VERSION ""

NS_ :

BS_:

BU_: AuxInput VT TECU TC Sprayer GPS

BO_ 2632384038 VT12_VT: 34 VT
 SG_ UnsupportedVtFunction m253 : 8|8@1+ (1,0) [0|255] "" Vector__XXX
 SG_ AssignedAttribute2OfSet1 m39 : 105|1@1+ (1,0) [0|1] "" Vector__XXX
 SG_ AssignedAttribute1OfSet1 m39 : 104|1@1+ (1,0) [0|1] "" Vector__XXX
 SG_ FunctionAttributeOfSet1 m39 : 96|8@1+ (1,0) [0|255] "" Vector__XXX
 SG_ AuxiliaryFunctionObjectID m36 : 96|16@1+ (1,0) [0|65535] "" Vector__XXX
 SG_ NumberOfInstancesOfSet1 m39 : 88|8@1+ (1,0) [0|255] "" Vector__XXX
 SG_ NumberOfDifferentSetsOfUnit1 m39 : 80|8@1+ (1,0) [0|255] "" Vector__XXX
 SG_ AuxiliaryInputObjectID m36 : 80|16@1+ (1,0) [0|65535] "" Vector__XXX
 SG_ StoreAsPreferredAssignment m36 : 79|1@1+ (1,0) [0|1] "" Vector__XXX
 SG_ ErrorCodeChangeAttribute5 m175 : 76|1@1+ (1,0) [0|1] "" Vector__XXX
 SG_ AuxiliaryFunctionType m36 : 72|4@1+ (1,0) [0|15] "" Vector__XXX
 SG_ SelfConfigurableAddress m36 : 71|1@1+ (1,0) [0|1] "" Vector__XXX
 SG_ DeviceClassInstance m36 : 67|4@1+ (1,0) [0|15] "" Vector__XXX
 SG_ IndustryGroup m36 : 64|3@1+ (1,0) [0|7] "" Vector__XXX
 SG_ FontType_ProportionalFont m195 : 63|1@1+ (1,0) [0|1] "" Vector__XXX
 SG_ FontType_FlashHidden m195 : 62|1@1+ (1,0) [0|1] "" Vector__XXX
 SG_ FontType_FlashInverted m195 : 61|1@1+ (1,0) [0|1] "" Vector__XXX
 SG_ FontType_InvertedText m195 : 60|1@1+ (1,0) [0|1] "" Vector__XXX
 SG_ ErrorCodeChangePolygonScale5 m183 : 60|1@1+ (1,0) [0|1] "" Vector__XXX
 SG_ FontType_ItalicsText m195 : 59|1@1+ (1,0) [0|1] "" Vector__XXX
 SG_ FontType_UnderlinedText m195 : 58|1@1+ (1,0) [0|1] "" Vector__XXX
 SG_ FontType_CrossedOutText m195 : 57|1@1+ (1,0) [0|1] "" Vector__XXX
 SG_ DeviceClass m36 : 57|7@1+ (1,0) [0|127] "" Vector__XXX
 SG_ OperatingState2 m38 : 57|1@1+ (1,0) [0|1] "" Vector__XXX
 SG_ VTFunctionCode m254 : 56|8@1+ (1,0) [0|255] "" Vector__XXX
 SG_ FontType_BoldText m195 : 56|1@1+ (1,0) [0|1] "" Vector__XXX
 SG_ NumberOfPhysicalSoftKeys m194 : 56|8@1+ (1,0) [0|255] "" Vector__XXX
 SG_ NumberOfRanges m193 : 56|8@1+ (1,0) [0|255] "" Vector__XXX
 SG_ ErrorCodeChangePolygonScale1 m183 : 56|1@1+ (1,0) [0|1] "" Vector__XXX
 SG_ OperatingState1 m38 : 56|1@1+ (1,0) [0|1] "" Vector__XXX
 SG_ VTBusyCode8 m254 : 55|1@1+ (1,0) [0|1] "" Vector__XXX
 SG_ FontSize_128x192 m195 : 54|1@1+ (1,0) [0|1] "" Vector__XXX
 SG_ VTBusyCode7 m254 : 54|1@1+ (1,0) [0|1] "" Vector__XXX
 SG_ FontSize_128x128 m195 : 53|1@1+ (1,0) [0|1] "" Vector__XXX
 SG_ VTBusyCode5 m254 : 52|1@1+ (1,0) [0|1] "" Vector__XXX
 SG_ FontSize_96x128 m195 : 52|1@1+ (1,0) [0|1] "" Vector__XXX
 SG_ ErrorCodeGetSupportedWideChars2 m193 : 52|1@1+ (1,0) [0|1] "" Vector__XXX
 SG_ ErrorCodeChangeListItem5 m177 : 52|1@1+ (1,0) [0|1] "" Vector__XXX
 SG_ ErrorCodeChangeListItem4 m177 : 51|1@1+ (1,0) [0|1] "" Vector__XXX
 SG_ VTBusyCode4 m254 : 51|1@1+ (1,0) [0|1] "" Vector__XXX
 SG_ FontSize_64x96 m195 : 51|1@1+ (1,0) [0|1] "" Vector__XXX
 SG_ ErrorCodeObjectPool4 m18 : 51|1@1+ (1,0) [0|1] "" Vector__XXX
 SG_ VTBusyCode3 m254 : 50|1@1+ (1,0) [0|1] "" Vector__XXX
 SG_ FontSize_64x64 m195 : 50|1@1+ (1,0) [0|1] "" Vector__XXX
 SG_ ErrorCodeChangeListItem3 m177 : 50|1@1+ (1,0) [0|1] "" Vector__XXX
 SG_ ErrorCodeObjectPool3 m18 : 50|1@1+ (1,0) [0|1] "" Vector__XXX
 SG_ VTBusyCode2 m254 : 49|1@1+ (1,0) [0|1] "" Vector__XXX
 SG_ FontSize_48x64 m195 : 49|1@1+ (1,0) [0|1] "" Vector__XXX
 SG_ ErrorCodeChangeListItem2 m177 : 49|1@1+ (1,0) [0|1] "" Vector__XXX
 SG_ ErrorCodeObjectPool2 m18 : 49|1@1+ (1,0) [0|1] "" Vector__XXX
 SG_ VTBusyCode1 m254 : 48|1@1+ (1,0) [0|1] "" Vector__XXX
 SG_ NrOfYPixelsInDataAreaMask m199 : 48|16@1+ (1,0) [0|65535] "" Vector__XXX
 SG_ FontSize_32x48 m195 : 48|1@1+ (1,0) [0|1] "" Vector__XXX
 SG_ NumberOfPossibleVirtualSoftKeys m194 : 48|8@1+ (1,0) [0|255] "" Vector__XXX
 SG_ ErrorCodeGetSupportedWideChars1 m193 : 48|1@1+ (1,0) [0|1] "" Vector__XXX
 SG_ ErrorCodeChangeListItem1 m177 : 48|1@1+ (1,0) [0|1] "" Vector__XXX
 SG_ Function m36 : 48|8@1+ (1,0) [0|255] "" Vector__XXX
 SG_ ErrorCodeObjectPool1 m18 : 48|1@1+ (1,0) [0|1] "" Vector__XXX
 SG_ VTChangeActiveMaskParentID m6 : 48|16@1+ (1,0) [0|65535] "" Vector__XXX
 SG_ ButtonKeyCode m1 : 48|8@1+ (1,0) [0|255] "" Vector__XXX
 SG_ SoftKeyCode m0 : 48|8@1+ (1,0) [0|255] "" Vector__XXX
 SG_ BooleanValue m33 : 48|8@1+ (1,0) [0|2] "" Vector__XXX
 SG_ Status_2 m9 : 48|8@1+ (1,0) [0|1] "" Vector__XXX
 SG_ ErrorCodeVTChangeSoftKeyMask6 m7 : 46|1@1+ (1,0) [0|1] "" Vector__XXX
 SG_ FontSize_32x32 m195 : 46|1@1+ (1,0) [0|1] "" Vector__XXX
 SG_ FontSize_24x32 m195 : 45|1@1+ (1,0) [0|1] "" Vector__XXX
 SG_ FontSize_16x24 m195 : 44|1@1+ (1,0) [0|1] "" Vector__XXX
 SG_ ErrorCodeChangePosInvalidError m180 : 44|1@1+ (1,0) [0|1] "" Vector__XXX
 SG_ ErrorCodeChangeSoftKeyMask5 m174 : 44|1@1+ (1,0) [0|1] "" Vector__XXX
 SG_ ErrorCodeChangeChildLocation5 m165 : 44|1@1+ (1,0) [0|1] "" Vector__XXX
 SG_ ErrorCodeVTChangeSoftKeyMask5 m7 : 44|1@1+ (1,0) [0|1] "" Vector__XXX
 SG_ ErrorCodeChangeStrValueInUse m179 : 44|1@1+ (1,0) [0|1] "" Vector__XXX
 SG_ ErrorCodeVtObjPoolError4 m240 : 43|1@1+ (1,0) [0|1] "" Vector__XXX
 SG_ FontSize_16x16 m195 : 43|1@1+ (1,0) [0|1] "" Vector__XXX
 SG_ ErrorCodeChangeStrError m179 : 43|1@1+ (1,0) [0|1] "" Vector__XXX
 SG_ ErrorCodeChangeSoftKeyMask4 m174 : 43|1@1+ (1,0) [0|1] "" Vector__XXX
 SG_ FunctionInstance m36 : 43|5@1+ (1,0) [0|31] "" Vector__XXX
 SG_ ErrorCodeVTChangeSoftKeyMask4 m7 : 43|1@1+ (1,0) [0|1] "" Vector__XXX
 SG_ ErrorCodeVtObjPoolError3 m240 : 42|1@1+ (1,0) [0|1] "" Vector__XXX
 SG_ FontSize_12x16 m195 : 42|1@1+ (1,0) [0|1] "" Vector__XXX
 SG_ ErrorCodeChangeStrTooLong m179 : 42|1@1+ (1,0) [0|1] "" Vector__XXX
 SG_ ErrorCodeChangeSoftKeyMask3 m174 : 42|1@1+ (1,0) [0|1] "" Vector__XXX
 SG_ ErrorCodeVTChangeSoftKeyMask3 m7 : 42|1@1+ (1,0) [0|1] "" Vector__XXX
 SG_ ErrorCodeVtObjPoolError2 m240 : 41|1@1+ (1,0) [0|1] "" Vector__XXX
 SG_ FontSize_8x12 m195 : 41|1@1+ (1,0) [0|1] "" Vector__XXX
 SG_ ErrorCodeChangePosInvalidObject m180 : 41|1@1+ (1,0) [0|1] "" Vector__XXX
 SG_ ErrorCodeChangeStrObjectID m179 : 41|1@1+ (1,0) [0|1] "" Vector__XXX
 SG_ ErrorCodeChangeSoftKeyMask2 m174 : 41|1@1+ (1,0) [0|1] "" Vector__XXX
 SG_ ErrorCodeChangeChildLocation2 m165 : 41|1@1+ (1,0) [0|1] "" Vector__XXX
 SG_ ErrorCodeVTChangeSoftKeyMask2 m7 : 41|1@1+ (1,0) [0|1] "" Vector__XXX
 SG_ ErrorCodeVtObjPoolError1 m240 : 40|1@1+ (1,0) [0|1] "" Vector__XXX
 SG_ AcknowledgmentDeleteVersion m210 : 40|4@1+ (1,0) [0|8] "" Vector__XXX
 SG_ AcknowledgmentLoadVersion m209 : 40|4@1+ (1,0) [0|8] "" Vector__XXX
 SG_ AcknowledgmentStoreVersion m208 : 40|4@1+ (1,0) [0|8] "" Vector__XXX
 SG_ FontSize_8x8 m195 : 40|1@1+ (1,0) [0|1] "" Vector__XXX
 SG_ YDotsForSoftKeyDescriptor m194 : 40|8@1+ (1,0) [0|255] "" Vector__XXX
 SG_ NewHeigthAttribute m183 : 40|16@1+ (1,0) [0|0] "" Vector__XXX
 SG_ ErrorCodeChangePosInvalidParent m180 : 40|1@1+ (1,0) [0|1] "" Vector__XXX
 SG_ ErrorCodeChangeSoftKeyMask1 m174 : 40|1@1+ (1,0) [0|1] "" Vector__XXX
 SG_ ErrorCodeChangeChildLocation1 m165 : 40|1@1+ (1,0) [0|1] "" Vector__XXX
 SG_ Value2 m38 : 40|16@1+ (1,0) [0|65535] "" Vector__XXX
 SG_ ECUInstance m36 : 40|3@1+ (1,0) [0|7] "" Vector__XXX
 SG_ TouchState m2 : 40|8@1+ (1,0) [0|255] "" Vector__XXX
 SG_ ErrorCodeVTChangeSoftKeyMask1 m7 : 40|1@1+ (1,0) [0|1] "" Vector__XXX
 SG_ ErrorCodeSelectObject6 m162 : 37|1@1+ (1,0) [0|1] "" Vector__XXX
 SG_ ErrorCodeGraphicsContextCmd5 m184 : 36|1@1+ (1,0) [0|1] "" Vector__XXX
 SG_ ErrorCodeChangePriority3 m176 : 36|1@1+ (1,0) [0|1] "" Vector__XXX
 SG_ ErrorCodeChangeAttribute4 m175 : 35|1@1+ (1,0) [0|1] "" Vector__XXX
 SG_ ErrorCodeChangeColour3 m167 : 36|1@1+ (1,0) [0|1] "" Vector__XXX
 SG_ ErrorCodeSelectObject5 m162 : 36|1@1+ (1,0) [0|1] "" Vector__XXX
 SG_ ErrorCodeEnableDisableObj4 m161 : 36|1@1+ (1,0) [0|1] "" Vector__XXX
 SG_ ErrorCodeGraphicsContextCmd4 m184 : 35|1@1+ (1,0) [0|1] "" Vector__XXX
 SG_ ErrorCodeSelectObject4 m162 : 35|1@1+ (1,0) [0|1] "" Vector__XXX
 SG_ ErrorCodeEnableDisableObj3 m161 : 35|1@1+ (1,0) [0|1] "" Vector__XXX
 SG_ ErrorCodeHideShowObj3 m160 : 35|1@1+ (1,0) [0|1] "" Vector__XXX
 SG_ ErrorCodeGraphicsContextCmd3 m184 : 34|1@1+ (1,0) [0|1] "" Vector__XXX
 SG_ ErrorCodeChangeAttribute3 m175 : 34|1@1+ (1,0) [0|1] "" Vector__XXX
 SG_ ErrorCodeSelectObject3 m162 : 34|1@1+ (1,0) [0|1] "" Vector__XXX
 SG_ ErrorCodeEnableDisableObj2 m161 : 34|1@1+ (1,0) [0|1] "" Vector__XXX
 SG_ ErrorCodeGraphicsContextCmd2 m184 : 33|1@1+ (1,0) [0|1] "" Vector__XXX
 SG_ ErrorCodeChangePriority2 m176 : 33|1@1+ (1,0) [0|1] "" Vector__XXX
 SG_ ErrorCodeChangeAttribute2 m175 : 33|1@1+ (1,0) [0|1] "" Vector__XXX
 SG_ ErrorCodeChangeColour2 m167 : 33|1@1+ (1,0) [0|1] "" Vector__XXX
 SG_ ErrorCodeSelectObject2 m162 : 33|1@1+ (1,0) [0|1] "" Vector__XXX
 SG_ ErrorCodeEnableDisableObj1 m161 : 33|1@1+ (1,0) [0|1] "" Vector__XXX
 SG_ ErrorCodeHideShowObj2 m160 : 33|1@1+ (1,0) [0|1] "" Vector__XXX
 SG_ VisibleSoftKeyMaskObjectID m254 : 32|16@1+ (1,0) [0|65535] "" Vector__XXX
 SG_ NrOfXPixelsInDataAreaMask m199 : 32|16@1+ (1,0) [0|65535] "" Vector__XXX
 SG_ XDotsForSoftKeyDescriptor m194 : 32|8@1+ (1,0) [0|255] "" Vector__XXX
 SG_ LastWideChar m193 : 32|16@1+ (1,0) [0|65535] "" Vector__XXX
 SG_ ErrorCodeGraphicsContextCmd1 m184 : 32|1@1+ (1,0) [0|1] "" Vector__XXX
 SG_ NewObjectID m177 : 32|16@1+ (1,0) [0|65535] "" Vector__XXX
 SG_ ErrorCodeChangePriority1 m176 : 32|1@1+ (1,0) [0|1] "" Vector__XXX
 SG_ ErrorCodeChangeAttribute1 m175 : 32|1@1+ (1,0) [0|1] "" Vector__XXX
 SG_ ValueOfTheObject m168 : 32|32@1+ (1,0) [0|2704] "" Vector__XXX
 SG_ ErrorCodeChangeColour1 m167 : 32|1@1+ (1,0) [0|1] "" Vector__XXX
 SG_ ErrorCodeSelectObject1 m162 : 32|1@1+ (1,0) [0|1] "" Vector__XXX
 SG_ ErrorCodeHideShowObj1 m160 : 32|1@1+ (1,0) [0|1] "" Vector__XXX
 SG_ ObjectIdOfFaultyObject m18 : 32|16@1+ (1,0) [0|65535] "" Vector__XXX
 SG_ VTChangeActiveMaskErrorID m6 : 32|16@1+ (1,0) [0|65535] "" Vector__XXX
 SG_ VTChangeNumericValueValue m5 : 32|32@1+ (1,0) [0|4294967295] "" Vector__XXX
 SG_ VTSelectInputObjectIsEdited m3 : 32|1@1+ (1,0) [0|1] "" Vector__XXX
 SG_ ButtonObjectParentID m1 : 32|16@1+ (1,0) [0|65535] "" Vector__XXX
 SG_ KeyObjectParentID m0 : 32|16@1+ (1,0) [0|65535] "" Vector__XXX
 SG_ NumTransitionsDisabledToEnabled m33 : 32|16@1+ (1,0) [0|65535] "" Vector__XXX
 SG_ ObjectID_2 m9 : 32|16@1+ (1,0) [0|65535] "" Vector__XXX
 SG_ Hardware6 m199 : 29|1@1+ (1,0) [0|1] "" Vector__XXX
 SG_ ErrorCodeChangeFont6 m170 : 29|1@1+ (1,0) [0|1] "" Vector__XXX
 SG_ ManufacturerCode m36 : 29|11@1+ (1,0) [0|2047] "" Vector__XXX
 SG_ ErrorCodePoolDeleted m6 : 29|1@1+ (1,0) [0|1] "" Vector__XXX
 SG_ Hardware5 m199 : 28|1@1+ (1,0) [0|1] "" Vector__XXX
 SG_ ErrorCodeChangeActiveMask5 m173 : 28|1@1+ (1,0) [0|1] "" Vector__XXX
 SG_ ErrorCodeChangeFillAttributes5 m172 : 28|1@1+ (1,0) [0|1] "" Vector__XXX
 SG_ ErrorCodeChangeLineAttribute4 m171 : 28|1@1+ (1,0) [0|1] "" Vector__XXX
 SG_ ErrorCodeChangeFont5 m170 : 28|1@1+ (1,0) [0|1] "" Vector__XXX
 SG_ ErrorCodeChangeEditPoint3 m169 : 28|1@1+ (1,0) [0|1] "" Vector__XXX
 SG_ ErrorCodeObjToSize4 m166 : 28|1@1+ (1,0) [0|1] "" Vector__XXX
 SG_ ErrorCodeEscapeObj2 m146 : 28|1@1+ (1,0) [0|1] "" Vector__XXX
 SG_ ErrorCodeAnyOtherError m6 : 28|1@1+ (1,0) [0|1] "" Vector__XXX
 SG_ ErrorCodeVTEsc2 m4 : 28|1@1+ (1,0) [0|1] "" Vector__XXX
 SG_ ErrorCodeChangeNumValue4 m168 : 28|1@1+ (1,0) [0|1] "" Vector__XXX
 SG_ Hardware4 m199 : 27|1@1+ (1,0) [0|1] "" Vector__XXX
 SG_ ErrorCodeChangeActiveMask4 m173 : 27|1@1+ (1,0) [0|1] "" Vector__XXX
 SG_ ErrorCodeChangeFillAttributes4 m172 : 27|1@1+ (1,0) [0|1] "" Vector__XXX
 SG_ ErrorCodeChangeFont4 m170 : 27|1@1+ (1,0) [0|1] "" Vector__XXX
 SG_ ErrorCodeMaskOrChildObjectError m6 : 27|1@1+ (1,0) [0|1] "" Vector__XXX
 SG_ ErrorCodeChangeNumValue3 m168 : 26|1@1+ (1,0) [0|1] "" Vector__XXX
 SG_ Hardware3 m199 : 26|1@1+ (1,0) [0|1] "" Vector__XXX
 SG_ ErrorCodeChangePoygonPoint3 m182 : 26|1@1+ (1,0) [0|1] "" Vector__XXX
 SG_ ErrorCodeChangeActiveMask3 m173 : 26|1@1+ (1,0) [0|1] "" Vector__XXX
 SG_ ErrorCodeChangeFillAttributes3 m172 : 26|1@1+ (1,0) [0|1] "" Vector__XXX
 SG_ ErrorCodeChangeLineAttribute3 m171 : 26|1@1+ (1,0) [0|1] "" Vector__XXX
 SG_ ErrorCodeChangeFont3 m170 : 26|1@1+ (1,0) [0|1] "" Vector__XXX
 SG_ ErrorCodeObjToSize3 m166 : 26|1@1+ (1,0) [0|1] "" Vector__XXX
 SG_ ErrorCodeMissingObjects m6 : 26|1@1+ (1,0) [0|1] "" Vector__XXX
 SG_ ErrorCodeExecuteExtendedMacro3 m188 : 26|1@1+ (1,0) [0|1] "" Vector__XXX
 SG_ Hardware2 m199 : 25|1@1+ (1,0) [0|1] "" Vector__XXX
 SG_ ErrorCodeSelectColourMap2 m186 : 25|1@1+ (1,0) [0|1] "" Vector__XXX
 SG_ ErrorCodeChangePoygonPoint2 m182 : 25|1@1+ (1,0) [0|1] "" Vector__XXX
 SG_ ErrorCodeChangeActiveMask2 m173 : 25|1@1+ (1,0) [0|1] "" Vector__XXX
 SG_ ErrorCodeChangeFillAttributes2 m172 : 25|1@1+ (1,0) [0|1] "" Vector__XXX
 SG_ ErrorCodeChangeLineAttribute2 m171 : 25|1@1+ (1,0) [0|1] "" Vector__XXX
 SG_ ErrorCodeChangeFont2 m170 : 25|1@1+ (1,0) [0|1] "" Vector__XXX
 SG_ ErrorCodeChangeEditPoint2 m169 : 25|1@1+ (1,0) [0|1] "" Vector__XXX
 SG_ ErrorCodeChangeNumValue2 m168 : 25|1@1+ (1,0) [0|1] "" Vector__XXX
 SG_ ErrorCodeObjToSize2 m166 : 25|1@1+ (1,0) [0|1] "" Vector__XXX
 SG_ ErrorCodeExecuteExtendedMacro2 m188 : 25|1@1+ (1,0) [0|1] "" Vector__XXX
 SG_ ObjectIDOfFaultyObject m240 : 24|16@1+ (1,0) [0|65535] "" Vector__XXX
 SG_ Hardware1 m199 : 24|1@1+ (1,0) [0|1] "" Vector__XXX
 SG_ ErrorCodeSelectColourMap1 m186 : 24|1@1+ (1,0) [0|1] "" Vector__XXX
 SG_ AttributeID m185 : 24|8@1+ (1,0) [0|0] "" Vector__XXX
 SG_ SubCommandID m184 : 24|8@1+ (1,0) [0|0] "" Vector__XXX
 SG_ NewWidthAttribute m183 : 24|16@1+ (1,0) [0|65535] "" Vector__XXX
 SG_ ErrorCodeChangePoygonPoint1 m182 : 24|1@1+ (1,0) [0|1] "" Vector__XXX
 SG_ ChangeChildPositionObjectID m180 : 24|16@1+ (1,0) [0|65535] "" Vector__XXX
 SG_ ChangeStringValueObjectID m179 : 24|16@1+ (1,0) [0|65535] "" Vector__XXX
 SG_ ListIndex m177 : 24|8@1+ (1,0) [0|255] "" Vector__XXX
 SG_ NewPriority m176 : 24|8@1+ (1,0) [0|255] "" Vector__XXX
 SG_ AttributeToChangeID m175 : 24|8@1+ (1,0) [0|65535] "" Vector__XXX
 SG_ SoftKeyMaskObjectID m174 : 24|16@1+ (1,0) [0|65535] "" Vector__XXX
 SG_ ErrorCodeChangeActiveMask1 m173 : 24|1@1+ (1,0) [0|1] "" Vector__XXX
 SG_ ErrorCodeChangeFillAttributes1 m172 : 24|1@1+ (1,0) [0|1] "" Vector__XXX
 SG_ ErrorCodeChangeLineAttribute1 m171 : 24|1@1+ (1,0) [0|1] "" Vector__XXX
 SG_ ErrorCodeChangeFont1 m170 : 24|1@1+ (1,0) [0|1] "" Vector__XXX
 SG_ ErrorCodeChangeEditPoint1 m169 : 24|1@1+ (1,0) [0|1] "" Vector__XXX
 SG_ ErrorCodeChangeNumValue1 m168 : 24|1@1+ (1,0) [0|1] "" Vector__XXX
 SG_ NewBackgroundColour m167 : 24|8@1+ (1,0) [0|255] "" Vector__XXX
 SG_ ErrorCodeObjToSize1 m166 : 24|1@1+ (1,0) [0|1] "" Vector__XXX
 SG_ ChangeChildLocationObjectID m165 : 24|16@1+ (1,0) [0|65535] "" Vector__XXX
 SG_ ObjectSelectStatus m162 : 24|8@1+ (1,0) [0|2] "" Vector__XXX
 SG_ ObjectEnableStatus m161 : 24|8@1+ (1,0) [0|1] "" Vector__XXX
 SG_ ObjectShowStatus m160 : 24|8@1+ (1,0) [0|1] "" Vector__XXX
 SG_ ErrorCodeEscapeObj1 m146 : 24|1@1+ (1,0) [0|1] "" Vector__XXX
 SG_ AuxInputEnable m37 : 24|8@1+ (1,0) [0|1] "" Vector__XXX
 SG_ Value1 m38 : 24|16@1+ (1,0) [0|65535] "" Vector__XXX
 SG_ EnteredStringValue m8 : 24|8@1+ (1,0) [0|255] "" Vector__XXX
 SG_ VTChangeSoftKeyMaskObjectID m7 : 24|16@1+ (1,0) [0|65535] "" Vector__XXX
 SG_ ErrorCodeVTEsc1 m4 : 24|1@1+ (1,0) [0|1] "" Vector__XXX
 SG_ VTSelectInputObjectStatus m3 : 24|8@1+ (1,0) [0|1] "" Vector__XXX
 SG_ YPosition m2 : 24|16@1+ (1,0) [0|65535] "" Vector__XXX
 SG_ Status_1 m9 : 24|8@1+ (1,0) [0|1] "" Vector__XXX
 SG_ ErrorCodeExecuteExtendedMacro1 m188 : 24|1@1+ (1,0) [0|1] "" Vector__XXX
 SG_ ErrorCodeLockUnlockMask8 m189 : 23|1@1+ (1,0) [0|1] "" Vector__XXX
 SG_ ErrorCodeLockUnlockMask7 m189 : 22|1@1+ (1,0) [0|1] "" Vector__XXX
 SG_ ErrorCodeLockUnlockMask6 m189 : 21|1@1+ (1,0) [0|1] "" Vector__XXX
 SG_ ErrorCodeLockUnlockMask5 m189 : 20|1@1+ (1,0) [0|1] "" Vector__XXX
 SG_ ErrorCodeLockUnlockMask4 m189 : 19|1@1+ (1,0) [0|1] "" Vector__XXX
 SG_ ErrorCodeExecuteMacro3 m190 : 18|1@1+ (1,0) [0|1] "" Vector__XXX
 SG_ ErrorCodeLockUnlockMask3 m189 : 18|1@1+ (1,0) [0|1] "" Vector__XXX
 SG_ ErrorCodeExecuteMacro2 m190 : 17|1@1+ (1,0) [0|1] "" Vector__XXX
 SG_ ErrorCodeLockUnlockMask2 m189 : 17|1@1+ (1,0) [0|1] "" Vector__XXX
 SG_ NameOfAuxiliaryUnit1 m39 : 16|64@1+ (1,0) [0|0] "" Vector__XXX
 SG_ ExtendedVersionLables m211 : 16|256@1+ (1,0) [0|7.20575940379279E+016] "" Vector__XXX
 SG_ VisibleDataOrAlarmMaskObjectID m254 : 16|16@1+ (1,0) [0|65535] "" Vector__XXX
 SG_ VersionLables m224 : 16|56@1+ (1,0) [0|0] "" Vector__XXX
 SG_ SupportedGraphicMode m199 : 16|8@1+ (1,0) [0|2] "" Vector__XXX
 SG_ FirstWideChar m193 : 16|16@1+ (1,0) [0|65535] "" Vector__XXX
 SG_ MemoryStatus m192 : 16|8@1+ (1,0) [0|1] "" Vector__XXX
 SG_ ErrorCodeExecuteMacro1 m190 : 16|1@1+ (1,0) [0|1] "" Vector__XXX
 SG_ ErrorCodeLockUnlockMask1 m189 : 16|1@1+ (1,0) [0|1] "" Vector__XXX
 SG_ ParentObjectIDOfFaultyObject m18 : 16|16@1+ (1,0) [0|65535] "" Vector__XXX
 SG_ ButtonObjectID m1 : 16|16@1+ (1,0) [0|65535] "" Vector__XXX
 SG_ KeyObjectID m0 : 16|16@1+ (1,0) [0|65535] "" Vector__XXX
 SG_ AuxFunctObjOfFaultyAssignment m34 : 16|16@1- (1,0) [0|65535] "" Vector__XXX
 SG_ AnalogValue m33 : 16|16@1+ (1,0) [0|65535] "" Vector__XXX
 SG_ BckgndColourUserLayoutSoftk_0000 m196 : 16|8@1+ (1,0) [0|255] "" Vector__XXX
 SG_ ErrorCodeSetObjectLabel6 m181 : 13|1@1+ (1,0) [0|1] "" Vector__XXX
 SG_ ErrorCodeSetObjectLabel5 m181 : 12|1@1+ (1,0) [0|1] "" Vector__XXX
 SG_ ErrorCodeDeleteObjectPool2 m178 : 12|1@1+ (1,0) [0|1] "" Vector__XXX
 SG_ ErrorCodeAudioVolume2 m164 : 12|1@1+ (1,0) [0|1] "" Vector__XXX
 SG_ ErrorCodeControlAudioDevice2 m163 : 12|1@1+ (1,0) [0|1] "" Vector__XXX
 SG_ ErrorCodeEndOfObjectPool3 m18 : 12|1@1+ (1,0) [0|1] "" Vector__XXX
 SG_ AuxPreferredAssignmentRespError5 m34 : 12|1@1+ (1,0) [0|1] "" Vector__XXX
 SG_ ErrorCodeSetObjectLabel4 m181 : 11|1@1+ (1,0) [0|1] "" Vector__XXX
 SG_ AuxPreferredAssignmentRespError4 m34 : 11|1@1+ (1,0) [0|1] "" Vector__XXX
 SG_ ErrorCodeSetObjectLabel3 m181 : 10|1@1+ (1,0) [0|1] "" Vector__XXX
 SG_ AuxPreferredAssignmentRespError3 m34 : 10|1@1+ (1,0) [0|1] "" Vector__XXX
 SG_ ErrorCodeSetObjectLabel2 m181 : 9|1@1+ (1,0) [0|1] "" Vector__XXX
 SG_ AuxPreferredAssignmentRespError2 m34 : 9|1@1+ (1,0) [0|1] "" Vector__XXX
 SG_ ErrorCodeEndOfObjectPool2 m18 : 9|1@1+ (1,0) [0|1] "" Vector__XXX
 SG_ SourceAdressOfActiveWSM m254 : 8|8@1+ (1,0) [0|255] "" Vector__XXX
 SG_ ParentIDOfFaultyObject m240 : 8|16@1+ (1,0) [0|65535] "" Vector__XXX
 SG_ NrOfVersionStrings m224 : 8|8@1+ (1,0) [0|255] "" Vector__XXX
 SG_ NavigationSoftKeys m194 : 8|8@1+ (1,0) [0|254] "" Vector__XXX
 SG_ CodePlane m193 : 8|8@1+ (1,0) [0|16] "" Vector__XXX
 SG_ VersionNumberISO11783Part6 m192 : 8|8@1+ (1,0) [0|255] "" Vector__XXX
 SG_ MacroObjectID m190 : 8|8@1+ (1,0) [0|255] "" Vector__XXX
 SG_ LockUnlockCommand m189 : 8|8@1+ (1,0) [0|1] "" Vector__XXX
 SG_ ColourMapObjectID m186 : 8|16@1+ (1,0) [0|65535] "" Vector__XXX
 SG_ ObjectToGetAttributeID m185 : 8|16@1+ (1,0) [0|65535] "" Vector__XXX
 SG_ GraphicsContextObjectID m184 : 8|16@1+ (1,0) [0|65535] "" Vector__XXX
 SG_ PolygonObjectToScaleID m183 : 8|16@1+ (1,0) [0|65535] "" Vector__XXX
 SG_ PolygonObjectToChangeID m182 : 8|16@1+ (1,0) [0|65535] "" Vector__XXX
 SG_ ErrorCodeSetObjectLabel1 m181 : 8|1@1+ (1,0) [0|1] "" Vector__XXX
 SG_ ChangeChildPositionParentOb_0000 m180 : 8|16@1+ (1,0) [0|65535] "" Vector__XXX
 SG_ ErrorCodeDeleteObjectPool1 m178 : 8|1@1+ (1,0) [0|1] "" Vector__XXX
 SG_ ListInputObjectID m177 : 8|16@1+ (1,0) [0|65535] "" Vector__XXX
 SG_ AlarmMaskObjectID m176 : 8|16@1+ (1,0) [0|65535] "" Vector__XXX
 SG_ ObjectToChangeAttributeID m175 : 8|16@1+ (1,0) [0|65535] "" Vector__XXX
 SG_ DataOrAlarmMaskObjectID m174 : 8|16@1+ (1,0) [0|65535] "" Vector__XXX
 SG_ ActiveMaskObjectID m173 : 8|16@1+ (1,0) [0|0] "" Vector__XXX
 SG_ ObjectToChangeFillAttributesID m172 : 8|16@1+ (1,0) [0|65535] "" Vector__XXX
 SG_ ObjectToChangeLineAttributeID m171 : 8|16@1+ (1,0) [0|65535] "" Vector__XXX
 SG_ ObjectToChangeFontID m170 : 8|16@1+ (1,0) [0|65535] "" Vector__XXX
 SG_ ObjectToChangeEndPointID m169 : 8|16@1+ (1,0) [0|65535] "" Vector__XXX
 SG_ ObjectToChangeNumValueID m168 : 8|16@1+ (1,0) [0|65535] "" Vector__XXX
 SG_ ObjectToChangeColourID m167 : 8|16@1+ (1,0) [0|65535] "" Vector__XXX
 SG_ ObjectToSizeID m166 : 8|16@1+ (1,0) [0|65535] "" Vector__XXX
 SG_ ChangeChildLocationParentOb_0000 m165 : 8|16@1+ (1,0) [0|65535] "" Vector__XXX
 SG_ ErrorCodeAudioVolume1 m164 : 8|1@1+ (1,0) [0|1] "" Vector__XXX
 SG_ ErrorCodeControlAudioDevice1 m163 : 8|1@1+ (1,0) [0|1] "" Vector__XXX
 SG_ SelectInputObjectID m162 : 8|16@1+ (1,0) [0|65535] "" Vector__XXX
 SG_ ObjectToEnableDisableID m161 : 8|16@1+ (1,0) [0|65535] "" Vector__XXX
 SG_ ObjectToHideShowID m160 : 8|16@1+ (1,0) [0|65535] "" Vector__XXX
 SG_ ObjectEscapeID m146 : 8|16@1+ (1,0) [0|65535] "" Vector__XXX
 SG_ InputStatusObjectId m37 : 8|16@1+ (1,0) [0|255] "" Vector__XXX
 SG_ AuxPreferredAssignmentRespError1 m34 : 8|1@1+ (1,0) [0|1] "" Vector__XXX
 SG_ InputObjectId m38 : 8|16@1+ (1,0) [0|255] "" Vector__XXX
 SG_ IdentityNumber m36 : 8|21@1+ (1,0) [0|2097150] "" Vector__XXX
 SG_ ErrorCodeEndOfObjectPool1 m18 : 8|1@1+ (1,0) [0|1] "" Vector__XXX
 SG_ ObjectToChangeStringID m8 : 8|16@1+ (1,0) [0|65535] "" Vector__XXX
 SG_ VTChangeSoftKeyMaskParentID m7 : 8|16@1+ (1,0) [0|65535] "" Vector__XXX
 SG_ VTChangeActiveMaskObjectID m6 : 8|16@1+ (1,0) [0|65535] "" Vector__XXX
 SG_ VTChangeNumericValueObjectID m5 : 8|16@1+ (1,0) [0|65535] "" Vector__XXX
 SG_ VTEscObjectID m4 : 8|16@1+ (1,0) [0|65535] "" Vector__XXX
 SG_ VTSelectInputObjectID m3 : 8|16@1+ (1,0) [0|65535] "" Vector__XXX
 SG_ XPosition m2 : 8|16@1+ (1,0) [0|65535] "" Vector__XXX
 SG_ ButtonActivationCode m1 : 8|8@1+ (1,0) [0|2] "" Vector__XXX
 SG_ KeyActivationCode m0 : 8|8@1+ (1,0) [0|2] "" Vector__XXX
 SG_ TerminationCause m10 : 8|8@1+ (1,0) [0|255] "" Vector__XXX
 SG_ InputNumber m33 : 8|8@1+ (1,0) [0|250] "" Vector__XXX
 SG_ ObjectID_1 m9 : 8|16@1+ (1,0) [0|65535] "" Vector__XXX
 SG_ BckgndColourUserLayoutDataMask m196 : 8|8@1+ (1,0) [0|255] "" Vector__XXX
 SG_ NumberOfSupportedObjects m197 : 8|8@1+ (1,0) [0|255] "" Vector__XXX
 SG_ BootTime m199 : 8|8@1+ (1,0) [0|255] "s" Vector__XXX
 SG_ NumberOfAuxiliaryUnits m39 : 8|8@1+ (1,0) [0|255] "" Vector__XXX
 SG_ MacroObjectID_2 m188 : 8|16@1+ (1,0) [0|65535] "" Vector__XXX
 SG_ VTFunctionVTtoECU M : 0|8@1+ (1,0) [0|255] ""  Sprayer

BO_ 2565340800 VT21_Sprayer: 8 Sprayer
 SG_ VTFunctionECUtoVT M : 0|8@1+ (1,0) [0|255] ""  VT
 SG_ KeyActivationCode m0 : 8|8@1+ (1,0) [0|2] "" Vector__XXX
 SG_ KeyObjectParentID m0 : 32|16@1+ (1,0) [0|65535] "" Vector__XXX
 SG_ KeyObjectID m0 : 16|16@1+ (1,0) [0|65535] "" Vector__XXX
 SG_ SoftKeyCode m0 : 48|8@1+ (1,0) [0|255] "" Vector__XXX
 SG_ ButtonActivationCode m1 : 8|8@1+ (1,0) [0|2] "" Vector__XXX
 SG_ ButtonObjectID m1 : 16|16@1+ (1,0) [0|65535] "" Vector__XXX
 SG_ ButtonObjectParentID m1 : 32|16@1+ (1,0) [0|65535] "" Vector__XXX
 SG_ ButtonKeyCode m1 : 48|8@1+ (1,0) [0|255] "" Vector__XXX
 SG_ XPosition m2 : 8|16@1+ (1,0) [0|65535] "" Vector__XXX
 SG_ YPosition m2 : 24|16@1+ (1,0) [0|65535] "" Vector__XXX
 SG_ TouchState m2 : 40|8@1+ (1,0) [0|255] "" Vector__XXX
 SG_ VTSelectInputObjectID m3 : 8|16@1+ (1,0) [0|65535] "" Vector__XXX
 SG_ VTSelectInputObjectStatus m3 : 24|8@1+ (1,0) [0|1] "" Vector__XXX
 SG_ VTEscObjectID m4 : 8|16@1+ (1,0) [0|65535] "" Vector__XXX
 SG_ VTChangeNumericValueObjectID m5 : 8|16@1+ (1,0) [0|65535] "" Vector__XXX
 SG_ VTChangeNumericValueValue m5 : 32|32@1+ (1,0) [0|4294967295] "" Vector__XXX
 SG_ VTChangeActiveMaskObjectID m6 : 8|16@1+ (1,0) [0|65535] "" Vector__XXX
 SG_ VTChangeSoftKeyMaskParentID m7 : 8|16@1+ (1,0) [0|65535] "" Vector__XXX
 SG_ VTChangeSoftKeyMaskObjectID m7 : 24|16@1+ (1,0) [0|65535] "" Vector__XXX
 SG_ ObjectToChangeStringValueID m8 : 24|16@1+ (1,0) [0|65535] "" Vector__XXX
 SG_ DisplayActivationStatus1 m9 : 8|1@1+ (1,0) [0|1] "" Vector__XXX
 SG_ VisibleDataAlarmMaskID m9 : 16|16@1+ (1,0) [0|65535] "" Vector__XXX
 SG_ VisibleSoftKeyMaskID m9 : 32|16@1+ (1,0) [0|65535] "" Vector__XXX
 SG_ ObjectPoolRecord m17 : 8|56@1+ (1,0) [0|3338120000] "" Vector__XXX
 SG_ AuxiliaryFunctionObjectID m32 : 8|16@1+ (1,0) [0|65535] "" Vector__XXX
 SG_ AssignmentErrorNotAccepted m32 : 24|1@1+ (1,0) [0|1] "" Vector__XXX
 SG_ NumberOfInpuUnits m34 : 8|8@1+ (1,0) [0|255] "" Vector__XXX
 SG_ IsEnabled m33 : 48|8@1+ (1,0) [0|255] "" Vector__XXX
 SG_ AuxModelIdentification m35 : 8|16@1+ (1,0) [0|65535] "" Vector__XXX
 SG_ InputStatusObjectId m37 : 8|16@1+ (1,0) [0|255] "" Vector__XXX
 SG_ AuxInputEnable m37 : 24|8@1+ (1,0) [0|1] "" Vector__XXX
 SG_ AuxErrorInvalidInputID m37 : 32|1@1+ (1,0) [0|1] "" Vector__XXX
 SG_ AuxErrorAnyOther m37 : 33|1@1+ (1,0) [0|1] "" Vector__XXX
 SG_ ObjectToShowHideID m160 : 8|16@1+ (1,0) [0|65535] "" Vector__XXX
 SG_ ShowOrHide m160 : 24|8@1+ (1,0) [0|1] "" Vector__XXX
 SG_ ObjectoEnableDisbaleID m161 : 8|16@1+ (1,0) [0|65535] "" Vector__XXX
 SG_ EnableOrDisable m161 : 24|8@1+ (1,0) [0|1] "" Vector__XXX
 SG_ SelectInputObjectID m162 : 8|16@1+ (1,0) [0|65535] "" Vector__XXX
 SG_ SetFocusOpenForEditing m162 : 24|8@1+ (1,0) [0|255] "" Vector__XXX
 SG_ NumberOfRepetitions_Audio m163 : 8|8@1+ (1,0) [0|255] "" Vector__XXX
 SG_ Frequency_Audio m163 : 16|16@1+ (1,0) [0|65535] "hz" Vector__XXX
 SG_ OnTimeDuration_Audio m163 : 32|16@1+ (1,0) [0|65535] "ms" Vector__XXX
 SG_ OffTimeDuration_Audio m163 : 48|16@1+ (1,0) [0|65535] "ms" Vector__XXX
 SG_ AudioVolume m164 : 8|8@1+ (1,0) [0|100] "%" Vector__XXX
 SG_ ParentObjectID m165 : 8|16@1+ (1,0) [0|65535] "" Vector__XXX
 SG_ ObjectToMoveID m165 : 24|16@1+ (1,0) [0|65535] "" Vector__XXX
 SG_ XPosChangeTopLeft m165 : 40|8@1+ (1,-127) [-127|128] "" Vector__XXX
 SG_ YPosChangeTopLeft m165 : 48|8@1+ (1,-127) [-127|128] "" Vector__XXX
 SG_ ObjectToSizeID m166 : 8|16@1+ (1,0) [0|65535] "" Vector__XXX
 SG_ NewWidth m166 : 24|16@1+ (1,0) [0|65535] "" Vector__XXX
 SG_ NewHeight m166 : 40|16@1+ (1,0) [0|65535] "" Vector__XXX
 SG_ ObjectToChangeColourID m167 : 8|16@1+ (1,0) [0|65535] "" Vector__XXX
 SG_ NewBackgroundColour m167 : 24|8@1+ (1,0) [0|255] "" Vector__XXX
 SG_ ObjectToChangeNumValueID m168 : 8|16@1+ (1,0) [0|65535] "" Vector__XXX
 SG_ NewValue m168 : 32|32@1+ (1,0) [0|65535] "" Vector__XXX
 SG_ ObjectToChangeEndPointID m169 : 8|16@1+ (1,0) [0|65535] "" Vector__XXX
 SG_ Width m169 : 24|16@1+ (1,0) [0|65535] "" Vector__XXX
 SG_ Height m169 : 40|16@1+ (1,0) [0|65535] "" Vector__XXX
 SG_ LineDirection m169 : 56|8@1+ (1,0) [0|1] "" Vector__XXX
 SG_ ObjectToChangeFontID m170 : 8|16@1+ (1,0) [0|65535] "" Vector__XXX
 SG_ FontColour m170 : 24|8@1+ (1,0) [0|255] "" Vector__XXX
 SG_ FontSize m170 : 32|8@1+ (1,0) [0|255] "" Vector__XXX
 SG_ FontType m170 : 40|8@1+ (1,0) [0|255] "" Vector__XXX
 SG_ FontStyle m170 : 48|8@1+ (1,0) [0|255] "" Vector__XXX
 SG_ ObjectToChangeLineAttributesID m171 : 8|16@1+ (1,0) [0|65535] "" Vector__XXX
 SG_ LineColour m171 : 24|8@1+ (1,0) [0|255] "" Vector__XXX
 SG_ LineWidth m171 : 32|8@1+ (1,0) [0|255] "" Vector__XXX
 SG_ LineArt m171 : 40|16@1+ (1,0) [0|65535] "" Vector__XXX
 SG_ ObjectToChangeFillAttributesID m172 : 8|16@1+ (1,0) [0|65535] "" Vector__XXX
 SG_ FillType m172 : 24|8@1+ (1,0) [0|255] "" Vector__XXX
 SG_ FillColour m172 : 32|8@1+ (1,0) [0|255] "" Vector__XXX
 SG_ FillPatternObjectID m172 : 40|16@1+ (1,0) [0|65535] "" Vector__XXX
 SG_ WorkingSetObjectID m173 : 8|16@1+ (1,0) [0|65535] "" Vector__XXX
 SG_ NewActiveMaskObjectID m173 : 24|16@1+ (1,0) [0|65535] "" Vector__XXX
 SG_ MaskType m174 : 8|8@1+ (1,0) [0|255] "" Vector__XXX
 SG_ DataOrAlarmMaskObjectID m174 : 16|16@1+ (1,0) [0|65535] "" Vector__XXX
 SG_ NewSoftKeyMaskObjectID m174 : 32|16@1+ (1,0) [0|65535] "" Vector__XXX
 SG_ ObjectToChangeAttributeID m175 : 8|16@1+ (1,0) [0|65535] "" Vector__XXX
 SG_ AttributeID m175 : 24|8@1+ (1,0) [0|16777200] "" Vector__XXX
 SG_ NewAttributeValue m175 : 32|32@1+ (1,0) [0|0] "" Vector__XXX
 SG_ AlarmMaskObjectID m176 : 8|16@1+ (1,0) [0|65535] "" Vector__XXX
 SG_ NewPriority m176 : 24|8@1+ (1,0) [0|255] "" Vector__XXX
 SG_ ListInputObjectID m177 : 8|16@1+ (1,0) [0|65535] "" Vector__XXX
 SG_ ListIndex m177 : 24|8@1+ (1,0) [0|255] "" Vector__XXX
 SG_ NewObjectID m177 : 32|16@1+ (1,0) [0|65535] "" Vector__XXX
 SG_ ObjectToChangeStringValueID m179 : 8|16@1+ (1,0) [0|65535] "" Vector__XXX
 SG_ NewStringValue m179 : 24|16@1+ (1,0) [0|65535] "" Vector__XXX
 SG_ ParentObjectID m180 : 8|16@1+ (1,0) [0|65535] "" Vector__XXX
 SG_ ObjectToMoveID m180 : 24|16@1+ (1,0) [0|65535] "" Vector__XXX
 SG_ XPosChangeTopLeftLong m180 : 40|16@1- (1,0) [-32768|32767] "" Vector__XXX
 SG_ YPosChangeTopLeftLong m180 : 56|16@1- (1,0) [-32768|32767] "" Vector__XXX
 SG_ ObjectToAssociateLabelWithID m181 : 8|16@1+ (1,0) [0|65535] "" Vector__XXX
 SG_ StringVariableObjectID m181 : 24|16@1+ (1,0) [0|65535] "" Vector__XXX
 SG_ GraphicRepresentationObjectID m181 : 48|16@1+ (1,0) [0|255] "" Vector__XXX
 SG_ FontType m181 : 40|8@1+ (1,0) [0|255] "" Vector__XXX
 SG_ PolygonObjectToChangeID m182 : 8|16@1+ (1,0) [0|65535] "" Vector__XXX
 SG_ IndexOfThePointToReplace m182 : 24|8@1+ (1,0) [0|255] "" Vector__XXX
 SG_ NewValueX m182 : 32|16@1+ (1,0) [0|65535] "" Vector__XXX
 SG_ NewValueY m182 : 48|16@1+ (1,0) [0|65535] "" Vector__XXX
 SG_ PolygonObjectToScaleID m183 : 8|16@1+ (1,0) [0|65535] "" Vector__XXX
 SG_ NewWidthAttribute m183 : 24|16@1+ (1,0) [0|65535] "" Vector__XXX
 SG_ NewHeigthAttribute m183 : 40|16@1+ (1,0) [0|0] "" Vector__XXX
 SG_ GraphicsContextObjectID m184 : 8|16@1+ (1,0) [0|65535] "" Vector__XXX
 SG_ SubCommandID m184 : 24|8@1+ (1,0) [0|0] "" Vector__XXX
 SG_ ObjectToGetAttributeID m185 : 8|16@1+ (1,0) [0|65535] "" Vector__XXX
 SG_ AttributeID m185 : 24|8@1+ (1,0) [0|0] "" Vector__XXX
 SG_ ColourMapObjectID m186 : 8|16@1+ (1,0) [0|65535] "" Vector__XXX
 SG_ LockUnlockCommand m189 : 8|8@1+ (1,0) [0|1] "" Vector__XXX
 SG_ ObjectIDOfDataMaskToLock m189 : 16|16@1+ (1,0) [0|65535] "" Vector__XXX
 SG_ LockTimeout m189 : 32|16@1+ (1,0) [0|65535] "" Vector__XXX
 SG_ MacroObjecID m190 : 8|8@1+ (1,0) [0|255] "" Vector__XXX
 SG_ MemoryRequired m192 : 16|24@1+ (1,0) [0|16777200] "" Vector__XXX
 SG_ CodePlane m193 : 8|8@1+ (1,0) [0|16] "" Vector__XXX
 SG_ FirstWideChar m193 : 16|16@1+ (1,0) [0|65535] "" Vector__XXX
 SG_ LastWideChar m193 : 32|16@1+ (1,0) [0|65535] "" Vector__XXX
 SG_ VersionLabelToStore m208 : 8|56@1+ (1,0) [0|3338120000] "" Vector__XXX
 SG_ VersionLabelToLoad m209 : 8|56@1+ (1,0) [0|3338120000] "" Vector__XXX
 SG_ VersionLabelToDelete m210 : 8|56@1+ (1,0) [0|3338120000] "" Vector__XXX
 SG_ WSMaintenanceInitiating m255 : 8|1@1+ (1,0) [0|1] "" Vector__XXX
 SG_ WSMaintenanceBitmask m255 : 15|1@1+ (1,0) [0|1] "" Vector__XXX

BO_ 2565537534 RQST: 3 Vector__XXX
 SG_ RqstedPGN : 0|24@1+ (1,0) [0|16777200] ""  Sprayer,VT,TECU,TC

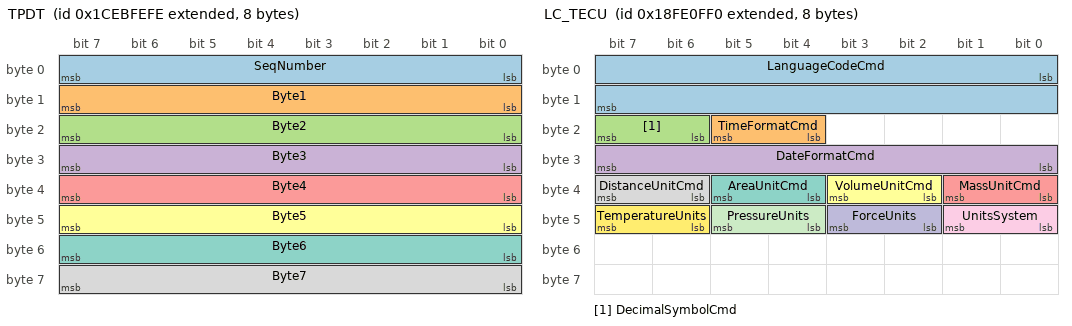
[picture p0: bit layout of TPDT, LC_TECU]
BO_ 2632711934 TPDT: 8 Vector__XXX
 SG_ SeqNumber : 0|8@1+ (1,0) [0|255] "" Vector__XXX
 SG_ Byte1 : 8|8@1+ (1,0) [0|255] "" Vector__XXX
 SG_ Byte2 : 16|8@1+ (1,0) [0|255] "" Vector__XXX
 SG_ Byte3 : 24|8@1+ (1,0) [0|255] "" Vector__XXX
 SG_ Byte4 : 32|8@1+ (1,0) [0|255] "" Vector__XXX
 SG_ Byte5 : 40|8@1+ (1,0) [0|255] "" Vector__XXX
 SG_ Byte6 : 48|8@1+ (1,0) [0|255] "" Vector__XXX
 SG_ Byte7 : 56|8@1+ (1,0) [0|255] "" Vector__XXX

BO_ 2632777470 TPCM: 8 Vector__XXX
 SG_ ConnectionAbortReason m255 : 8|8@1+ (1,0) [0|255] "" Vector__XXX
 SG_ ControlByte M : 0|8@1+ (1,0) [0|255] "" Vector__XXX
 SG_ AckMsgSize m19 : 8|16@1+ (1,0) [9|1785] "" Vector__XXX
 SG_ BamMsgSize m32 : 8|16@1+ (1,0) [9|1785] "" Vector__XXX
 SG_ RtsMsgSize m16 : 8|16@1+ (1,0) [9|1785] "" Vector__XXX
 SG_ SendPackets m17 : 8|8@1+ (1,0) [0|255] "" Vector__XXX
 SG_ ERtsMsgSize m20 : 8|32@1+ (1,0) [1786|117440505] "" Vector__XXX
 SG_ ECtsNoPackets m21 : 8|8@1+ (1,0) [1|255] "" Vector__XXX
 SG_ EDpoNoPackets m22 : 8|8@1+ (1,0) [1|255] "" Vector__XXX
 SG_ EAckMsgSize m23 : 8|32@1+ (1,0) [1786|117440505] "" Vector__XXX
 SG_ NextPacket m17 : 16|8@1+ (1,0) [1|255] "" Vector__XXX
 SG_ ECtsNextPacket m21 : 16|24@1+ (1,0) [1|16777215] "" Vector__XXX
 SG_ EDpoOffset m22 : 16|24@1+ (1,0) [0|16777215] "" Vector__XXX
 SG_ AckNoPackets m19 : 24|8@1+ (1,0) [1|255] "" Vector__XXX
 SG_ BamNoPackets m32 : 24|8@1+ (1,0) [1|255] "" Vector__XXX
 SG_ RtsNoPackets m16 : 24|8@1+ (1,0) [1|255] "" Vector__XXX
 SG_ PGNumber : 40|24@1+ (1,0) [0|16777200] "" Vector__XXX
 SG_ RtsMaxPacketsPerCts m16 : 32|8@1+ (1,0) [0|255] "" Vector__XXX

BO_ 2365458686 RTF: 8 Vector__XXX
 SG_ DirectionControl : 32|1@1+ (1,0) [0|1] "" Vector__XXX
 SG_ SelectedMachineSpeedControl : 33|1@1+ (1,0) [0|1] "" Vector__XXX
 SG_ SelectedMachineSpeed : 34|1@1+ (1,0) [0|1] "" Vector__XXX
 SG_ OperatorExternalLightControls : 35|1@1+ (1,0) [0|1] "" Vector__XXX
 SG_ LimitStatusReporting : 27|1@1+ (1,0) [0|0] "" Vector__XXX
 SG_ SpeedInfo_EngineSpeed : 0|1@1+ (1,0) [0|1] ""  TECU
 SG_ SpeedInfo_GroundBasedSpeed : 1|1@1+ (1,0) [0|1] "" Vector__XXX
 SG_ SpeedInfo_WheelBasedSpeed : 2|1@1+ (1,0) [0|1] "" Vector__XXX
 SG_ PowerMgt_MaintainPower : 3|1@1+ (1,0) [0|1] "" Vector__XXX
 SG_ PowerMgt_MaxTimeTractorPower : 4|1@1+ (1,0) [0|1] "" Vector__XXX
 SG_ PowerMgt_KeySwitch : 5|1@1+ (1,0) [0|1] "" Vector__XXX
 SG_ TractorClass : 6|2@1+ (1,0) [0|3] "" Vector__XXX
 SG_ LanguageCmdStorageInTractorECU : 10|1@1+ (1,0) [0|1] "" Vector__XXX
 SG_ Lighting_MinimalSet : 11|1@1+ (1,0) [0|1] "" Vector__XXX
 SG_ PTOInfo_RearShaftEngagement : 12|1@1+ (1,0) [0|0] "" Vector__XXX
 SG_ PTOInfo_RearShaftSpeed : 13|1@1+ (1,0) [0|1] "" Vector__XXX
 SG_ HitchInfo_RearInWork : 14|1@1+ (1,0) [0|1] "" Vector__XXX
 SG_ HitchInfo_RearPosition : 15|1@1+ (1,0) [0|1] "" Vector__XXX
 SG_ EstimatedOrMeasuredAuxValveState : 16|1@1+ (1,0) [0|1] "" Vector__XXX
 SG_ Light_FullImplLightingMessageSet : 17|1@1+ (1,0) [0|1] "" Vector__XXX
 SG_ AddHitchParameter_RearDraft : 18|1@1+ (1,0) [0|1] "" Vector__XXX
 SG_ SpeedAndDist_WheelBasedDirection : 19|1@1+ (1,0) [0|1] "" Vector__XXX
 SG_ SpeedAndDist_WheelBasedDistance : 20|1@1+ (1,0) [0|1] "" Vector__XXX
 SG_ SpeedAndDist_GndBasedDirection : 21|1@1+ (1,0) [0|1] "" Vector__XXX
 SG_ SpeedAndDist_GndBasedDistance : 22|1@1+ (1,0) [0|1] "" Vector__XXX
 SG_ TimeDate : 23|1@1+ (1,0) [0|1] "" Vector__XXX
 SG_ AuxiliaryValveCmd : 28|1@1+ (1,0) [0|1] "" Vector__XXX
 SG_ PTOCmd_RearPTOEngagementCmd : 29|1@1+ (1,0) [0|1] "" Vector__XXX
 SG_ PTOCmd_RearPTOSpeedCmd : 30|1@1+ (1,0) [0|1] "" Vector__XXX
 SG_ HitchCmd_RearHitchPosition : 31|1@1+ (1,0) [0|1] "" Vector__XXX
 SG_ NavigPseudorangeNoiseStatistic : 37|1@1+ (1,0) [0|1] "" Vector__XXX
 SG_ NavigSystemPositionData : 38|1@1+ (1,0) [0|1] "" Vector__XXX
 SG_ NavigSystemHighOutputPosition : 39|1@1+ (1,0) [0|1] "" Vector__XXX
 SG_ PTOCmd_FrontPTOEngagementCmd : 40|1@1+ (1,0) [0|1] "" Vector__XXX
 SG_ PTOCmd_FrontPTOSpeedCmd : 41|1@1+ (1,0) [0|1] "" Vector__XXX
 SG_ HitchCmd_FrontHitchPosition : 42|1@1+ (1,0) [0|1] "" Vector__XXX
 SG_ AddHitchParameter__FrontDraft : 43|1@1+ (1,0) [0|1] "" Vector__XXX
 SG_ PTOInfo_FrontShaftEngagement : 44|1@1+ (1,0) [0|1] "" Vector__XXX
 SG_ PTOInfo_FrontShaftSpeed : 45|1@1+ (1,0) [0|1] "" Vector__XXX
 SG_ HitchInfo_FrontInWork : 46|1@1+ (1,0) [0|1] "" Vector__XXX
 SG_ HitchInfo_FrontPosition : 47|1@1+ (1,0) [0|1] "" Vector__XXX

BO_ 2365458928 TFR_TECU: 8 TECU
 SG_ LimitStatusReporting : 27|1@1+ (1,0) [0|0] "" Vector__XXX
 SG_ SpeedInfo_EngineSpeed : 0|1@1+ (1,0) [0|1] "" Vector__XXX
 SG_ SpeedInfo_GroundBasedSpeed : 1|1@1+ (1,0) [0|1] "" Vector__XXX
 SG_ SpeedInfo_WheelBasedSpeed : 2|1@1+ (1,0) [0|1] "" Vector__XXX
 SG_ PowerMgt_MaintainPower : 3|1@1+ (1,0) [0|1] "" Vector__XXX
 SG_ PowerMgt_MaxTimeTractorPower : 4|1@1+ (1,0) [0|1] "" Vector__XXX
 SG_ PowerMgt_KeySwitch : 5|1@1+ (1,0) [0|1] "" Vector__XXX
 SG_ TractorClass : 6|2@1+ (1,0) [0|3] "" Vector__XXX
 SG_ LanguageCmdStorageInTractorECU : 10|1@1+ (1,0) [0|1] "" Vector__XXX
 SG_ Lighting_MinimalSet : 11|1@1+ (1,0) [0|1] "" Vector__XXX
 SG_ PTOInfo_RearShaftEngagement : 12|1@1+ (1,0) [0|0] "" Vector__XXX
 SG_ PTOInfo_RearShaftSpeed : 13|1@1+ (1,0) [0|1] "" Vector__XXX
 SG_ HitchInfo_RearInWork : 14|1@1+ (1,0) [0|1] "" Vector__XXX
 SG_ HitchInfo_RearPosition : 15|1@1+ (1,0) [0|1] "" Vector__XXX
 SG_ EstimatedOrMeasuredAuxValveState : 16|1@1+ (1,0) [0|1] "" Vector__XXX
 SG_ Light_FullImplLightingMessageSet : 17|1@1+ (1,0) [0|1] "" Vector__XXX
 SG_ AddHitchParameter_RearDraft : 18|1@1+ (1,0) [0|1] "" Vector__XXX
 SG_ SpeedAndDist_WheelBasedDirection : 19|1@1+ (1,0) [0|1] "" Vector__XXX
 SG_ SpeedAndDist_WheelBasedDistance : 20|1@1+ (1,0) [0|1] "" Vector__XXX
 SG_ SpeedAndDist_GndBasedDirection : 21|1@1+ (1,0) [0|1] "" Vector__XXX
 SG_ SpeedAndDist_GndBasedDistance : 22|1@1+ (1,0) [0|1] "" Vector__XXX
 SG_ TimeDate : 23|1@1+ (1,0) [0|1] "" Vector__XXX
 SG_ AuxiliaryValveCmd : 28|1@1+ (1,0) [0|1] "" Vector__XXX
 SG_ PTOCmd_RearPTOEngagementCmd : 29|1@1+ (1,0) [0|1] "" Vector__XXX
 SG_ PTOCmd_RearPTOSpeedCmd : 30|1@1+ (1,0) [0|1] "" Vector__XXX
 SG_ HitchCmd_RearHitchPosition : 31|1@1+ (1,0) [0|1] "" Vector__XXX
 SG_ NavigPseudorangeNoiseStatistic : 37|1@1+ (1,0) [0|1] "" Vector__XXX
 SG_ NavigSystemPositionData : 38|1@1+ (1,0) [0|1] "" Vector__XXX
 SG_ NavigSystemHighOutputPosition : 39|1@1+ (1,0) [0|1] "" Vector__XXX
 SG_ PTOCmd_FrontPTOEngagementCmd : 40|1@1+ (1,0) [0|1] "" Vector__XXX
 SG_ PTOCmd_FrontPTOSpeedCmd : 41|1@1+ (1,0) [0|1] "" Vector__XXX
 SG_ HitchCmd_FrontHitchPosition : 42|1@1+ (1,0) [0|1] "" Vector__XXX
 SG_ AddHitchParameter__FrontDraft : 43|1@1+ (1,0) [0|1] "" Vector__XXX
 SG_ PTOInfo_FrontShaftEngagement : 44|1@1+ (1,0) [0|1] "" Vector__XXX
 SG_ PTOInfo_FrontShaftSpeed : 45|1@1+ (1,0) [0|1] "" Vector__XXX
 SG_ HitchInfo_FrontInWork : 46|1@1+ (1,0) [0|1] "" Vector__XXX
 SG_ HitchInfo_FrontPosition : 47|1@1+ (1,0) [0|1] "" Vector__XXX

BO_ 2633895166 WSMEM: 8 Vector__XXX
 SG_ NameOfWorkingSetMember : 0|64@1+ (1,0) [0|0] ""  VT

BO_ 2633895422 WSMSTR: 8 Vector__XXX
 SG_ NumberOfMembersInWorkingSet : 0|8@1+ (1,0) [1|250] ""  VT,TC

BO_ 2566787056 LC_TECU: 8 TECU
 SG_ LanguageCodeCmd : 0|16@1+ (1,0) [0|16383] "" Vector__XXX
 SG_ TimeFormatCmd : 20|2@1+ (1,0) [0|3] "" Vector__XXX
 SG_ DecimalSymbolCmd : 22|2@1+ (1,0) [0|3] "" Vector__XXX
 SG_ DateFormatCmd : 24|8@1+ (1,0) [0|255] "" Vector__XXX
 SG_ MassUnitCmd : 32|2@1+ (1,0) [0|3] "" Vector__XXX
 SG_ VolumeUnitCmd : 34|2@1+ (1,0) [0|3] "" Vector__XXX
 SG_ AreaUnitCmd : 36|2@1+ (1,0) [0|3] "" Vector__XXX
 SG_ DistanceUnitCmd : 38|2@1+ (1,0) [0|3] "" Vector__XXX
 SG_ UnitsSystem : 40|2@1+ (1,0) [0|3] "" Vector__XXX
 SG_ ForceUnits : 42|2@1+ (1,0) [0|3] "" Vector__XXX
 SG_ PressureUnits : 44|2@1+ (1,0) [0|3] "" Vector__XXX
 SG_ TemperatureUnits : 46|2@1+ (1,0) [0|3] "" Vector__XXX

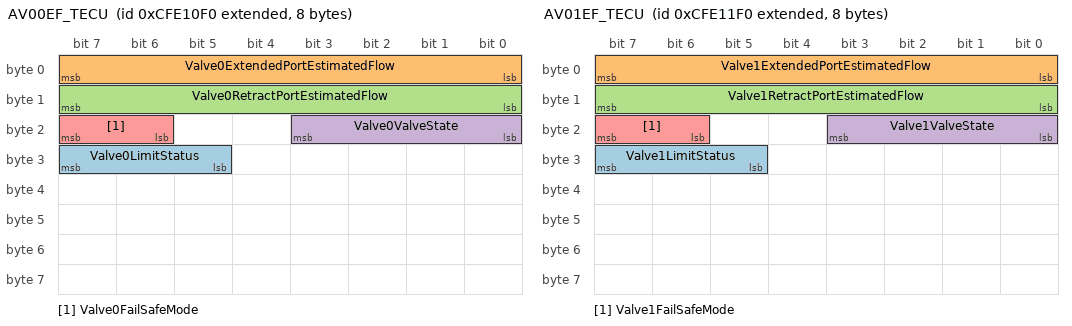
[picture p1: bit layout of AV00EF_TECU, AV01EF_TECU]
BO_ 2365460720 AV00EF_TECU: 8 TECU
 SG_ Valve0LimitStatus : 29|3@1+ (1,0) [0|7] "" Vector__XXX
 SG_ Valve0ExtendedPortEstimatedFlow : 0|8@1+ (1,-125) [-125|125] "%" Vector__XXX
 SG_ Valve0RetractPortEstimatedFlow : 8|8@1+ (1,-125) [-125|125] "%" Vector__XXX
 SG_ Valve0ValveState : 16|4@1+ (1,0) [0|15] "" Vector__XXX
 SG_ Valve0FailSafeMode : 22|2@1+ (1,0) [0|3] "" Vector__XXX

BO_ 2365460976 AV01EF_TECU: 8 TECU
 SG_ Valve1LimitStatus : 29|3@1+ (1,0) [0|7] "" Vector__XXX
 SG_ Valve1ExtendedPortEstimatedFlow : 0|8@1+ (1,-125) [-125|125] "%" Vector__XXX
 SG_ Valve1RetractPortEstimatedFlow : 8|8@1+ (1,-125) [-125|125] "%" Vector__XXX
 SG_ Valve1ValveState : 16|4@1+ (1,0) [0|15] "" Vector__XXX
 SG_ Valve1FailSafeMode : 22|2@1+ (1,0) [0|3] "" Vector__XXX

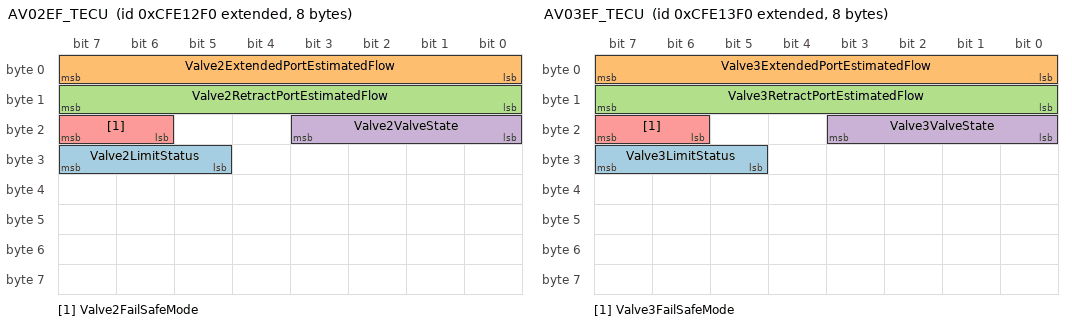
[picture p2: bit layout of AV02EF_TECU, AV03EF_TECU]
BO_ 2365461232 AV02EF_TECU: 8 TECU
 SG_ Valve2LimitStatus : 29|3@1+ (1,0) [0|7] "" Vector__XXX
 SG_ Valve2ExtendedPortEstimatedFlow : 0|8@1+ (1,-125) [-125|125] "%" Vector__XXX
 SG_ Valve2RetractPortEstimatedFlow : 8|8@1+ (1,-125) [-125|125] "%" Vector__XXX
 SG_ Valve2ValveState : 16|4@1+ (1,0) [0|15] "" Vector__XXX
 SG_ Valve2FailSafeMode : 22|2@1+ (1,0) [0|3] "" Vector__XXX

BO_ 2365461488 AV03EF_TECU: 8 TECU
 SG_ Valve3LimitStatus : 29|3@1+ (1,0) [0|7] "" Vector__XXX
 SG_ Valve3ExtendedPortEstimatedFlow : 0|8@1+ (1,-125) [-125|125] "%" Vector__XXX
 SG_ Valve3RetractPortEstimatedFlow : 8|8@1+ (1,-125) [-125|125] "%" Vector__XXX
 SG_ Valve3ValveState : 16|4@1+ (1,0) [0|15] "" Vector__XXX
 SG_ Valve3FailSafeMode : 22|2@1+ (1,0) [0|3] "" Vector__XXX

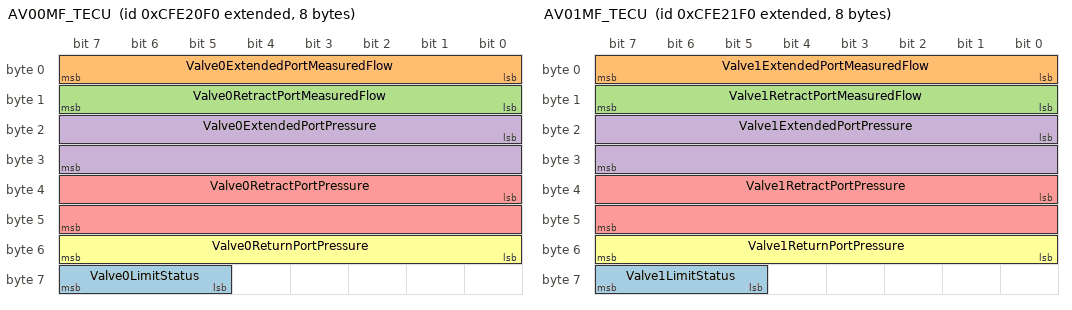
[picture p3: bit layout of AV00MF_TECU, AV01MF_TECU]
BO_ 2365464816 AV00MF_TECU: 8 TECU
 SG_ Valve0LimitStatus : 61|3@1+ (1,0) [0|7] "" Vector__XXX
 SG_ Valve0ExtendedPortMeasuredFlow : 0|8@1+ (1,-125) [-125|125] "%" Vector__XXX
 SG_ Valve0RetractPortMeasuredFlow : 8|8@1+ (1,-125) [-125|125] "%" Vector__XXX
 SG_ Valve0ExtendedPortPressure : 16|16@1+ (5,0) [0|321275] "kPa" Vector__XXX
 SG_ Valve0RetractPortPressure : 32|16@1+ (5,0) [0|321275] "kPa" Vector__XXX
 SG_ Valve0ReturnPortPressure : 48|8@1+ (16,0) [0|4000] "kPa" Vector__XXX

BO_ 2365465072 AV01MF_TECU: 8 TECU
 SG_ Valve1LimitStatus : 61|3@1+ (1,0) [0|7] "" Vector__XXX
 SG_ Valve1ExtendedPortMeasuredFlow : 0|8@1+ (1,-125) [-125|125] "%" Vector__XXX
 SG_ Valve1RetractPortMeasuredFlow : 8|8@1+ (1,-125) [-125|125] "%" Vector__XXX
 SG_ Valve1ExtendedPortPressure : 16|16@1+ (5,0) [0|321275] "kPa" Vector__XXX
 SG_ Valve1RetractPortPressure : 32|16@1+ (5,0) [0|321275] "kPa" Vector__XXX
 SG_ Valve1ReturnPortPressure : 48|8@1+ (16,0) [0|4000] "kPa" Vector__XXX

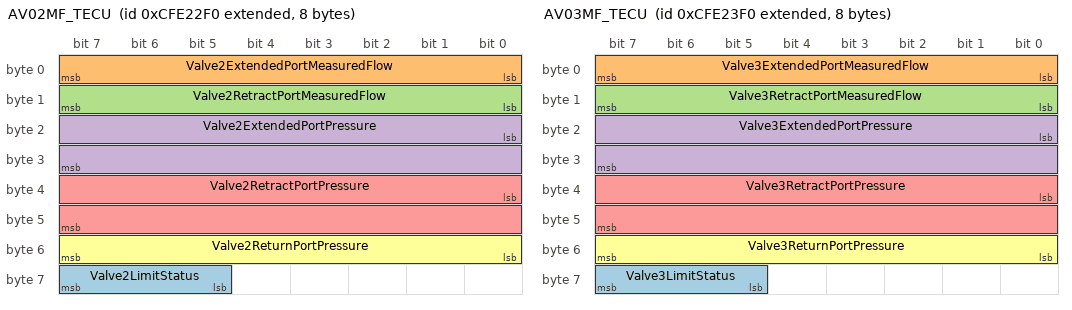
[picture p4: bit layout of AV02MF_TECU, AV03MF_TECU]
BO_ 2365465328 AV02MF_TECU: 8 TECU
 SG_ Valve2LimitStatus : 61|3@1+ (1,0) [0|7] "" Vector__XXX
 SG_ Valve2ExtendedPortMeasuredFlow : 0|8@1+ (1,-125) [-125|125] "%" Vector__XXX
 SG_ Valve2RetractPortMeasuredFlow : 8|8@1+ (1,-125) [-125|125] "%" Vector__XXX
 SG_ Valve2ExtendedPortPressure : 16|16@1+ (5,0) [0|321275] "kPa" Vector__XXX
 SG_ Valve2RetractPortPressure : 32|16@1+ (5,0) [0|321275] "kPa" Vector__XXX
 SG_ Valve2ReturnPortPressure : 48|8@1+ (16,0) [0|4000] "kPa" Vector__XXX

BO_ 2365465584 AV03MF_TECU: 8 TECU
 SG_ Valve3LimitStatus : 61|3@1+ (1,0) [0|7] "" Vector__XXX
 SG_ Valve3ExtendedPortMeasuredFlow : 0|8@1+ (1,-125) [-125|125] "%" Vector__XXX
 SG_ Valve3RetractPortMeasuredFlow : 8|8@1+ (1,-125) [-125|125] "%" Vector__XXX
 SG_ Valve3ExtendedPortPressure : 16|16@1+ (5,0) [0|321275] "kPa" Vector__XXX
 SG_ Valve3RetractPortPressure : 32|16@1+ (5,0) [0|321275] "kPa" Vector__XXX
 SG_ Valve3ReturnPortPressure : 48|8@1+ (16,0) [0|4000] "kPa" Vector__XXX

BO_ 2365473264 LIC_TECU: 8 TECU
 SG_ DaytimeRunningLightCmd : 0|2@1+ (1,0) [0|3] "" Vector__XXX
 SG_ AlternateHeadLightCmd : 2|2@1+ (1,0) [0|3] "" Vector__XXX
 SG_ LowBeamHeadLightCmd : 4|2@1+ (1,0) [0|3] "" Vector__XXX
 SG_ HighBeamHeadLightCmd : 6|2@1+ (1,0) [0|3] "" Vector__XXX
 SG_ FrontFogLightCmd : 8|2@1+ (1,0) [0|3] "" Vector__XXX
 SG_ RotatingBeaconLightCmd : 10|2@1+ (1,0) [0|3] "" Vector__XXX
 SG_ RightTurnSignalLightCmd : 12|2@1+ (1,0) [0|3] "" Vector__XXX
 SG_ LeftTurnSignalLightCmd : 14|2@1+ (1,0) [0|3] "" Vector__XXX
 SG_ BackUpLightAndAlarmHornCmd : 16|2@1+ (1,0) [0|3] "" Vector__XXX
 SG_ CentreStopLightCmd : 18|2@1+ (1,0) [0|3] "" Vector__XXX
 SG_ RightStopLightCmd : 20|2@1+ (1,0) [0|3] "" Vector__XXX
 SG_ LeftStopLightCmd : 22|2@1+ (1,0) [0|3] "" Vector__XXX
 SG_ ImplementClearanceLightCmd : 24|2@1+ (1,0) [0|3] "" Vector__XXX
 SG_ TractorClearanceLightCmd : 26|2@1+ (1,0) [0|3] "" Vector__XXX
 SG_ ImplementMarkerLightCmd : 28|2@1+ (1,0) [0|3] "" Vector__XXX
 SG_ TractorMarkerLightCmd : 30|2@1+ (1,0) [0|3] "" Vector__XXX
 SG_ RearFogLightCmd : 32|2@1+ (1,0) [0|3] "" Vector__XXX
 SG_ TractorUndersideWorkLightCmd : 34|2@1+ (1,0) [0|3] "" Vector__XXX
 SG_ TractorRearLowWorkLightCmd : 36|2@1+ (1,0) [0|3] "" Vector__XXX
 SG_ TractorRearHighWorkLightCmd : 38|2@1+ (1,0) [0|3] "" Vector__XXX
 SG_ TractorSideLowWorkLightCmd : 40|2@1+ (1,0) [0|3] "" Vector__XXX
 SG_ TractorSideHighWorkLightCmd : 42|2@1+ (1,0) [0|3] "" Vector__XXX
 SG_ TractorFrontLowWorkLightCmd : 44|2@1+ (1,0) [0|3] "" Vector__XXX
 SG_ TractorFrontHighWorkLightCmd : 46|2@1+ (1,0) [0|3] "" Vector__XXX
 SG_ ImplementOEMOption2LightCmd : 48|2@1+ (1,0) [0|3] "" Vector__XXX
 SG_ ImplementOEMOption1LightCmd : 50|2@1+ (1,0) [0|3] "" Vector__XXX
 SG_ ImplementRightForwardLightCmd : 52|2@1+ (1,0) [0|3] "" Vector__XXX
 SG_ ImplementLeftForwardLightCmd : 54|2@1+ (1,0) [0|3] "" Vector__XXX
 SG_ LightingDataRequestCmd : 56|2@1+ (1,0) [0|3] "" Vector__XXX
 SG_ ImplementRightFacingWorkLightCmd : 58|2@1+ (1,0) [0|3] "" Vector__XXX
 SG_ ImplementLeftFacingWorkLightCmd : 60|2@1+ (1,0) [0|3] "" Vector__XXX
 SG_ ImplementRearWorkLightCmd : 62|2@1+ (1,0) [0|3] "" Vector__XXX

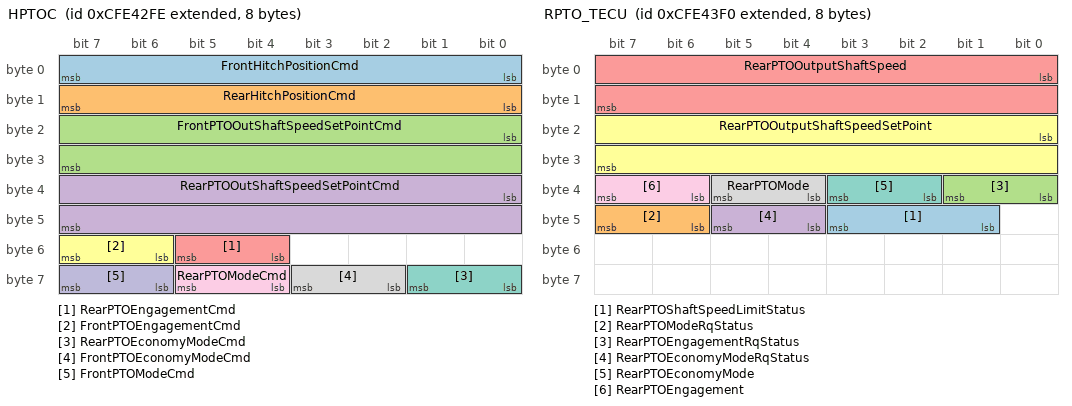
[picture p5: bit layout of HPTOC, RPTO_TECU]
BO_ 2365473534 HPTOC: 8 Vector__XXX
 SG_ FrontHitchPositionCmd : 0|8@1+ (0.4,0) [0|100] "%"  TECU
 SG_ RearHitchPositionCmd : 8|8@1+ (0.4,0) [0|100] "%" Vector__XXX
 SG_ FrontPTOOutShaftSpeedSetPointCmd : 16|16@1+ (0.125,0) [0|8031.875] "1/min" Vector__XXX
 SG_ RearPTOOutShaftSpeedSetPointCmd : 32|16@1+ (0.125,0) [0|801.875] "1/min" Vector__XXX
 SG_ RearPTOEngagementCmd : 52|2@1+ (1,0) [0|3] "" Vector__XXX
 SG_ FrontPTOEngagementCmd : 54|2@1+ (1,0) [0|3] "" Vector__XXX
 SG_ RearPTOEconomyModeCmd : 56|2@1+ (1,0) [0|3] "" Vector__XXX
 SG_ FrontPTOEconomyModeCmd : 58|2@1+ (1,0) [0|3] "" Vector__XXX
 SG_ RearPTOModeCmd : 60|2@1+ (1,0) [0|3] "" Vector__XXX
 SG_ FrontPTOModeCmd : 62|2@1+ (1,0) [0|3] "" Vector__XXX

BO_ 2365473776 RPTO_TECU: 8 TECU
 SG_ RearPTOShaftSpeedLimitStatus : 41|3@1+ (1,0) [0|7] "" Vector__XXX
 SG_ RearPTOModeRqStatus : 46|2@1+ (1,0) [0|3] "" Vector__XXX
 SG_ RearPTOEngagementRqStatus : 32|2@1+ (1,0) [0|3] "" Vector__XXX
 SG_ RearPTOEconomyModeRqStatus : 44|2@1+ (1,0) [0|3] "" Vector__XXX
 SG_ RearPTOOutputShaftSpeed : 0|16@1+ (0.125,0) [0|8031.88] "1/min"  Sprayer
 SG_ RearPTOOutputShaftSpeedSetPoint : 16|16@1+ (0.125,0) [0|8031.88] "1/min" Vector__XXX
 SG_ RearPTOEconomyMode : 34|2@1+ (1,0) [0|3] "" Vector__XXX
 SG_ RearPTOMode : 36|2@1+ (1,0) [0|3] "" Vector__XXX
 SG_ RearPTOEngagement : 38|2@1+ (1,0) [0|3] "" Vector__XXX

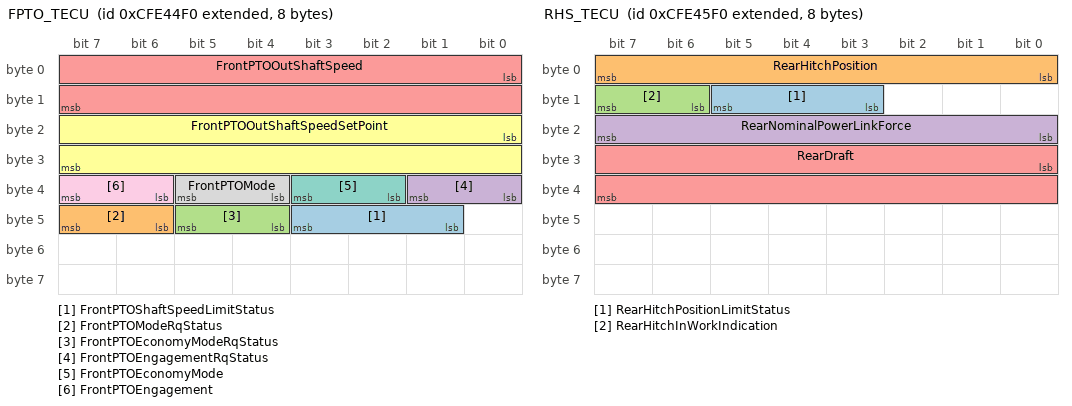
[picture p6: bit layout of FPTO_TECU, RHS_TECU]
BO_ 2365474032 FPTO_TECU: 8 TECU
 SG_ FrontPTOShaftSpeedLimitStatus : 41|3@1+ (1,0) [0|7] "" Vector__XXX
 SG_ FrontPTOModeRqStatus : 46|2@1+ (1,0) [0|3] "" Vector__XXX
 SG_ FrontPTOEconomyModeRqStatus : 44|2@1+ (1,0) [0|3] "" Vector__XXX
 SG_ FrontPTOEngagementRqStatus : 32|2@1+ (1,0) [0|3] "" Vector__XXX
 SG_ FrontPTOOutShaftSpeed : 0|16@1+ (0.125,0) [0|8031.88] "1/min" Vector__XXX
 SG_ FrontPTOOutShaftSpeedSetPoint : 16|16@1+ (0.125,0) [0|8031.88] "1/min" Vector__XXX
 SG_ FrontPTOEconomyMode : 34|2@1+ (1,0) [0|3] "" Vector__XXX
 SG_ FrontPTOMode : 36|2@1+ (1,0) [0|3] "" Vector__XXX
 SG_ FrontPTOEngagement : 38|2@1+ (1,0) [0|3] "" Vector__XXX

BO_ 2365474288 RHS_TECU: 8 TECU
 SG_ RearHitchPositionLimitStatus : 11|3@1+ (1,0) [0|7] "" Vector__XXX
 SG_ RearHitchPosition : 0|8@1+ (0.4,0) [0|100] "%" Vector__XXX
 SG_ RearHitchInWorkIndication : 14|2@1+ (1,0) [0|3] "" Vector__XXX
 SG_ RearNominalPowerLinkForce : 16|8@1+ (0.8,-100) [-100|100] "%" Vector__XXX
 SG_ RearDraft : 24|16@1+ (10,-320000) [-320000|322550] "N" Vector__XXX

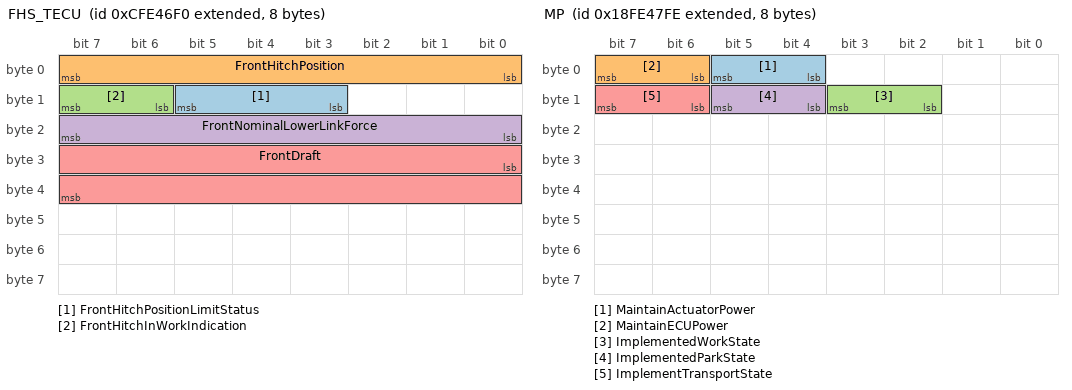
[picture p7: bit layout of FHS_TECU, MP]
BO_ 2365474544 FHS_TECU: 8 TECU
 SG_ FrontHitchPositionLimitStatus : 11|3@1+ (1,0) [0|7] "" Vector__XXX
 SG_ FrontHitchPosition : 0|8@1+ (0.4,0) [0|100] "%" Vector__XXX
 SG_ FrontHitchInWorkIndication : 14|2@1+ (1,0) [0|3] "" Vector__XXX
 SG_ FrontNominalLowerLinkForce : 16|8@1+ (0.8,-100) [-100|100] "%" Vector__XXX
 SG_ FrontDraft : 24|16@1+ (10,-320000) [-320000|322550] "N" Vector__XXX

BO_ 2566801406 MP: 8 Vector__XXX
 SG_ MaintainActuatorPower : 4|2@1+ (1,0) [0|3] ""  TECU
 SG_ MaintainECUPower : 6|2@1+ (1,0) [0|0] "" Vector__XXX
 SG_ ImplementedWorkState : 10|2@1+ (1,0) [0|3] "" Vector__XXX
 SG_ ImplementedParkState : 12|2@1+ (1,0) [0|3] "" Vector__XXX
 SG_ ImplementTransportState : 14|2@1+ (1,0) [0|3] "" Vector__XXX

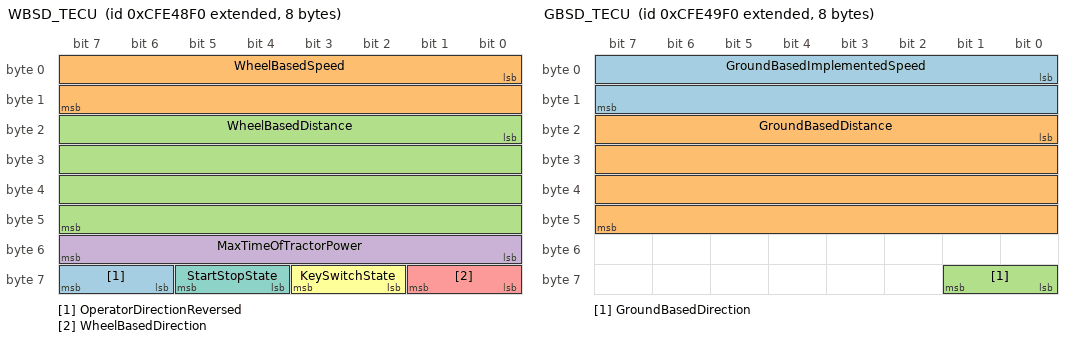
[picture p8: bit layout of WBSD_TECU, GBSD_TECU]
BO_ 2365475056 WBSD_TECU: 8 TECU
 SG_ OperatorDirectionReversed : 62|2@1+ (1,0) [0|3] "" Vector__XXX
 SG_ WheelBasedSpeed : 0|16@1+ (0.001,0) [0|64.255] "m/s" Vector__XXX
 SG_ WheelBasedDistance : 16|32@1+ (0.001,0) [0|4211081.215] "m" Vector__XXX
 SG_ MaxTimeOfTractorPower : 48|8@1+ (1,0) [0|250] "min" Vector__XXX
 SG_ WheelBasedDirection : 56|2@1+ (1,0) [0|3] "" Vector__XXX
 SG_ KeySwitchState : 58|2@1+ (1,0) [0|3] "" Vector__XXX
 SG_ StartStopState : 60|2@1+ (1,0) [0|4] "" Vector__XXX

BO_ 2365475312 GBSD_TECU: 8 TECU
 SG_ GroundBasedImplementedSpeed : 0|16@1+ (0.001,0) [0|64.255] "m/s"  Sprayer
 SG_ GroundBasedDistance : 16|32@1+ (0.001,0) [0|4211080] "m"  Sprayer
 SG_ GroundBasedDirection : 56|2@1+ (1,0) [0|3] ""  Sprayer

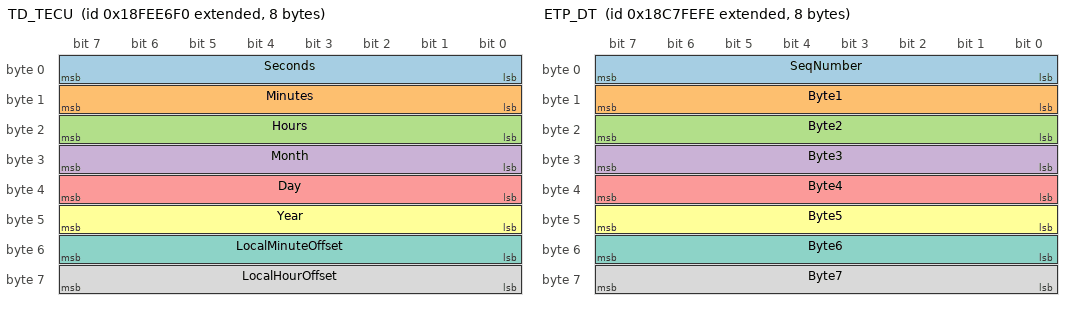
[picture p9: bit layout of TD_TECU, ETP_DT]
BO_ 2566842096 TD_TECU: 8 TECU
 SG_ Seconds : 0|8@1+ (0.25,0) [0|59.75] "s" Vector__XXX
 SG_ Minutes : 8|8@1+ (1,0) [0|59] "min" Vector__XXX
 SG_ Hours : 16|8@1+ (1,0) [0|23] "h" Vector__XXX
 SG_ Month : 24|8@1+ (1,0) [0|12] "month" Vector__XXX
 SG_ Day : 32|8@1+ (0.25,0) [0.25|31.75] "day" Vector__XXX
 SG_ Year : 40|8@1+ (1,1985) [1985|2235] "year" Vector__XXX
 SG_ LocalMinuteOffset : 48|8@1+ (1,0) [0|59] "min" Vector__XXX
 SG_ LocalHourOffset : 56|8@1+ (1,-125) [-149|-102] "" Vector__XXX

BO_ 2583168284 GNSSPositionData_GPS: 47 GPS
 SG_ SequenceID : 0|8@1+ (1,0) [0|255] "" Vector__XXX
 SG_ PositionDate : 8|16@1+ (1,0) [0|65532] "day" Vector__XXX
 SG_ PositionTime : 24|32@1+ (0.0001,0) [0|86401] "s" Vector__XXX
 SG_ Latitude : 56|64@1- (1E-016,0) [-90|90] "deg" Vector__XXX
 SG_ Longitude : 120|64@1- (1E-016,0) [-90|90] "deg" Vector__XXX
 SG_ Altitude : 184|64@1- (1E-006,0) [-9223372036854.78|9223372036854.78] "m" Vector__XXX
 SG_ TypeOfSystem : 248|4@1+ (1,0) [0|4] "" Vector__XXX
 SG_ GNSSMethod : 252|4@1+ (1,0) [0|15] "" Vector__XXX
 SG_ GNSSIntegrity : 256|2@1+ (1,0) [0|3] "" Vector__XXX
 SG_ NumberOfSVs : 264|8@1+ (1,0) [0|252] "" Vector__XXX
 SG_ HDOP : 272|16@1- (0.01,0) [-327.64|327.64] "" Vector__XXX
 SG_ PDOP : 288|16@1- (0.01,0) [-327.64|327.64] "" Vector__XXX
 SG_ GeoidalSeparation : 304|32@1- (0.01,0) [-21470000|21470000] "m" Vector__XXX
 SG_ NumberOfReferenceStations : 336|8@1+ (1,0) [0|252] "" Vector__XXX
 SG_ RefrenceStationType1 : 344|4@1+ (1,0) [0|15] "" Vector__XXX
 SG_ ReferenceStationID1 : 348|12@1+ (1,0) [0|4095] "" Vector__XXX
 SG_ AgeOfDGNSSCorrections1 : 360|16@1+ (0.01,0) [0|655.32] "sec" Vector__XXX

BO_ 2314731804 GNSSPositionRapidUpdate_GPS: 8 GPS
 SG_ Latitude : 0|32@1- (1E-007,0) [-90|90] "deg" Vector__XXX
 SG_ Longitude : 32|32@1- (1E-007,0) [-180|180] "deg" Vector__XXX

BO_ 2563309310 ETP_CM: 8 Vector__XXX
 SG_ ConnectionAbortReason m255 : 8|8@1+ (1,0) [0|255] "" Vector__XXX
 SG_ ControlByte M : 0|8@1+ (1,0) [0|255] "" Vector__XXX
 SG_ ERtsMsgSize m20 : 8|32@1+ (1,0) [1786|117440505] "" Vector__XXX
 SG_ ECtsNoPackets m21 : 8|8@1+ (1,0) [1|255] "" Vector__XXX
 SG_ EDpoNoPackets m22 : 8|8@1+ (1,0) [1|255] "" Vector__XXX
 SG_ EAckMsgSize m23 : 8|32@1+ (1,0) [1786|117440505] "" Vector__XXX
 SG_ ECtsNextPacket m21 : 16|24@1+ (1,0) [1|16777215] "" Vector__XXX
 SG_ EDpoOffset m22 : 16|24@1+ (1,0) [0|16777215] "" Vector__XXX
 SG_ PGNumber : 40|24@1+ (1,0) [0|16777200] "" Vector__XXX

BO_ 2563243774 ETP_DT: 8 Vector__XXX
 SG_ SeqNumber : 0|8@1+ (1,0) [0|255] "" Vector__XXX
 SG_ Byte1 : 8|8@1+ (1,0) [0|255] "" Vector__XXX
 SG_ Byte2 : 16|8@1+ (1,0) [0|255] "" Vector__XXX
 SG_ Byte3 : 24|8@1+ (1,0) [0|255] "" Vector__XXX
 SG_ Byte4 : 32|8@1+ (1,0) [0|255] "" Vector__XXX
 SG_ Byte5 : 40|8@1+ (1,0) [0|255] "" Vector__XXX
 SG_ Byte6 : 48|8@1+ (1,0) [0|255] "" Vector__XXX
 SG_ Byte7 : 56|8@1+ (1,0) [0|255] "" Vector__XXX

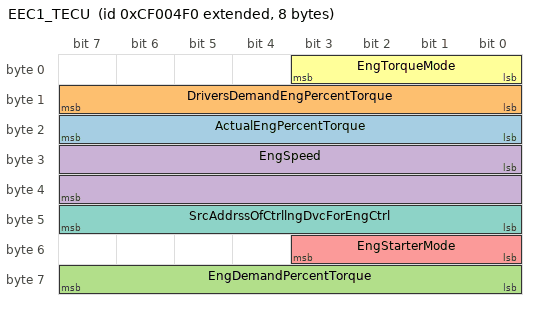
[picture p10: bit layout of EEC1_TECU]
BO_ 2364540144 EEC1_TECU: 8 TECU
 SG_ ActualEngPercentTorque : 16|8@1+ (1,-125) [-125|125] "%" Vector__XXX
 SG_ DriversDemandEngPercentTorque : 8|8@1+ (1,-125) [-125|125] "%" Vector__XXX
 SG_ EngDemandPercentTorque : 56|8@1+ (1,-125) [-125|125] "%" Vector__XXX
 SG_ EngSpeed : 24|16@1+ (0.125,0) [0|8031.875] "rpm" Vector__XXX
 SG_ EngStarterMode : 48|4@1+ (1,0) [0|15] "" Vector__XXX
 SG_ EngTorqueMode : 0|4@1+ (1,0) [0|15] "" Vector__XXX
 SG_ SrcAddrssOfCtrllngDvcForEngCtrl : 40|8@1+ (1,0) [0|255] "" Vector__XXX

CM_ BO_ 2632384038 "VT to ECU";
CM_ SG_ 2632384038 AuxiliaryFunctionType "Auxiliary function type of assigned auxiliary input";
CM_ SG_ 2632384038 VTChangeActiveMaskParentID "Parent object ID of error object ID";
CM_ SG_ 2632384038 VTChangeActiveMaskErrorID "Object ID containing error";
CM_ SG_ 2632384038 NumTransitionsDisabledToEnabled "Number of transitions of disabled to enabled";
CM_ SG_ 2632384038 ErrorCodePoolDeleted "VT change mask error code: Pool being deleted";
CM_ SG_ 2632384038 ErrorCodeAnyOtherError "VT change mask error code: Any other error";
CM_ SG_ 2632384038 AuxInputEnable "Auxiliary Input Enable";
CM_ SG_ 2632384038 AnalogValue "Analog value of 0xFFFF if input type is boolean";
CM_ BO_ 2565340800 "ECU to VT";
CM_ SG_ 2565340800 AuxModelIdentification "Model Identification Code of the Auxiliary Input Unit";
CM_ SG_ 2565340800 AuxInputEnable "Auxiliary Input Enable";
CM_ SG_ 2565340800 AuxErrorInvalidInputID "Invalid Auxiliary Input Object ID";
CM_ SG_ 2565340800 AuxErrorAnyOther "Any other error";
CM_ BO_ 2565537534 "Request PGN";
CM_ BO_ 2632711934 "Transport Protocol Data";
CM_ BO_ 2632777470 "Transport Protocol Connection Management";
CM_ SG_ 2632777470 RtsMaxPacketsPerCts "Maximum number of packets that can be sent in response to one CTS.";
CM_ BO_ 2365458686 "Required Tractor Facilities message";
CM_ SG_ 2365458686 DirectionControl "Parameter used to respond to a request of a facility of a tractor ECU";
CM_ SG_ 2365458686 SelectedMachineSpeedControl "Parameter used to respond to a request of a facility of a tractor ECU";
CM_ SG_ 2365458686 SelectedMachineSpeed "Parameter used to respond to a request of a facility of a tractor ECU";
CM_ SG_ 2365458686 OperatorExternalLightControls "Parameter used to respond to a request of a facility of a tractor ECU";
CM_ SG_ 2365458686 LimitStatusReporting "Parameter used to respond to a request of a facility of a tractor ECU";
CM_ BO_ 2365458928 "Tractor Facilities response message";
CM_ SG_ 2365458928 LimitStatusReporting "Parameter used to respond to a request of a facility of a tractor ECU";
CM_ BO_ 2633895166 "Working Set Member";
CM_ BO_ 2633895422 "Working Set Master";
CM_ BO_ 2566787056 "Language Command";
CM_ BO_ 2365460720 "Esimated flow of auxiliary valve number 0 ";
CM_ SG_ 2365460720 Valve0LimitStatus "Parameter used to report the tractor ECUs present limit status associated with a parameter whose commands are persistent";
CM_ BO_ 2365460976 "Esimated flow of auxiliary valve number 0 ";
CM_ SG_ 2365460976 Valve1LimitStatus "Parameter used to report the tractor ECUs present limit status associated with a parameter whose commands are persistent";
CM_ BO_ 2365461232 "Esimated flow of auxiliary valve number 0 ";
CM_ SG_ 2365461232 Valve2LimitStatus "Parameter used to report the tractor ECUs present limit status associated with a parameter whose commands are persistent";
CM_ BO_ 2365461488 "Esimated flow of auxiliary valve number 0 ";
CM_ SG_ 2365461488 Valve3LimitStatus "Parameter used to report the tractor ECUs present limit status associated with a parameter whose commands are persistent";
CM_ BO_ 2365464816 "Auxiliary valve measured flow";
CM_ SG_ 2365464816 Valve0LimitStatus "Parameter used to report the tractor ECUs present limit status associated with a parameter whose commands are persistent";
CM_ BO_ 2365465072 "Auxiliary valve measured flow";
CM_ SG_ 2365465072 Valve1LimitStatus "Parameter used to report the tractor ECUs present limit status associated with a parameter whose commands are persistent";
CM_ BO_ 2365465328 "Auxiliary valve measured flow";
CM_ SG_ 2365465328 Valve2LimitStatus "Parameter used to report the tractor ECUs present limit status associated with a parameter whose commands are persistent";
CM_ BO_ 2365465584 "Auxiliary valve measured flow";
CM_ SG_ 2365465584 Valve3LimitStatus "Parameter used to report the tractor ECUs present limit status associated with a parameter whose commands are persistent";
CM_ BO_ 2365473264 "Lighting Command";
CM_ BO_ 2365473534 "Hitch and PTO Commands";
CM_ BO_ 2365473776 "Primary or Rear Power Take off Output Shaft
";
CM_ SG_ 2365473776 RearPTOShaftSpeedLimitStatus "Parameter used to report the tractor ECUs present limit status associated with a parameter whose commands are persistent";
CM_ SG_ 2365473776 RearPTOModeRqStatus "Parameter used to report the tractor ECUs status associated with a parameter whose requests are transient.";
CM_ SG_ 2365473776 RearPTOEngagementRqStatus "Parameter used to report the tractor ECUs status associated with a parameter whose requests are transient.";
CM_ SG_ 2365473776 RearPTOEconomyModeRqStatus "Parameter used to report the tractor ECUs status associated with a parameter whose requests are transient.";
CM_ BO_ 2365474032 "Secondary or Front Power Take off Output-Shaft";
CM_ SG_ 2365474032 FrontPTOShaftSpeedLimitStatus "Parameter used to report the tractor ECUs present limit status associated with a parameter whose commands are persistent";
CM_ SG_ 2365474032 FrontPTOModeRqStatus "Parameter used to report the tractor ECUs status associated with a parameter whose requests are transient.";
CM_ SG_ 2365474032 FrontPTOEconomyModeRqStatus "Parameter used to report the tractor ECUs status associated with a parameter whose requests are transient.";
CM_ SG_ 2365474032 FrontPTOEngagementRqStatus "Parameter used to report the tractor ECUs status associated with a parameter whose requests are transient.";
CM_ BO_ 2365474288 "Primary or Rear Hitch Status";
CM_ SG_ 2365474288 RearHitchPositionLimitStatus "Parameter used to report the tractor ECUs present limit status associated with a parameter whose commands are persistent";
CM_ BO_ 2365474544 "Secondary or Front Hitch Status";
CM_ SG_ 2365474544 FrontHitchPositionLimitStatus "Parameter used to report the tractor ECUs present limit status associated with a parameter whose commands are persistent";
CM_ BO_ 2566801406 "Maintain Power";
CM_ BO_ 2365475056 "Wheel-based Speed and Distance";
CM_ SG_ 2365475056 OperatorDirectionReversed "This parameter indicates whether the reported direction is reversed from the perspective of the operator.";
CM_ BO_ 2365475312 "Ground-based Speed and Distance";
CM_ BO_ 2566842096 "Time/Date";
CM_ BO_ 2583168284 "This PGN conveys a comprehensive set of Global Navigation Satellite System (GNSS) parameters, including position 
information
";
CM_ SG_ 2583168284 SequenceID "An upward counting number used to tie related information together between different PGNs.
";
CM_ SG_ 2583168284 PositionDate "Days since January 1, 1970,  Date is relative to UTC Time";
CM_ SG_ 2583168284 PositionTime "Seconds since midnight, time is in UTC";
CM_ SG_ 2583168284 Latitude "Latitude referenced to WGS-84";
CM_ SG_ 2583168284 Longitude "Longitude referenced to WGS-84";
CM_ SG_ 2583168284 Altitude "Altitude referenced to WGS-84";
CM_ SG_ 2583168284 NumberOfSVs "Numeric count, event counter, sequence counter";
CM_ SG_ 2583168284 HDOP "Dilution of Precision (DOP) indicates the contribution of satellite configuration geometry to positioning error
";
CM_ SG_ 2583168284 PDOP "Dilution of Precision (DOP) indicates the contribution of satellite configuration geometry to positioning error
";
CM_ SG_ 2583168284 GeoidalSeparation "The difference between the earth ellipsoid and mean-sea-level (geoid) defined by the reference datum used in the position solution ' -' = mean-sea-level below ellipsoid
";
CM_ SG_ 2583168284 NumberOfReferenceStations "Numeric count, event counter, sequence counter";
CM_ SG_ 2583168284 ReferenceStationID1 "Reference Station ID";
CM_ SG_ 2583168284 AgeOfDGNSSCorrections1 "Age of Differential corrections";
CM_ BO_ 2314731804 "This PGN provides latitude and longitude referenced to WGS84";
CM_ BO_ 2563309310 "Extended TP (Command)";
CM_ BO_ 2563243774 "Extended TP (Data)";
CM_ BO_ 2364540144 "Electronic Engine Controller #1";
CM_ SG_ 2364540144 ActualEngPercentTorque "The calculated output torque of the engine.";
CM_ SG_ 2364540144 DriversDemandEngPercentTorque "The requested torque output of the engine by the driver.";
CM_ SG_ 2364540144 EngStarterMode "There are several phases in a starting action and different reasons why a start cannot take place.";
CM_ SG_ 2364540144 EngTorqueMode "State signal which indicates which engine torque mode is currently generating, limiting, or controlling the torque.";
CM_ SG_ 2364540144 SrcAddrssOfCtrllngDvcForEngCtrl "The source address of the SAE J1939 device currently controlling the engine.";
BA_DEF_ SG_  "GenSigStartValue" INT -2147483648 2147483647;
BA_DEF_ SG_  "GenSigSendType" ENUM  "Cyclic","OnWrite","OnWriteWithRepetition","OnChange","OnChangeWithRepetition","IfActive","IfActiveWithRepetition","NoSigSendType";
BA_DEF_ SG_  "SigType" ENUM  "Default","Range","RangeSigned","ASCII","Discrete","Control","ReferencePGN","DTC","StringDelimiter","StringLength","StringLengthControl";
BA_DEF_ SG_  "SPN" INT 0 524287;
BA_DEF_ BO_  "GenMsgRequestable" INT 0 1;
BA_DEF_ BO_  "GenMsgCycleTime" INT 0 3600000;
BA_DEF_ BO_  "GenMsgSendType" ENUM  "cyclic","reserved","cyclicIfActive","reserved","reserved","reserved","reserved","reserved","noMsgSendType","vector_leerstring";
BA_DEF_ BO_  "VFrameFormat" ENUM  "StandardCAN","ExtendedCAN","reserved","J1939PG","vector_leerstring";
BA_DEF_ BO_  "SingleFrame" INT 0 1;
BA_DEF_ SG_  "DDI" INT 0 65535;
BA_DEF_ SG_  "SystemSignalLongSymbol" STRING ;
BA_DEF_DEF_  "GenSigStartValue" 0;
BA_DEF_DEF_  "GenSigSendType" "NoSigSendType";
BA_DEF_DEF_  "SigType" "Default";
BA_DEF_DEF_  "SPN" 0;
BA_DEF_DEF_  "GenMsgRequestable" 1;
BA_DEF_DEF_  "GenMsgCycleTime" 0;
BA_DEF_DEF_  "GenMsgSendType" "noMsgSendType";
BA_DEF_DEF_  "VFrameFormat" "J1939PG";
BA_DEF_DEF_  "SingleFrame" 1;
BA_DEF_DEF_  "DDI" 0;
BA_DEF_DEF_  "SystemSignalLongSymbol" "";
BA_ "GenMsgCycleTime" BO_ 2632384038 100;
BA_ "GenMsgCycleTime" BO_ 2565340800 1000;
BA_ "GenMsgSendType" BO_ 2565340800 2;
BA_ "GenMsgCycleTime" BO_ 2365458686 100;
BA_ "GenMsgCycleTime" BO_ 2365458928 100;
BA_ "GenMsgCycleTime" BO_ 2566787056 100;
BA_ "GenMsgCycleTime" BO_ 2365460720 100;
BA_ "GenMsgSendType" BO_ 2365460720 8.60420065262731E-317;
BA_ "GenMsgCycleTime" BO_ 2365460976 100;
BA_ "GenMsgSendType" BO_ 2365460976 8.60320856881046E-317;
BA_ "GenMsgCycleTime" BO_ 2365461232 100;
BA_ "GenMsgSendType" BO_ 2365461232 8.60221253246844E-317;
BA_ "GenMsgCycleTime" BO_ 2365461488 100;
BA_ "GenMsgSendType" BO_ 2365461488 8.60122044865159E-317;
BA_ "GenMsgCycleTime" BO_ 2365464816 100;
BA_ "GenMsgSendType" BO_ 2365464816 8.58832335903256E-317;
BA_ "GenMsgCycleTime" BO_ 2365465072 100;
BA_ "GenMsgSendType" BO_ 2365465072 8.58741032571904E-317;
BA_ "GenMsgCycleTime" BO_ 2365465328 100;
BA_ "GenMsgSendType" BO_ 2365465328 8.58649729240553E-317;
BA_ "GenMsgCycleTime" BO_ 2365465584 100;
BA_ "GenMsgSendType" BO_ 2365465584 8.58558425909201E-317;
BA_ "GenMsgCycleTime" BO_ 2365473264 100;
BA_ "GenMsgCycleTime" BO_ 2365473534 1000;
BA_ "GenMsgSendType" BO_ 2365473534 8.54526850239137E-317;
BA_ "GenMsgCycleTime" BO_ 2365473776 100;
BA_ "GenMsgSendType" BO_ 2365473776 2;
BA_ "GenMsgCycleTime" BO_ 2365474032 100;
BA_ "GenMsgCycleTime" BO_ 2365474288 100;
BA_ "GenMsgSendType" BO_ 2365474288 8.54054523481712E-317;
BA_ "GenMsgCycleTime" BO_ 2365474544 100;
BA_ "GenMsgSendType" BO_ 2365474544 8.53967963180561E-317;
BA_ "GenMsgCycleTime" BO_ 2566801406 100;
BA_ "GenMsgCycleTime" BO_ 2365475056 100;
BA_ "GenMsgSendType" BO_ 2365475056 8.53733973690691E-317;
BA_ "GenMsgCycleTime" BO_ 2365475312 100;
BA_ "GenMsgSendType" BO_ 2365475312 8.53594844804822E-317;
BA_ "GenMsgCycleTime" BO_ 2566842096 100;
BA_ "SingleFrame" BO_ 2583168284 0;
BA_ "GenMsgCycleTime" BO_ 2583168284 100;
BA_ "GenMsgSendType" BO_ 2583168284 8.52390115134002E-317;
BA_ "GenMsgCycleTime" BO_ 2314731804 100;
BA_ "GenMsgSendType" BO_ 2314731804 8.51951780093012E-317;
BA_ "GenMsgCycleTime" BO_ 2364540144 100;
BA_ "GenMsgSendType" BO_ 2364540144 8.51488148890955E-317;
BA_ "SigType" SG_ 2632384038 AuxiliaryFunctionObjectID 1;
BA_ "SigType" SG_ 2632384038 AuxiliaryInputObjectID 1;
BA_ "SigType" SG_ 2632384038 SelfConfigurableAddress 4;
BA_ "SigType" SG_ 2632384038 DeviceClassInstance 4;
BA_ "SigType" SG_ 2632384038 IndustryGroup 4;
BA_ "SigType" SG_ 2632384038 FontType_ProportionalFont 4;
BA_ "SigType" SG_ 2632384038 FontType_FlashHidden 4;
BA_ "SigType" SG_ 2632384038 FontType_FlashInverted 4;
BA_ "SigType" SG_ 2632384038 FontType_InvertedText 4;
BA_ "SigType" SG_ 2632384038 FontType_ItalicsText 4;
BA_ "SigType" SG_ 2632384038 FontType_UnderlinedText 4;
BA_ "SigType" SG_ 2632384038 FontType_CrossedOutText 4;
BA_ "SigType" SG_ 2632384038 DeviceClass 1;
BA_ "SigType" SG_ 2632384038 VTFunctionCode 1;
BA_ "SigType" SG_ 2632384038 FontType_BoldText 4;
BA_ "SigType" SG_ 2632384038 NumberOfPhysicalSoftKeys 1;
BA_ "SigType" SG_ 2632384038 VTBusyCode8 4;
BA_ "SigType" SG_ 2632384038 FontSize_128x192 4;
BA_ "SigType" SG_ 2632384038 FontSize_128x128 4;
BA_ "SigType" SG_ 2632384038 VTBusyCode5 4;
BA_ "SigType" SG_ 2632384038 FontSize_96x128 4;
BA_ "SigType" SG_ 2632384038 ErrorCodeChangeListItem4 4;
BA_ "SigType" SG_ 2632384038 VTBusyCode4 4;
BA_ "SigType" SG_ 2632384038 FontSize_64x96 4;
BA_ "SigType" SG_ 2632384038 ErrorCodeObjectPool4 4;
BA_ "SigType" SG_ 2632384038 VTBusyCode3 4;
BA_ "SigType" SG_ 2632384038 FontSize_64x64 4;
BA_ "SigType" SG_ 2632384038 ErrorCodeChangeListItem3 4;
BA_ "SigType" SG_ 2632384038 ErrorCodeObjectPool3 4;
BA_ "SigType" SG_ 2632384038 VTBusyCode2 4;
BA_ "SigType" SG_ 2632384038 FontSize_48x64 4;
BA_ "SigType" SG_ 2632384038 ErrorCodeChangeListItem2 4;
BA_ "SigType" SG_ 2632384038 ErrorCodeObjectPool2 4;
BA_ "SigType" SG_ 2632384038 VTBusyCode1 4;
BA_ "SigType" SG_ 2632384038 NrOfYPixelsInDataAreaMask 1;
BA_ "SigType" SG_ 2632384038 FontSize_32x48 4;
BA_ "SigType" SG_ 2632384038 NumberOfPossibleVirtualSoftKeys 1;
BA_ "SigType" SG_ 2632384038 ErrorCodeChangeListItem1 4;
BA_ "SigType" SG_ 2632384038 Function 1;
BA_ "SigType" SG_ 2632384038 ErrorCodeObjectPool1 4;
BA_ "SigType" SG_ 2632384038 VTChangeActiveMaskParentID 1;
BA_ "SigType" SG_ 2632384038 ButtonKeyCode 1;
BA_ "SigType" SG_ 2632384038 SoftKeyCode 1;
BA_ "SigType" SG_ 2632384038 FontSize_32x32 4;
BA_ "SigType" SG_ 2632384038 FontSize_24x32 4;
BA_ "SigType" SG_ 2632384038 FontSize_16x24 4;
BA_ "SigType" SG_ 2632384038 ErrorCodeChangePosInvalidError 4;
BA_ "SigType" SG_ 2632384038 ErrorCodeChangeSoftKeyMask5 4;
BA_ "SigType" SG_ 2632384038 ErrorCodeChangeChildLocation5 4;
BA_ "SigType" SG_ 2632384038 ErrorCodeVTChangeSoftKeyMask5 4;
BA_ "SigType" SG_ 2632384038 ErrorCodeVtObjPoolError4 4;
BA_ "SigType" SG_ 2632384038 FontSize_16x16 4;
BA_ "SigType" SG_ 2632384038 ErrorCodeChangeStrError 4;
BA_ "SigType" SG_ 2632384038 ErrorCodeChangeSoftKeyMask4 4;
BA_ "SigType" SG_ 2632384038 FunctionInstance 1;
BA_ "SigType" SG_ 2632384038 ErrorCodeVTChangeSoftKeyMask4 4;
BA_ "SigType" SG_ 2632384038 ErrorCodeVtObjPoolError3 4;
BA_ "SigType" SG_ 2632384038 FontSize_12x16 4;
BA_ "SigType" SG_ 2632384038 ErrorCodeChangeStrTooLong 4;
BA_ "SigType" SG_ 2632384038 ErrorCodeChangeSoftKeyMask3 4;
BA_ "SigType" SG_ 2632384038 ErrorCodeVTChangeSoftKeyMask3 4;
BA_ "SigType" SG_ 2632384038 ErrorCodeVtObjPoolError2 4;
BA_ "SigType" SG_ 2632384038 FontSize_8x12 4;
BA_ "SigType" SG_ 2632384038 ErrorCodeChangePosInvalidObject 4;
BA_ "SigType" SG_ 2632384038 ErrorCodeChangeStrObjectID 4;
BA_ "SigType" SG_ 2632384038 ErrorCodeChangeSoftKeyMask2 4;
BA_ "SigType" SG_ 2632384038 ErrorCodeChangeChildLocation2 4;
BA_ "SigType" SG_ 2632384038 ErrorCodeVTChangeSoftKeyMask2 4;
BA_ "SigType" SG_ 2632384038 ErrorCodeVtObjPoolError1 4;
BA_ "SigType" SG_ 2632384038 AcknowledgmentDeleteVersion 4;
BA_ "SigType" SG_ 2632384038 AcknowledgmentLoadVersion 4;
BA_ "SigType" SG_ 2632384038 AcknowledgmentStoreVersion 4;
BA_ "SigType" SG_ 2632384038 FontSize_8x8 4;
BA_ "SigType" SG_ 2632384038 YDotsForSoftKeyDescriptor 1;
BA_ "SigType" SG_ 2632384038 ErrorCodeChangePosInvalidParent 4;
BA_ "SigType" SG_ 2632384038 ErrorCodeChangeSoftKeyMask1 4;
BA_ "SigType" SG_ 2632384038 ErrorCodeChangeChildLocation1 4;
BA_ "SigType" SG_ 2632384038 Value2 1;
BA_ "SigType" SG_ 2632384038 ECUInstance 4;
BA_ "SigType" SG_ 2632384038 ErrorCodeVTChangeSoftKeyMask1 4;
BA_ "SigType" SG_ 2632384038 ErrorCodeChangePriority3 4;
BA_ "SigType" SG_ 2632384038 ErrorCodeChangeAttribute4 4;
BA_ "SigType" SG_ 2632384038 ErrorCodeChangeColour3 4;
BA_ "SigType" SG_ 2632384038 ErrorCodeSelectObject5 4;
BA_ "SigType" SG_ 2632384038 ErrorCodeEnableDisableObj4 4;
BA_ "SigType" SG_ 2632384038 ErrorCodeSelectObject4 4;
BA_ "SigType" SG_ 2632384038 ErrorCodeEnableDisableObj3 4;
BA_ "SigType" SG_ 2632384038 ErrorCodeHideShowObj3 4;
BA_ "SigType" SG_ 2632384038 ErrorCodeChangeAttribute3 4;
BA_ "SigType" SG_ 2632384038 ErrorCodeSelectObject3 4;
BA_ "SigType" SG_ 2632384038 ErrorCodeEnableDisableObj2 4;
BA_ "SigType" SG_ 2632384038 ErrorCodeChangePriority2 4;
BA_ "SigType" SG_ 2632384038 ErrorCodeChangeAttribute2 4;
BA_ "SigType" SG_ 2632384038 ErrorCodeChangeColour2 4;
BA_ "SigType" SG_ 2632384038 ErrorCodeSelectObject2 4;
BA_ "SigType" SG_ 2632384038 ErrorCodeEnableDisableObj1 4;
BA_ "SigType" SG_ 2632384038 ErrorCodeHideShowObj2 4;
BA_ "SigType" SG_ 2632384038 VisibleSoftKeyMaskObjectID 1;
BA_ "SigType" SG_ 2632384038 NrOfXPixelsInDataAreaMask 1;
BA_ "SigType" SG_ 2632384038 XDotsForSoftKeyDescriptor 1;
BA_ "SigType" SG_ 2632384038 NewObjectID 1;
BA_ "SigType" SG_ 2632384038 ErrorCodeChangePriority1 4;
BA_ "SigType" SG_ 2632384038 ErrorCodeChangeAttribute1 4;
BA_ "SigType" SG_ 2632384038 ValueOfTheObject 1;
BA_ "SigType" SG_ 2632384038 ErrorCodeChangeColour1 4;
BA_ "SigType" SG_ 2632384038 ErrorCodeSelectObject1 4;
BA_ "SigType" SG_ 2632384038 ErrorCodeHideShowObj1 4;
BA_ "SigType" SG_ 2632384038 ObjectIdOfFaultyObject 1;
BA_ "SigType" SG_ 2632384038 VTChangeActiveMaskErrorID 1;
BA_ "SigType" SG_ 2632384038 VTChangeNumericValueValue 1;
BA_ "SigType" SG_ 2632384038 VTSelectInputObjectIsEdited 1;
BA_ "SigType" SG_ 2632384038 ButtonObjectParentID 1;
BA_ "SigType" SG_ 2632384038 KeyObjectParentID 1;
BA_ "SigType" SG_ 2632384038 ErrorCodeChangeFont6 4;
BA_ "SigType" SG_ 2632384038 ManufacturerCode 1;
BA_ "SPN" SG_ 2632384038 ManufacturerCode 2838;
BA_ "SigType" SG_ 2632384038 ErrorCodePoolDeleted 4;
BA_ "SigType" SG_ 2632384038 ErrorCodeChangeActiveMask5 4;
BA_ "SigType" SG_ 2632384038 ErrorCodeChangeFillAttributes5 4;
BA_ "SigType" SG_ 2632384038 ErrorCodeChangeLineAttribute4 4;
BA_ "SigType" SG_ 2632384038 ErrorCodeChangeFont5 4;
BA_ "SigType" SG_ 2632384038 ErrorCodeChangeEditPoint3 4;
BA_ "SigType" SG_ 2632384038 ErrorCodeObjToSize4 4;
BA_ "SigType" SG_ 2632384038 ErrorCodeEscapeObj2 4;
BA_ "SigType" SG_ 2632384038 ErrorCodeAnyOtherError 4;
BA_ "SigType" SG_ 2632384038 ErrorCodeVTEsc2 4;
BA_ "SigType" SG_ 2632384038 Hardware4 4;
BA_ "SigType" SG_ 2632384038 ErrorCodeChangeActiveMask4 4;
BA_ "SigType" SG_ 2632384038 ErrorCodeChangeFillAttributes4 4;
BA_ "SigType" SG_ 2632384038 ErrorCodeChangeFont4 4;
BA_ "SigType" SG_ 2632384038 ErrorCodeMaskOrChildObjectError 4;
BA_ "SigType" SG_ 2632384038 ErrorCodeChangeNumValue3 4;
BA_ "SigType" SG_ 2632384038 Hardware3 4;
BA_ "SigType" SG_ 2632384038 ErrorCodeChangeActiveMask3 4;
BA_ "SigType" SG_ 2632384038 ErrorCodeChangeFillAttributes3 4;
BA_ "SigType" SG_ 2632384038 ErrorCodeChangeLineAttribute3 4;
BA_ "SigType" SG_ 2632384038 ErrorCodeChangeFont3 4;
BA_ "SigType" SG_ 2632384038 ErrorCodeObjToSize3 4;
BA_ "SigType" SG_ 2632384038 ErrorCodeMissingObjects 4;
BA_ "SigType" SG_ 2632384038 Hardware2 4;
BA_ "SigType" SG_ 2632384038 ErrorCodeChangeActiveMask2 4;
BA_ "SigType" SG_ 2632384038 ErrorCodeChangeFillAttributes2 4;
BA_ "SigType" SG_ 2632384038 ErrorCodeChangeLineAttribute2 4;
BA_ "SigType" SG_ 2632384038 ErrorCodeChangeFont2 4;
BA_ "SigType" SG_ 2632384038 ErrorCodeChangeEditPoint2 4;
BA_ "SigType" SG_ 2632384038 ErrorCodeChangeNumValue2 4;
BA_ "SigType" SG_ 2632384038 ErrorCodeObjToSize2 4;
BA_ "SigType" SG_ 2632384038 ObjectIDOfFaultyObject 1;
BA_ "SigType" SG_ 2632384038 Hardware1 4;
BA_ "SigType" SG_ 2632384038 ListIndex 1;
BA_ "SigType" SG_ 2632384038 NewPriority 1;
BA_ "SigType" SG_ 2632384038 SoftKeyMaskObjectID 1;
BA_ "SigType" SG_ 2632384038 ErrorCodeChangeActiveMask1 4;
BA_ "SigType" SG_ 2632384038 ErrorCodeChangeFillAttributes1 4;
BA_ "SigType" SG_ 2632384038 ErrorCodeChangeLineAttribute1 4;
BA_ "SigType" SG_ 2632384038 ErrorCodeChangeFont1 4;
BA_ "SigType" SG_ 2632384038 ErrorCodeChangeEditPoint1 4;
BA_ "SigType" SG_ 2632384038 ErrorCodeChangeNumValue1 4;
BA_ "SigType" SG_ 2632384038 NewBackgroundColour 1;
BA_ "SigType" SG_ 2632384038 ErrorCodeObjToSize1 4;
BA_ "SigType" SG_ 2632384038 ObjectSelectStatus 1;
BA_ "SigType" SG_ 2632384038 ObjectEnableStatus 1;
BA_ "SigType" SG_ 2632384038 ObjectShowStatus 1;
BA_ "SigType" SG_ 2632384038 ErrorCodeEscapeObj1 4;
BA_ "SigType" SG_ 2632384038 Value1 1;
BA_ "SigType" SG_ 2632384038 EnteredStringValue 9;
BA_ "SigType" SG_ 2632384038 VTChangeSoftKeyMaskObjectID 1;
BA_ "SigType" SG_ 2632384038 ErrorCodeVTEsc1 4;
BA_ "SigType" SG_ 2632384038 VTSelectInputObjectStatus 1;
BA_ "SigType" SG_ 2632384038 YPosition 1;
BA_ "SigType" SG_ 2632384038 VisibleDataOrAlarmMaskObjectID 1;
BA_ "SigType" SG_ 2632384038 VersionLables 3;
BA_ "SigType" SG_ 2632384038 MemoryStatus 1;
BA_ "SigType" SG_ 2632384038 ButtonObjectID 1;
BA_ "SigType" SG_ 2632384038 KeyObjectID 1;
BA_ "SystemSignalLongSymbol" SG_ 2632384038 BckgndColourUserLayoutSoftk_0000 "BckgndColourUserLayoutSoftkeyMask";
BA_ "SigType" SG_ 2632384038 ErrorCodeDeleteObjectPool2 4;
BA_ "SigType" SG_ 2632384038 ErrorCodeAudioVolume2 4;
BA_ "SigType" SG_ 2632384038 ErrorCodeControlAudioDevice2 4;
BA_ "SigType" SG_ 2632384038 ErrorCodeEndOfObjectPool3 4;
BA_ "SigType" SG_ 2632384038 ErrorCodeEndOfObjectPool2 4;
BA_ "SigType" SG_ 2632384038 SourceAdressOfActiveWSM 1;
BA_ "SigType" SG_ 2632384038 NrOfVersionStrings 1;
BA_ "SigType" SG_ 2632384038 VersionNumberISO11783Part6 1;
BA_ "SystemSignalLongSymbol" SG_ 2632384038 ChangeChildPositionParentOb_0000 "ChangeChildPositionParentObjectID";
BA_ "SigType" SG_ 2632384038 ErrorCodeDeleteObjectPool1 4;
BA_ "SigType" SG_ 2632384038 ListInputObjectID 1;
BA_ "SigType" SG_ 2632384038 AlarmMaskObjectID 1;
BA_ "SigType" SG_ 2632384038 ObjectToChangeAttributeID 1;
BA_ "SigType" SG_ 2632384038 DataOrAlarmMaskObjectID 1;
BA_ "SigType" SG_ 2632384038 ActiveMaskObjectID 1;
BA_ "SigType" SG_ 2632384038 ObjectToChangeFillAttributesID 1;
BA_ "SigType" SG_ 2632384038 ObjectToChangeLineAttributeID 1;
BA_ "SigType" SG_ 2632384038 ObjectToChangeFontID 1;
BA_ "SigType" SG_ 2632384038 ObjectToChangeEndPointID 1;
BA_ "SigType" SG_ 2632384038 ObjectToChangeNumValueID 1;
BA_ "SigType" SG_ 2632384038 ObjectToChangeColourID 1;
BA_ "SigType" SG_ 2632384038 ObjectToSizeID 1;
BA_ "SystemSignalLongSymbol" SG_ 2632384038 ChangeChildLocationParentOb_0000 "ChangeChildLocationParentObjectID";
BA_ "SigType" SG_ 2632384038 ErrorCodeAudioVolume1 4;
BA_ "SigType" SG_ 2632384038 ErrorCodeControlAudioDevice1 4;
BA_ "SigType" SG_ 2632384038 SelectInputObjectID 1;
BA_ "SigType" SG_ 2632384038 ObjectToEnableDisableID 1;
BA_ "SigType" SG_ 2632384038 ObjectToHideShowID 1;
BA_ "SigType" SG_ 2632384038 ObjectEscapeID 1;
BA_ "SigType" SG_ 2632384038 InputStatusObjectId 1;
BA_ "SigType" SG_ 2632384038 InputObjectId 1;
BA_ "SigType" SG_ 2632384038 IdentityNumber 1;
BA_ "SigType" SG_ 2632384038 ErrorCodeEndOfObjectPool1 4;
BA_ "SigType" SG_ 2632384038 ObjectToChangeStringID 1;
BA_ "SigType" SG_ 2632384038 VTChangeSoftKeyMaskParentID 1;
BA_ "SigType" SG_ 2632384038 VTChangeActiveMaskObjectID 1;
BA_ "SigType" SG_ 2632384038 VTChangeNumericValueObjectID 1;
BA_ "SigType" SG_ 2632384038 VTEscObjectID 1;
BA_ "SigType" SG_ 2632384038 VTSelectInputObjectID 1;
BA_ "SigType" SG_ 2632384038 XPosition 1;
BA_ "SigType" SG_ 2632384038 ButtonActivationCode 1;
BA_ "SigType" SG_ 2632384038 KeyActivationCode 1;
BA_ "SigType" SG_ 2632384038 VTFunctionVTtoECU 1;
BA_ "SigType" SG_ 2565340800 VTFunctionECUtoVT 1;
BA_ "SigType" SG_ 2565340800 KeyActivationCode 1;
BA_ "SigType" SG_ 2565340800 KeyObjectParentID 1;
BA_ "SigType" SG_ 2565340800 KeyObjectID 1;
BA_ "SigType" SG_ 2565340800 SoftKeyCode 1;
BA_ "SigType" SG_ 2565340800 ButtonActivationCode 1;
BA_ "SigType" SG_ 2565340800 ButtonObjectID 1;
BA_ "SigType" SG_ 2565340800 ButtonObjectParentID 1;
BA_ "SigType" SG_ 2565340800 ButtonKeyCode 1;
BA_ "SigType" SG_ 2565340800 XPosition 1;
BA_ "SigType" SG_ 2565340800 YPosition 1;
BA_ "SigType" SG_ 2565340800 VTSelectInputObjectID 1;
BA_ "SigType" SG_ 2565340800 VTSelectInputObjectStatus 1;
BA_ "SigType" SG_ 2565340800 VTEscObjectID 1;
BA_ "SigType" SG_ 2565340800 VTChangeNumericValueObjectID 1;
BA_ "SigType" SG_ 2565340800 VTChangeNumericValueValue 1;
BA_ "SigType" SG_ 2565340800 VTChangeActiveMaskObjectID 1;
BA_ "SigType" SG_ 2565340800 VTChangeSoftKeyMaskParentID 1;
BA_ "SigType" SG_ 2565340800 VTChangeSoftKeyMaskObjectID 1;
BA_ "SigType" SG_ 2565340800 ObjectToChangeStringValueID 1;
BA_ "SigType" SG_ 2565340800 ObjectPoolRecord 1;
BA_ "SigType" SG_ 2565340800 AuxiliaryFunctionObjectID 1;
BA_ "SigType" SG_ 2565340800 AssignmentErrorNotAccepted 4;
BA_ "SigType" SG_ 2565340800 IsEnabled 1;
BA_ "SigType" SG_ 2565340800 InputStatusObjectId 1;
BA_ "SigType" SG_ 2565340800 ObjectToShowHideID 1;
BA_ "SigType" SG_ 2565340800 ShowOrHide 1;
BA_ "SigType" SG_ 2565340800 ObjectoEnableDisbaleID 1;
BA_ "SigType" SG_ 2565340800 EnableOrDisable 1;
BA_ "SigType" SG_ 2565340800 SelectInputObjectID 1;
BA_ "SigType" SG_ 2565340800 NumberOfRepetitions_Audio 1;
BA_ "SigType" SG_ 2565340800 Frequency_Audio 1;
BA_ "SigType" SG_ 2565340800 OnTimeDuration_Audio 1;
BA_ "SigType" SG_ 2565340800 OffTimeDuration_Audio 1;
BA_ "SigType" SG_ 2565340800 AudioVolume 1;
BA_ "SigType" SG_ 2565340800 ObjectToMoveID 1;
BA_ "SigType" SG_ 2565340800 XPosChangeTopLeft 1;
BA_ "SigType" SG_ 2565340800 YPosChangeTopLeft 1;
BA_ "SigType" SG_ 2565340800 ObjectToSizeID 1;
BA_ "SigType" SG_ 2565340800 NewWidth 1;
BA_ "SigType" SG_ 2565340800 NewHeight 1;
BA_ "SigType" SG_ 2565340800 ObjectToChangeColourID 1;
BA_ "SigType" SG_ 2565340800 NewBackgroundColour 1;
BA_ "SigType" SG_ 2565340800 ObjectToChangeNumValueID 1;
BA_ "SigType" SG_ 2565340800 NewValue 1;
BA_ "SigType" SG_ 2565340800 ObjectToChangeEndPointID 1;
BA_ "SigType" SG_ 2565340800 Width 1;
BA_ "SigType" SG_ 2565340800 Height 1;
BA_ "SigType" SG_ 2565340800 LineDirection 1;
BA_ "SigType" SG_ 2565340800 ObjectToChangeFontID 1;
BA_ "SigType" SG_ 2565340800 FontColour 1;
BA_ "SigType" SG_ 2565340800 FontSize 1;
BA_ "SigType" SG_ 2565340800 FontType 1;
BA_ "SigType" SG_ 2565340800 FontStyle 1;
BA_ "SigType" SG_ 2565340800 ObjectToChangeLineAttributesID 1;
BA_ "SigType" SG_ 2565340800 LineColour 1;
BA_ "SigType" SG_ 2565340800 LineWidth 1;
BA_ "SigType" SG_ 2565340800 LineArt 1;
BA_ "SigType" SG_ 2565340800 ObjectToChangeFillAttributesID 1;
BA_ "SigType" SG_ 2565340800 FillType 1;
BA_ "SigType" SG_ 2565340800 FillColour 1;
BA_ "SigType" SG_ 2565340800 FillPatternObjectID 1;
BA_ "SigType" SG_ 2565340800 WorkingSetObjectID 1;
BA_ "SigType" SG_ 2565340800 NewActiveMaskObjectID 1;
BA_ "SigType" SG_ 2565340800 MaskType 1;
BA_ "SigType" SG_ 2565340800 DataOrAlarmMaskObjectID 1;
BA_ "SigType" SG_ 2565340800 NewSoftKeyMaskObjectID 1;
BA_ "SigType" SG_ 2565340800 ObjectToChangeAttributeID 1;
BA_ "SigType" SG_ 2565340800 AttributeID 1;
BA_ "SigType" SG_ 2565340800 NewAttributeValue 1;
BA_ "SigType" SG_ 2565340800 AlarmMaskObjectID 1;
BA_ "SigType" SG_ 2565340800 NewPriority 1;
BA_ "SigType" SG_ 2565340800 ListInputObjectID 1;
BA_ "SigType" SG_ 2565340800 ListIndex 1;
BA_ "SigType" SG_ 2565340800 NewObjectID 1;
BA_ "SigType" SG_ 2565340800 NewStringValue 9;
BA_ "SigType" SG_ 2565340800 MemoryRequired 1;
BA_ "SigType" SG_ 2565340800 VersionLabelToStore 3;
BA_ "SigType" SG_ 2565340800 VersionLabelToLoad 3;
BA_ "SigType" SG_ 2565340800 VersionLabelToDelete 3;
BA_ "SigType" SG_ 2565537534 RqstedPGN 6;
BA_ "SigType" SG_ 2632711934 SeqNumber 1;
BA_ "SigType" SG_ 2632711934 Byte1 1;
BA_ "SigType" SG_ 2632711934 Byte2 1;
BA_ "SigType" SG_ 2632711934 Byte3 1;
BA_ "SigType" SG_ 2632711934 Byte4 1;
BA_ "SigType" SG_ 2632711934 Byte5 1;
BA_ "SigType" SG_ 2632711934 Byte6 1;
BA_ "SigType" SG_ 2632711934 Byte7 1;
BA_ "SigType" SG_ 2632777470 ControlByte 1;
BA_ "GenSigStartValue" SG_ 2632777470 AckMsgSize 9;
BA_ "SigType" SG_ 2632777470 AckMsgSize 1;
BA_ "GenSigStartValue" SG_ 2632777470 BamMsgSize 9;
BA_ "SigType" SG_ 2632777470 BamMsgSize 1;
BA_ "GenSigStartValue" SG_ 2632777470 RtsMsgSize 9;
BA_ "SigType" SG_ 2632777470 RtsMsgSize 1;
BA_ "SigType" SG_ 2632777470 SendPackets 1;
BA_ "GenSigStartValue" SG_ 2632777470 ERtsMsgSize 1786;
BA_ "SigType" SG_ 2632777470 ERtsMsgSize 1;
BA_ "GenSigStartValue" SG_ 2632777470 ECtsNoPackets 1;
BA_ "SigType" SG_ 2632777470 ECtsNoPackets 1;
BA_ "GenSigStartValue" SG_ 2632777470 EDpoNoPackets 1;
BA_ "SigType" SG_ 2632777470 EDpoNoPackets 1;
BA_ "GenSigStartValue" SG_ 2632777470 EAckMsgSize 1786;
BA_ "SigType" SG_ 2632777470 EAckMsgSize 1;
BA_ "GenSigStartValue" SG_ 2632777470 NextPacket 1;
BA_ "SigType" SG_ 2632777470 NextPacket 1;
BA_ "GenSigStartValue" SG_ 2632777470 ECtsNextPacket 1;
BA_ "SigType" SG_ 2632777470 ECtsNextPacket 1;
BA_ "SigType" SG_ 2632777470 EDpoOffset 1;
BA_ "GenSigStartValue" SG_ 2632777470 AckNoPackets 1;
BA_ "SigType" SG_ 2632777470 AckNoPackets 1;
BA_ "GenSigStartValue" SG_ 2632777470 BamNoPackets 1;
BA_ "SigType" SG_ 2632777470 BamNoPackets 1;
BA_ "GenSigStartValue" SG_ 2632777470 RtsNoPackets 1;
BA_ "SigType" SG_ 2632777470 RtsNoPackets 1;
BA_ "SigType" SG_ 2632777470 PGNumber 6;
BA_ "SigType" SG_ 2632777470 RtsMaxPacketsPerCts 1;
BA_ "SigType" SG_ 2365458686 SpeedInfo_EngineSpeed 4;
BA_ "SigType" SG_ 2365458686 SpeedInfo_GroundBasedSpeed 4;
BA_ "SigType" SG_ 2365458686 SpeedInfo_WheelBasedSpeed 4;
BA_ "SigType" SG_ 2365458686 PowerMgt_MaintainPower 4;
BA_ "SigType" SG_ 2365458686 PowerMgt_MaxTimeTractorPower 4;
BA_ "SigType" SG_ 2365458686 PowerMgt_KeySwitch 4;
BA_ "SigType" SG_ 2365458686 TractorClass 4;
BA_ "SigType" SG_ 2365458686 LanguageCmdStorageInTractorECU 4;
BA_ "SigType" SG_ 2365458686 Lighting_MinimalSet 4;
BA_ "SigType" SG_ 2365458686 PTOInfo_RearShaftEngagement 4;
BA_ "SigType" SG_ 2365458686 PTOInfo_RearShaftSpeed 4;
BA_ "SigType" SG_ 2365458686 HitchInfo_RearInWork 4;
BA_ "SigType" SG_ 2365458686 HitchInfo_RearPosition 4;
BA_ "SigType" SG_ 2365458686 EstimatedOrMeasuredAuxValveState 4;
BA_ "SigType" SG_ 2365458686 Light_FullImplLightingMessageSet 4;
BA_ "SigType" SG_ 2365458686 AddHitchParameter_RearDraft 4;
BA_ "SigType" SG_ 2365458686 SpeedAndDist_WheelBasedDirection 4;
BA_ "SigType" SG_ 2365458686 SpeedAndDist_WheelBasedDistance 4;
BA_ "SigType" SG_ 2365458686 SpeedAndDist_GndBasedDirection 4;
BA_ "SigType" SG_ 2365458686 SpeedAndDist_GndBasedDistance 4;
BA_ "SigType" SG_ 2365458686 TimeDate 4;
BA_ "SigType" SG_ 2365458686 AuxiliaryValveCmd 4;
BA_ "SigType" SG_ 2365458686 PTOCmd_RearPTOEngagementCmd 4;
BA_ "SigType" SG_ 2365458686 PTOCmd_RearPTOSpeedCmd 4;
BA_ "SigType" SG_ 2365458686 HitchCmd_RearHitchPosition 4;
BA_ "SigType" SG_ 2365458686 NavigPseudorangeNoiseStatistic 4;
BA_ "SigType" SG_ 2365458686 NavigSystemPositionData 4;
BA_ "SigType" SG_ 2365458686 NavigSystemHighOutputPosition 4;
BA_ "SigType" SG_ 2365458686 PTOCmd_FrontPTOEngagementCmd 4;
BA_ "SigType" SG_ 2365458686 PTOCmd_FrontPTOSpeedCmd 4;
BA_ "SigType" SG_ 2365458686 HitchCmd_FrontHitchPosition 4;
BA_ "SigType" SG_ 2365458686 AddHitchParameter__FrontDraft 4;
BA_ "SigType" SG_ 2365458686 PTOInfo_FrontShaftEngagement 4;
BA_ "SigType" SG_ 2365458686 PTOInfo_FrontShaftSpeed 4;
BA_ "SigType" SG_ 2365458686 HitchInfo_FrontInWork 4;
BA_ "SigType" SG_ 2365458686 HitchInfo_FrontPosition 4;
BA_ "SigType" SG_ 2365458928 SpeedInfo_EngineSpeed 4;
BA_ "SigType" SG_ 2365458928 SpeedInfo_GroundBasedSpeed 4;
BA_ "SigType" SG_ 2365458928 SpeedInfo_WheelBasedSpeed 4;
BA_ "SigType" SG_ 2365458928 PowerMgt_MaintainPower 4;
BA_ "SigType" SG_ 2365458928 PowerMgt_MaxTimeTractorPower 4;
BA_ "SigType" SG_ 2365458928 PowerMgt_KeySwitch 4;
BA_ "SigType" SG_ 2365458928 TractorClass 4;
BA_ "SigType" SG_ 2365458928 LanguageCmdStorageInTractorECU 4;
BA_ "SigType" SG_ 2365458928 Lighting_MinimalSet 4;
BA_ "SigType" SG_ 2365458928 PTOInfo_RearShaftEngagement 4;
BA_ "SigType" SG_ 2365458928 PTOInfo_RearShaftSpeed 4;
BA_ "SigType" SG_ 2365458928 HitchInfo_RearInWork 4;
BA_ "SigType" SG_ 2365458928 HitchInfo_RearPosition 4;
BA_ "SigType" SG_ 2365458928 EstimatedOrMeasuredAuxValveState 4;
BA_ "SigType" SG_ 2365458928 Light_FullImplLightingMessageSet 4;
BA_ "SigType" SG_ 2365458928 AddHitchParameter_RearDraft 4;
BA_ "SigType" SG_ 2365458928 SpeedAndDist_WheelBasedDirection 4;
BA_ "SigType" SG_ 2365458928 SpeedAndDist_WheelBasedDistance 4;
BA_ "SigType" SG_ 2365458928 SpeedAndDist_GndBasedDirection 4;
BA_ "SigType" SG_ 2365458928 SpeedAndDist_GndBasedDistance 4;
BA_ "SigType" SG_ 2365458928 TimeDate 4;
BA_ "SigType" SG_ 2365458928 AuxiliaryValveCmd 4;
BA_ "SigType" SG_ 2365458928 PTOCmd_RearPTOEngagementCmd 4;
BA_ "SigType" SG_ 2365458928 PTOCmd_RearPTOSpeedCmd 4;
BA_ "SigType" SG_ 2365458928 HitchCmd_RearHitchPosition 4;
BA_ "SigType" SG_ 2365458928 NavigPseudorangeNoiseStatistic 4;
BA_ "SigType" SG_ 2365458928 NavigSystemPositionData 4;
BA_ "SigType" SG_ 2365458928 NavigSystemHighOutputPosition 4;
BA_ "SigType" SG_ 2365458928 PTOCmd_FrontPTOEngagementCmd 4;
BA_ "SigType" SG_ 2365458928 PTOCmd_FrontPTOSpeedCmd 4;
BA_ "SigType" SG_ 2365458928 HitchCmd_FrontHitchPosition 4;
BA_ "SigType" SG_ 2365458928 AddHitchParameter__FrontDraft 4;
BA_ "SigType" SG_ 2365458928 PTOInfo_FrontShaftEngagement 4;
BA_ "SigType" SG_ 2365458928 PTOInfo_FrontShaftSpeed 4;
BA_ "SigType" SG_ 2365458928 HitchInfo_FrontInWork 4;
BA_ "SigType" SG_ 2365458928 HitchInfo_FrontPosition 4;
BA_ "SigType" SG_ 2633895166 NameOfWorkingSetMember 1;
BA_ "GenSigStartValue" SG_ 2633895422 NumberOfMembersInWorkingSet 1;
BA_ "SigType" SG_ 2633895422 NumberOfMembersInWorkingSet 1;
BA_ "SigType" SG_ 2566787056 LanguageCodeCmd 3;
BA_ "SPN" SG_ 2566787056 LanguageCodeCmd 2410;
BA_ "SigType" SG_ 2566787056 TimeFormatCmd 4;
BA_ "SPN" SG_ 2566787056 TimeFormatCmd 2413;
BA_ "SigType" SG_ 2566787056 DecimalSymbolCmd 4;
BA_ "SPN" SG_ 2566787056 DecimalSymbolCmd 2411;
BA_ "SigType" SG_ 2566787056 DateFormatCmd 1;
BA_ "SPN" SG_ 2566787056 DateFormatCmd 2412;
BA_ "SigType" SG_ 2566787056 MassUnitCmd 4;
BA_ "SPN" SG_ 2566787056 MassUnitCmd 2417;
BA_ "SigType" SG_ 2566787056 VolumeUnitCmd 4;
BA_ "SPN" SG_ 2566787056 VolumeUnitCmd 2416;
BA_ "SigType" SG_ 2566787056 AreaUnitCmd 4;
BA_ "SPN" SG_ 2566787056 AreaUnitCmd 2415;
BA_ "SigType" SG_ 2566787056 DistanceUnitCmd 4;
BA_ "SPN" SG_ 2566787056 DistanceUnitCmd 2414;
BA_ "SigType" SG_ 2566787056 UnitsSystem 4;
BA_ "SigType" SG_ 2566787056 ForceUnits 4;
BA_ "SigType" SG_ 2566787056 PressureUnits 4;
BA_ "SigType" SG_ 2566787056 TemperatureUnits 4;
BA_ "SigType" SG_ 2365460720 Valve0LimitStatus 4;
BA_ "SigType" SG_ 2365460720 Valve0ExtendedPortEstimatedFlow 1;
BA_ "SigType" SG_ 2365460720 Valve0RetractPortEstimatedFlow 1;
BA_ "SigType" SG_ 2365460720 Valve0ValveState 4;
BA_ "SigType" SG_ 2365460720 Valve0FailSafeMode 4;
BA_ "SigType" SG_ 2365460976 Valve1LimitStatus 4;
BA_ "SigType" SG_ 2365460976 Valve1ExtendedPortEstimatedFlow 1;
BA_ "SigType" SG_ 2365460976 Valve1RetractPortEstimatedFlow 1;
BA_ "SigType" SG_ 2365460976 Valve1ValveState 4;
BA_ "SigType" SG_ 2365460976 Valve1FailSafeMode 4;
BA_ "SigType" SG_ 2365461232 Valve2LimitStatus 4;
BA_ "SigType" SG_ 2365461232 Valve2ExtendedPortEstimatedFlow 1;
BA_ "SigType" SG_ 2365461232 Valve2RetractPortEstimatedFlow 1;
BA_ "SigType" SG_ 2365461232 Valve2ValveState 4;
BA_ "SigType" SG_ 2365461232 Valve2FailSafeMode 4;
BA_ "SigType" SG_ 2365461488 Valve3LimitStatus 4;
BA_ "SigType" SG_ 2365461488 Valve3ExtendedPortEstimatedFlow 1;
BA_ "SigType" SG_ 2365461488 Valve3RetractPortEstimatedFlow 1;
BA_ "SigType" SG_ 2365461488 Valve3ValveState 4;
BA_ "SigType" SG_ 2365461488 Valve3FailSafeMode 4;
BA_ "SigType" SG_ 2365464816 Valve0LimitStatus 4;
BA_ "SigType" SG_ 2365464816 Valve0ExtendedPortMeasuredFlow 1;
BA_ "SigType" SG_ 2365464816 Valve0RetractPortMeasuredFlow 1;
BA_ "SigType" SG_ 2365464816 Valve0ExtendedPortPressure 1;
BA_ "SigType" SG_ 2365464816 Valve0RetractPortPressure 1;
BA_ "SigType" SG_ 2365464816 Valve0ReturnPortPressure 1;
BA_ "SigType" SG_ 2365465072 Valve1LimitStatus 4;
BA_ "SigType" SG_ 2365465072 Valve1ExtendedPortMeasuredFlow 1;
BA_ "SigType" SG_ 2365465072 Valve1RetractPortMeasuredFlow 1;
BA_ "SigType" SG_ 2365465072 Valve1ExtendedPortPressure 1;
BA_ "SigType" SG_ 2365465072 Valve1RetractPortPressure 1;
BA_ "SigType" SG_ 2365465072 Valve1ReturnPortPressure 1;
BA_ "SigType" SG_ 2365465328 Valve2LimitStatus 4;
BA_ "SigType" SG_ 2365465328 Valve2ExtendedPortMeasuredFlow 1;
BA_ "SigType" SG_ 2365465328 Valve2RetractPortMeasuredFlow 1;
BA_ "SigType" SG_ 2365465328 Valve2ExtendedPortPressure 1;
BA_ "SigType" SG_ 2365465328 Valve2RetractPortPressure 1;
BA_ "SigType" SG_ 2365465328 Valve2ReturnPortPressure 1;
BA_ "SigType" SG_ 2365465584 Valve3LimitStatus 4;
BA_ "SigType" SG_ 2365465584 Valve3ExtendedPortMeasuredFlow 1;
BA_ "SigType" SG_ 2365465584 Valve3RetractPortMeasuredFlow 1;
BA_ "SigType" SG_ 2365465584 Valve3ExtendedPortPressure 1;
BA_ "SigType" SG_ 2365465584 Valve3RetractPortPressure 1;
BA_ "SigType" SG_ 2365465584 Valve3ReturnPortPressure 1;
BA_ "SigType" SG_ 2365473264 DaytimeRunningLightCmd 4;
BA_ "SigType" SG_ 2365473264 AlternateHeadLightCmd 4;
BA_ "SigType" SG_ 2365473264 LowBeamHeadLightCmd 4;
BA_ "SigType" SG_ 2365473264 HighBeamHeadLightCmd 4;
BA_ "SigType" SG_ 2365473264 FrontFogLightCmd 4;
BA_ "SigType" SG_ 2365473264 RotatingBeaconLightCmd 4;
BA_ "SigType" SG_ 2365473264 RightTurnSignalLightCmd 4;
BA_ "SigType" SG_ 2365473264 LeftTurnSignalLightCmd 4;
BA_ "SigType" SG_ 2365473264 BackUpLightAndAlarmHornCmd 4;
BA_ "SigType" SG_ 2365473264 CentreStopLightCmd 4;
BA_ "SigType" SG_ 2365473264 RightStopLightCmd 4;
BA_ "SigType" SG_ 2365473264 LeftStopLightCmd 4;
BA_ "SigType" SG_ 2365473264 ImplementClearanceLightCmd 4;
BA_ "SigType" SG_ 2365473264 TractorClearanceLightCmd 4;
BA_ "SigType" SG_ 2365473264 ImplementMarkerLightCmd 4;
BA_ "SigType" SG_ 2365473264 TractorMarkerLightCmd 4;
BA_ "SigType" SG_ 2365473264 RearFogLightCmd 4;
BA_ "SigType" SG_ 2365473264 TractorUndersideWorkLightCmd 4;
BA_ "SigType" SG_ 2365473264 TractorRearLowWorkLightCmd 4;
BA_ "SigType" SG_ 2365473264 TractorRearHighWorkLightCmd 4;
BA_ "SigType" SG_ 2365473264 TractorSideLowWorkLightCmd 4;
BA_ "SigType" SG_ 2365473264 TractorSideHighWorkLightCmd 4;
BA_ "SigType" SG_ 2365473264 TractorFrontLowWorkLightCmd 4;
BA_ "SigType" SG_ 2365473264 TractorFrontHighWorkLightCmd 4;
BA_ "SigType" SG_ 2365473264 ImplementOEMOption2LightCmd 4;
BA_ "SigType" SG_ 2365473264 ImplementOEMOption1LightCmd 4;
BA_ "SigType" SG_ 2365473264 ImplementRightForwardLightCmd 4;
BA_ "SigType" SG_ 2365473264 ImplementLeftForwardLightCmd 4;
BA_ "SigType" SG_ 2365473264 LightingDataRequestCmd 4;
BA_ "SigType" SG_ 2365473264 ImplementRightFacingWorkLightCmd 4;
BA_ "SigType" SG_ 2365473264 ImplementLeftFacingWorkLightCmd 4;
BA_ "SigType" SG_ 2365473264 ImplementRearWorkLightCmd 4;
BA_ "SigType" SG_ 2365473534 FrontHitchPositionCmd 1;
BA_ "SigType" SG_ 2365473534 RearHitchPositionCmd 1;
BA_ "SigType" SG_ 2365473534 FrontPTOOutShaftSpeedSetPointCmd 1;
BA_ "SigType" SG_ 2365473534 RearPTOOutShaftSpeedSetPointCmd 1;
BA_ "SigType" SG_ 2365473534 RearPTOEngagementCmd 4;
BA_ "SigType" SG_ 2365473534 FrontPTOEngagementCmd 4;
BA_ "SigType" SG_ 2365473534 RearPTOEconomyModeCmd 4;
BA_ "SigType" SG_ 2365473534 FrontPTOEconomyModeCmd 4;
BA_ "SigType" SG_ 2365473534 RearPTOModeCmd 4;
BA_ "SigType" SG_ 2365473534 FrontPTOModeCmd 4;
BA_ "SigType" SG_ 2365473776 RearPTOShaftSpeedLimitStatus 4;
BA_ "SigType" SG_ 2365473776 RearPTOModeRqStatus 4;
BA_ "SigType" SG_ 2365473776 RearPTOEngagementRqStatus 4;
BA_ "SigType" SG_ 2365473776 RearPTOEconomyModeRqStatus 4;
BA_ "SigType" SG_ 2365473776 RearPTOOutputShaftSpeed 1;
BA_ "SigType" SG_ 2365473776 RearPTOOutputShaftSpeedSetPoint 1;
BA_ "SigType" SG_ 2365473776 RearPTOEconomyMode 4;
BA_ "SigType" SG_ 2365473776 RearPTOMode 4;
BA_ "SigType" SG_ 2365473776 RearPTOEngagement 4;
BA_ "SigType" SG_ 2365474032 FrontPTOShaftSpeedLimitStatus 4;
BA_ "SigType" SG_ 2365474032 FrontPTOModeRqStatus 4;
BA_ "SigType" SG_ 2365474032 FrontPTOEconomyModeRqStatus 4;
BA_ "SigType" SG_ 2365474032 FrontPTOEngagementRqStatus 4;
BA_ "SigType" SG_ 2365474032 FrontPTOOutShaftSpeed 1;
BA_ "SigType" SG_ 2365474032 FrontPTOOutShaftSpeedSetPoint 1;
BA_ "SigType" SG_ 2365474032 FrontPTOEconomyMode 4;
BA_ "SigType" SG_ 2365474032 FrontPTOMode 4;
BA_ "SigType" SG_ 2365474032 FrontPTOEngagement 4;
BA_ "SigType" SG_ 2365474288 RearHitchPositionLimitStatus 4;
BA_ "SigType" SG_ 2365474288 RearHitchPosition 1;
BA_ "SigType" SG_ 2365474288 RearHitchInWorkIndication 4;
BA_ "SigType" SG_ 2365474288 RearNominalPowerLinkForce 1;
BA_ "SigType" SG_ 2365474288 RearDraft 1;
BA_ "SigType" SG_ 2365474544 FrontHitchPositionLimitStatus 4;
BA_ "SigType" SG_ 2365474544 FrontHitchPosition 1;
BA_ "SigType" SG_ 2365474544 FrontHitchInWorkIndication 4;
BA_ "SigType" SG_ 2365474544 FrontNominalLowerLinkForce 1;
BA_ "SigType" SG_ 2365474544 FrontDraft 1;
BA_ "SigType" SG_ 2566801406 MaintainActuatorPower 4;
BA_ "SigType" SG_ 2566801406 MaintainECUPower 4;
BA_ "SigType" SG_ 2566801406 ImplementedWorkState 4;
BA_ "SigType" SG_ 2566801406 ImplementedParkState 4;
BA_ "SigType" SG_ 2566801406 ImplementTransportState 4;
BA_ "SigType" SG_ 2365475056 OperatorDirectionReversed 5;
BA_ "SigType" SG_ 2365475056 WheelBasedSpeed 1;
BA_ "SigType" SG_ 2365475056 WheelBasedDistance 1;
BA_ "SigType" SG_ 2365475056 MaxTimeOfTractorPower 1;
BA_ "SigType" SG_ 2365475056 WheelBasedDirection 4;
BA_ "SigType" SG_ 2365475056 KeySwitchState 4;
BA_ "SigType" SG_ 2365475056 StartStopState 4;
BA_ "SigType" SG_ 2365475312 GroundBasedImplementedSpeed 1;
BA_ "SigType" SG_ 2365475312 GroundBasedDistance 1;
BA_ "SigType" SG_ 2365475312 GroundBasedDirection 4;
BA_ "SigType" SG_ 2566842096 Seconds 1;
BA_ "SigType" SG_ 2566842096 Minutes 1;
BA_ "SigType" SG_ 2566842096 Hours 1;
BA_ "SigType" SG_ 2566842096 Month 1;
BA_ "GenSigStartValue" SG_ 2566842096 Day 1;
BA_ "SigType" SG_ 2566842096 Day 1;
BA_ "SigType" SG_ 2566842096 Year 1;
BA_ "SigType" SG_ 2566842096 LocalMinuteOffset 1;
BA_ "SigType" SG_ 2566842096 LocalHourOffset 1;
BA_ "SigType" SG_ 2583168284 SequenceID 1;
BA_ "SigType" SG_ 2583168284 PositionDate 1;
BA_ "SigType" SG_ 2583168284 PositionTime 1;
BA_ "SigType" SG_ 2583168284 TypeOfSystem 4;
BA_ "SigType" SG_ 2583168284 GNSSMethod 4;
BA_ "SigType" SG_ 2583168284 GNSSIntegrity 4;
BA_ "SigType" SG_ 2583168284 NumberOfSVs 1;
BA_ "SigType" SG_ 2583168284 NumberOfReferenceStations 1;
BA_ "SigType" SG_ 2583168284 RefrenceStationType1 4;
BA_ "SigType" SG_ 2583168284 ReferenceStationID1 1;
BA_ "SigType" SG_ 2583168284 AgeOfDGNSSCorrections1 1;
BA_ "SigType" SG_ 2563309310 ControlByte 1;
BA_ "GenSigStartValue" SG_ 2563309310 ERtsMsgSize 1786;
BA_ "SigType" SG_ 2563309310 ERtsMsgSize 1;
BA_ "GenSigStartValue" SG_ 2563309310 ECtsNoPackets 1;
BA_ "SigType" SG_ 2563309310 ECtsNoPackets 1;
BA_ "GenSigStartValue" SG_ 2563309310 EDpoNoPackets 1;
BA_ "SigType" SG_ 2563309310 EDpoNoPackets 1;
BA_ "GenSigStartValue" SG_ 2563309310 EAckMsgSize 1786;
BA_ "SigType" SG_ 2563309310 EAckMsgSize 1;
BA_ "GenSigStartValue" SG_ 2563309310 ECtsNextPacket 1;
BA_ "SigType" SG_ 2563309310 ECtsNextPacket 1;
BA_ "SigType" SG_ 2563309310 EDpoOffset 1;
BA_ "SigType" SG_ 2563309310 PGNumber 6;
BA_ "SigType" SG_ 2563243774 SeqNumber 1;
BA_ "SigType" SG_ 2563243774 Byte1 1;
BA_ "SigType" SG_ 2563243774 Byte2 1;
BA_ "SigType" SG_ 2563243774 Byte3 1;
BA_ "SigType" SG_ 2563243774 Byte4 1;
BA_ "SigType" SG_ 2563243774 Byte5 1;
BA_ "SigType" SG_ 2563243774 Byte6 1;
BA_ "SigType" SG_ 2563243774 Byte7 1;
BA_ "SPN" SG_ 2364540144 ActualEngPercentTorque 513;
BA_ "SigType" SG_ 2364540144 ActualEngPercentTorque 1;
BA_ "SPN" SG_ 2364540144 DriversDemandEngPercentTorque 512;
BA_ "SigType" SG_ 2364540144 DriversDemandEngPercentTorque 1;
BA_ "SPN" SG_ 2364540144 EngDemandPercentTorque 2432;
BA_ "SigType" SG_ 2364540144 EngDemandPercentTorque 1;
BA_ "SPN" SG_ 2364540144 EngSpeed 190;
BA_ "SigType" SG_ 2364540144 EngSpeed 1;
BA_ "SPN" SG_ 2364540144 EngStarterMode 1675;
BA_ "SigType" SG_ 2364540144 EngStarterMode 4;
BA_ "SPN" SG_ 2364540144 EngTorqueMode 899;
BA_ "SigType" SG_ 2364540144 EngTorqueMode 4;
BA_ "SPN" SG_ 2364540144 SrcAddrssOfCtrllngDvcForEngCtrl 1483;
BA_ "SigType" SG_ 2364540144 SrcAddrssOfCtrllngDvcForEngCtrl 1;
VAL_ 2632384038 AssignedAttribute2OfSet1 1 "InputIsAssigned" ;
VAL_ 2632384038 AssignedAttribute1OfSet1 0 "AuxiliaryInput" 1 "AuxiliaryFunction" ;
VAL_ 2632384038 StoreAsPreferredAssignment 0 "StoreAssignment" 1 "DoNotStoreAssignment" ;
VAL_ 2632384038 ErrorCodeChangeAttribute5 1 "GeneralError" 0 "NoErrors" ;
VAL_ 2632384038 IndustryGroup 7 "Reserved for SAE" 5 "IndustrialProcessCtrlStationary" 4 "Marine" 3 "Construction" 2 "Agricultural and Forestry" 1 "On-Highway" 0 "Global" ;
VAL_ 2632384038 FontType_ProportionalFont 1 "Supported" 0 "NotSupported" ;
VAL_ 2632384038 FontType_FlashHidden 1 "Supported" 0 "NotSupported" ;
VAL_ 2632384038 FontType_FlashInverted 1 "Supported" 0 "NotSupported" ;
VAL_ 2632384038 FontType_InvertedText 1 "Supported" 0 "NotSupported" ;
VAL_ 2632384038 ErrorCodeChangePolygonScale5 0 "NoError" 1 "GeneralError" ;
VAL_ 2632384038 FontType_ItalicsText 1 "Supported" 0 "NotSupported" ;
VAL_ 2632384038 FontType_UnderlinedText 1 "Supported" 0 "NotSupported" ;
VAL_ 2632384038 FontType_CrossedOutText 1 "Supported" 0 "NotSupported" ;
VAL_ 2632384038 OperatingState2 0 "InputNotActivatedInLearnMode" 1 "InputActivatedInLearnMode" ;
VAL_ 2632384038 FontType_BoldText 1 "Supported" 0 "NotSupported" ;
VAL_ 2632384038 ErrorCodeChangePolygonScale1 0 "NoError" 1 "InvalidObjectId" ;
VAL_ 2632384038 OperatingState1 0 "LearnModeInactive" 1 "LearnModeActive" ;
VAL_ 2632384038 VTBusyCode8 1 "VTIsOutOfMemory" ;
VAL_ 2632384038 FontSize_128x192 1 "Supported" 0 "NotSupported" ;
VAL_ 2632384038 VTBusyCode7 1 "AuxiliaryControlsLearnModeActive" ;
VAL_ 2632384038 FontSize_128x128 1 "Supported" 0 "NotSupported" ;
VAL_ 2632384038 VTBusyCode5 1 "VTIsBusyParsingAnObjectPool" ;
VAL_ 2632384038 FontSize_96x128 1 "Supported" 0 "NotSupported" ;
VAL_ 2632384038 ErrorCodeGetSupportedWideChars2 0 "NoError" 1 "GeneralError" ;
VAL_ 2632384038 ErrorCodeChangeListItem5 1 "ValueInUse" 0 "NoErrors" ;
VAL_ 2632384038 ErrorCodeChangeListItem4 1 "ValueInUse" 0 "NoErrors" ;
VAL_ 2632384038 VTBusyCode4 1 "VTIsBusyExecutingMacro" ;
VAL_ 2632384038 FontSize_64x96 1 "Supported" 0 "NotSupported" ;
VAL_ 2632384038 ErrorCodeObjectPool4 1 "ObjectPoolWasDeletedFromVolatile" 0 "NoErrors" ;
VAL_ 2632384038 VTBusyCode3 1 "VTIsBusyExecutingCommand" ;
VAL_ 2632384038 FontSize_64x64 1 "Supported" 0 "NotSupported" ;
VAL_ 2632384038 ErrorCodeChangeListItem3 1 "InvalidNewListItemObjectID" 0 "NoErrors" ;
VAL_ 2632384038 ErrorCodeObjectPool3 1 "GeneralError" 0 "NoErrors" ;
VAL_ 2632384038 VTBusyCode2 1 "VTIsBusySavingDataToNonVolMemory" ;
VAL_ 2632384038 FontSize_48x64 1 "Supported" 0 "NotSupported" ;
VAL_ 2632384038 ErrorCodeChangeListItem2 1 "InvalidListIndex" 0 "NoErrors" ;
VAL_ 2632384038 ErrorCodeObjectPool2 1 "UnknownObjectReference" 0 "NoErrors" ;
VAL_ 2632384038 VTBusyCode1 1 "VTIsBusyUpdatingVisibleMask" ;
VAL_ 2632384038 FontSize_32x48 1 "Supported" 0 "NotSupported" ;
VAL_ 2632384038 ErrorCodeGetSupportedWideChars1 0 "NoError" 1 "TooManyRanges" ;
VAL_ 2632384038 ErrorCodeChangeListItem1 1 "InvalidListObjectID" 0 "NoErrors" ;
VAL_ 2632384038 Function 43 "Transmission Display" 44 "Exhaust Emission Control" 45 "Vehicle Dynamic Stability Control" 46 "Oil Sensor Unit" 47 "Information System Controller" 48 "Ramp Control" 49 "Clutch/Converter Control" 50 "Auxiliary Heater" 51 "Forward-Looking Collision Warning System" 52 "Chassis Controller" 53 "Alternator/Charging System" 54 "Communications Unit, Cellular" 55 "Communications Unit, Satellite" 56 "Communications Unit, Radio" 57 "Steering Column Unit" 58 "Fan Drive Control" 59 "Starter" 60 "Cab Display" 61 "File Server/Printer" 62 "On-Board Diagnostic Unit" 63 "Engine Valve Controller" 64 "Endurance Braking" 65 "Gas Flow Measurement" 66 "I/O Controller" 67 "Electrical System Controller" 68 "Aftertreatment system gas measurement" 69 "Engine Emission Aftertreatement System" 70 "Auxiliary Regeneration Device" 71 "Transfer Case Control" 72 "Coolant Valve Controller" 73 "Rollover Detection Control" 74 "Lubrication System" 75 "Supplemental Fan" 76 "Temperature Sensor" 77 "Fuel Properties Sensor" 78 "Fire Suppression System" 79 "Power Systems Manager" 80 "Electric Powertrain" 81 "Hydraulic Powertrain" 82 "File Server" 83 "Printer" 84 "Start Aid Device" 85 "Engine Injection Control Module" 86 "Reserved" 87 "Reserved" 88 "Reserved" 89 "Reserved" 90 "Reserved" 91 "Reserved" 92 "Reserved" 93 "Reserved" 94 "Reserved" 95 "Reserved" 96 "Reserved" 97 "Reserved" 98 "Reserved" 99 "Reserved" 100 "Reserved" 0 "Engine" 1 "Auxiliary Power Unit (APU)" 2 "Electric Propulsion Control" 3 "Transmission" 4 "Battery Pack Monitor" 5 "Shift Control/Console" 6 "Power TakeOff - (Main or Rear)" 7 "Axle - Steering" 8 "Axle - Drive" 9 "Brakes - System Controller" 10 "Brakes - Steer Axle" 11 "Brakes - Drive Axle" 12 "Retarder - Engine" 13 "Retarder - Driveline" 14 "Cruise Control" 15 "Fuel System" 16 "Steering Controller" 17 "Suspension - Steer Axle" 18 "Suspension - Drive Axle" 19 "Instrument Cluster" 20 "Trip Recorder" 21 "Cab Climate Control" 22 "Aerodynamic Control" 23 "Vehicle Navigation" 24 "Vehicle Security" 25 "Network Interconnect ECU" 26 "Body Controller" 27 "Power TakeOff (Secondary or Front)" 28 "Off Vehicle Gateway" 29 "Virtual Terminal (in cab)" 30 "Management Computer" 31 "Propulsion Battery Charger" 32 "Headway Controller" 33 "System Monitor" 34 "Hydraulic Pump Controller" 35 "Suspension - System Controller" 36 "Pneumatic - System Controller" 37 "Cab Controller" 38 "Tire Pressure Control" 39 "Ignition Control Module" 40 "Seat Control" 41 "Lighting - Operator Controls" 42 "Water Pump Control" 101 "Reserved" 102 "Reserved" 103 "Reserved" 104 "Reserved" 105 "Reserved" 106 "Reserved" 107 "Reserved" 108 "Reserved" 109 "Reserved" 110 "Reserved" 111 "Reserved" 112 "Reserved" 113 "Reserved" 114 "Reserved" 115 "Reserved" 116 "Reserved" 117 "Reserved" 118 "Reserved" 119 "Reserved" 120 "Reserved" 121 "Reserved" 122 "Reserved" 123 "Reserved" 124 "Reserved" 125 "Reserved" 126 "Reserved" 127 "Reserved" 255 "Not Available" ;
VAL_ 2632384038 ErrorCodeObjectPool1 1 "MethodOrAttributeNotSupportedByV" 0 "NoErrors" ;
VAL_ 2632384038 SoftKeyCode 0 "AlarmACK" ;
VAL_ 2632384038 BooleanValue 0 "Disabled" 1 "Enabled" 2 "EnabledStillHeld" ;
VAL_ 2632384038 Status_2 0 "Hidden" 1 "Shown" ;
VAL_ 2632384038 ErrorCodeVTChangeSoftKeyMask6 1 "PoolBeingDeleted" 0 "NoError" ;
VAL_ 2632384038 FontSize_32x32 1 "Supported" 0 "NotSupported" ;
VAL_ 2632384038 FontSize_24x32 1 "Supported" 0 "NotSupported" ;
VAL_ 2632384038 FontSize_16x24 1 "Supported" 0 "NotSupported" ;
VAL_ 2632384038 ErrorCodeChangePosInvalidError 1 "GeneralError" 0 "NoErrors" ;
VAL_ 2632384038 ErrorCodeChangeSoftKeyMask5 1 "GeneralError" 0 "NoErrors" ;
VAL_ 2632384038 ErrorCodeChangeChildLocation5 1 "GeneralError" 0 "NoErrors" ;
VAL_ 2632384038 ErrorCodeVTChangeSoftKeyMask5 1 "GeneralError" 0 "NoError" ;
VAL_ 2632384038 ErrorCodeChangeStrValueInUse 1 "ValueInUse" 0 "NoErrors" ;
VAL_ 2632384038 ErrorCodeVtObjPoolError4 1 "OtherError" 0 "NoErrors" ;
VAL_ 2632384038 FontSize_16x16 1 "Supported" 0 "NotSupported" ;
VAL_ 2632384038 ErrorCodeChangeStrError 1 "GeneralError" 0 "NoErrors" ;
VAL_ 2632384038 ErrorCodeChangeSoftKeyMask4 1 "Mask or child object has errors" 0 "NoErrors" ;
VAL_ 2632384038 ErrorCodeVTChangeSoftKeyMask4 1 "MaskOrChildObjectHasErrors" 0 "NoError" ;
VAL_ 2632384038 ErrorCodeVtObjPoolError3 1 "RecursiveObjectReference" 0 "NoErrors" ;
VAL_ 2632384038 FontSize_12x16 1 "Supported" 0 "NotSupported" ;
VAL_ 2632384038 ErrorCodeChangeStrTooLong 1 "StringTooLong" 0 "NoErrors" ;
VAL_ 2632384038 ErrorCodeChangeSoftKeyMask3 1 "Missing Objects" 0 "NoErrors" ;
VAL_ 2632384038 ErrorCodeVTChangeSoftKeyMask3 1 "MissingObjects" 0 "NoError" ;
VAL_ 2632384038 ErrorCodeVtObjPoolError2 1 "UnknownObjectReference" 0 "NoErrors" ;
VAL_ 2632384038 FontSize_8x12 1 "Supported" 0 "NotSupported" ;
VAL_ 2632384038 ErrorCodeChangePosInvalidObject 1 "InvalidObjectID" 0 "NoErrors" ;
VAL_ 2632384038 ErrorCodeChangeStrObjectID 1 "InvalidObjectID" 0 "NoErrors" ;
VAL_ 2632384038 ErrorCodeChangeSoftKeyMask2 1 "InvalidSoftKeyMaskObjectID" 0 "NoErrors" ;
VAL_ 2632384038 ErrorCodeChangeChildLocation2 1 "InvalidObjectID" 0 "NoErrors" ;
VAL_ 2632384038 ErrorCodeVTChangeSoftKeyMask2 1 "InvalidSoftKeyMaskObjectID" 0 "NoError" ;
VAL_ 2632384038 ErrorCodeVtObjPoolError1 1 "UnsupportedMethodOrAttribute" 0 "NoErrors" ;
VAL_ 2632384038 AcknowledgmentDeleteVersion 8 "GeneralError" 4 "NA" 2 "VersionLabelIsNotCorrect" 0 "SuccessfullyDeleted" ;
VAL_ 2632384038 AcknowledgmentLoadVersion 8 "GeneralError" 4 "InsufficientMemoryAvailable" 2 "VersionLabelNotCorrectOrUnknown" 0 "SuccessfullyLoaded" ;
VAL_ 2632384038 AcknowledgmentStoreVersion 8 "GeneralError" 4 "InsufficientMemoryAvailable" 2 "VersionLabelIsNotCorrect" 0 "SuccessfullyStored" ;
VAL_ 2632384038 FontSize_8x8 1 "Supported" 0 "NotSupported" ;
VAL_ 2632384038 ErrorCodeChangePosInvalidParent 1 "InvalidParentObjectID" 0 "NoErrors" ;
VAL_ 2632384038 ErrorCodeChangeSoftKeyMask1 1 "InvalidDataOrAlarmMaskObjectID" 0 "NoErrors" ;
VAL_ 2632384038 ErrorCodeChangeChildLocation1 1 "InvalidParentObjectID" 0 "NoErrors" ;
VAL_ 2632384038 TouchState 0 "Released" 1 "Pressed" 2 "Held" 255 "Pressed" ;
VAL_ 2632384038 ErrorCodeVTChangeSoftKeyMask1 1 "InvalidDataOrAlarmMaskObjectID" 0 "NoError" ;
VAL_ 2632384038 ErrorCodeSelectObject6 1 "InvalidOptionValue" 0 "NoErrors" ;
VAL_ 2632384038 ErrorCodeGraphicsContextCmd5 0 "NoError" 1 "GeneralError" ;
VAL_ 2632384038 ErrorCodeChangePriority3 1 "GeneralError" 0 "NoErrors" ;
VAL_ 2632384038 ErrorCodeChangeAttribute4 1 "ValueInUse" 0 "NoErrors" ;
VAL_ 2632384038 ErrorCodeChangeColour3 1 "GeneralError" 0 "NoErrors" ;
VAL_ 2632384038 ErrorCodeSelectObject5 1 "GeneralError" 0 "NoErrors" ;
VAL_ 2632384038 ErrorCodeEnableDisableObj4 1 "GeneralError" 0 "NoErrors" ;
VAL_ 2632384038 ErrorCodeGraphicsContextCmd4 0 "NoError" 1 "CommandWillProduceInvalidResults" ;
VAL_ 2632384038 ErrorCodeSelectObject4 1 "CouldNotComplete" 0 "NoErrors" ;
VAL_ 2632384038 ErrorCodeEnableDisableObj3 0 "NoErrors" 1 "Could not complete. Operator inp" ;
VAL_ 2632384038 ErrorCodeHideShowObj3 1 "GeneralError" 0 "NoErrors" ;
VAL_ 2632384038 ErrorCodeGraphicsContextCmd3 0 "NoError" 1 "InvalidParameter" ;
VAL_ 2632384038 ErrorCodeChangeAttribute3 1 "InvalidValue" 0 "NoErrors" ;
VAL_ 2632384038 ErrorCodeSelectObject3 1 "ObjectIsNotVisible" 0 "NoErrors" ;
VAL_ 2632384038 ErrorCodeEnableDisableObj2 1 "CommandError" 0 "NoErrors" ;
VAL_ 2632384038 ErrorCodeGraphicsContextCmd2 0 "NoError" 1 "InvalidCommandID" ;
VAL_ 2632384038 ErrorCodeChangePriority2 1 "InvalidPriority" 0 "NoErrors" ;
VAL_ 2632384038 ErrorCodeChangeAttribute2 1 "InvalidAttributeID" 0 "NoErrors" ;
VAL_ 2632384038 ErrorCodeChangeColour2 1 "InvalidColourCode" 0 "NoErrors" ;
VAL_ 2632384038 ErrorCodeSelectObject2 1 "InvalidObjectID" 0 "NoErrors" ;
VAL_ 2632384038 ErrorCodeEnableDisableObj1 1 "InvalidObjectID" 0 "NoErrors" ;
VAL_ 2632384038 ErrorCodeHideShowObj2 1 "InvalidObjectID" 0 "NoErrors" ;
VAL_ 2632384038 ErrorCodeGraphicsContextCmd1 0 "NoError" 1 "InvalidObjectID" ;
VAL_ 2632384038 ErrorCodeChangePriority1 1 "InvalidObjectID" 0 "NoErrors" ;
VAL_ 2632384038 ErrorCodeChangeAttribute1 1 "InvalidObjectID" 0 "NoErrors" ;
VAL_ 2632384038 ErrorCodeChangeColour1 1 "InvalidObjectID" 0 "NoErrors" ;
VAL_ 2632384038 ErrorCodeSelectObject1 0 "NoErrors" 1 "ObjectIsDisabled" ;
VAL_ 2632384038 ErrorCodeHideShowObj1 1 "ReferencesToMissingObjects" 0 "NoErrors" ;
VAL_ 2632384038 VTSelectInputObjectIsEdited 1 "ObjectIsOpenForEditing" 0 "ObjectIsNotEdited" ;
VAL_ 2632384038 ButtonObjectParentID 2 "KeyIsStillPressed" 1 "KeyHasBeenPressed" 0 "KeyHasBeenReleased" ;
VAL_ 2632384038 KeyObjectParentID 2 "KeyIsStillPressed" 1 "KeyHasBeenPressed" 0 "KeyHasBeenReleased" ;
VAL_ 2632384038 Hardware6 1 "VT supports intermediate coordinates during a drag operation" 0 "VT does not support intermediate coordinates during a drag operation" ;
VAL_ 2632384038 ErrorCodeChangeFont6 1 "GeneralError" 0 "NoErrors" ;
VAL_ 2632384038 ManufacturerCode 234 "Mondial electronic GmbH" 235 "SailorMade Marine Telemetry - Tetra Technology Ltd." 236 "Norac Systems International Inc" 237 "Agtron Enterprises Inc" 238 "ZF Friedrichshafen AG" 239 "May & Scofield Ltd" 240 "Vanair Mfg" 241 "Schneider Automation SAS " 242 "Kokusandenki Co. Ltd" 243 "eRide, Inc." 244 "Techno-Matic" 245 "Capstan Ag Systems, Inc." 246 "Class 1, Inc" 247 "ePULSE" 248 "Cooper Standard Automotive Active Systems Group" 264 "Autolync" 265 "MTS Sensor Technologie GmbH" 266 "International Thermal Research Ltd" 267 "Red Lion Controls, Inc" 268 "Accurate Technologies" 269 "Saft America Inc.,  Space & Defense Division" 270 "Tennant" 271 "Cole Hersee" 312 "Lectronix, Inc." 313 "Ilmor Engineering, Inc" 314 "CSM GmbH" 315 "Icom Incorporated" 316 "ITT Flow Control" 317 "Navtronics Bvba" 318 "SAT Plan" 319 "Cadec Global" 320 "Miedema Landbouwwerktuigenfabriek B.V." 321 "Ultra Electronics, Electrics" 322 "MICHENKA s.r.o." 323 "Mobileye Vision Technologies Ltd." 324 "Snap-on Diagnostics" 325 "ASM Automation Sensorik Messtechnik GmbH" 326 "Akron Brass Company" 327 "Sonceboz SA" 272 "Gross Mechanical Laboratories, Inc" 273 "Active Research Limited" 274 "LTW Technology Co., LTD" 275 "Navico Egersund AS" 276 "Aqua-Hot Heating Systems" 277 "LHP Telematics" 278 "Takata Electronics" 279 "Geometris LP" 280 "Leica Geosystems Pty Ltd" 299 "Rauch Landmaschinen GmbH" 300 "Systron Donner Automotive" 301 "Parker Hannifin (UK) Ltd FDE group" 302 "Nissin Kogyo Co., LTD" 303 "CTS Corporation" 304 "EmpirBus AB" 305 "NovAtel Inc" 306 "Sleipner Motor AB" 307 "MBW Technologies" 308 "Cyntrx" 309 "Krauss-Maffei Wegmann GmbH & Co. KG" 310 "TECNORD srl" 311 "Patrick Power Products" 281 "Precision Governors LLC" 282 "Medallion Instrumentation Systems" 283 "CWF Hamilton & Co Ltd" 284 "Mobile Tech Chile" 285 "Sea Recovery Corp" 286 "Coelmo srl" 287 "NTech Industries, Inc" 288 "Mitsubishi FUSO Truck & Bus Corp." 289 "Watlow" 290 "Kuebler GmbH" 291 "Groeneveld Transport Efficiency BV" 292 "IKUSI - Angel Iglesias S.A." 293 "Spyder Controls Corp." 294 "Grayhill Inc." 295 "BEP Marine" 296 "micro dynamics GmbH" 297 "Zonar Systems Inc" 298 "Holley Performance" 253 "Mobile Control Systems" 254 "GE Sensing" 255 "MEAS France" 256 "Tyco Electronics AMP" 257 "Honda Motor Co., Ltd" 258 "ARAG" 259 "Jetter AG" 260 "Reichhardt GmbH" 261 "Red Dot Corporation" 262 "HydraForce, Inc" 263 "IMMI" 223 "Vaueo Retarder Co., Ltd." 224 "EMMI Network, S.L." 225 "SKF" 226 "Monaco Coach Corporation" 227 "Lykketronic A/S" 228 "ZF Marine Electronics" 229 "Garmin International Inc." 230 "Saucon Technologies" 231 "Topcon Positioning Systems, Inc." 0 "Reserved" 1 "Allied Signal Inc." 2 "Allison Transmission, GMC" 3 "Ametek, US Gauge Division" 4 "Ametek-Dixson" 5 "AMP Inc." 6 "Berifors Electronics AB" 7 "Case Corp." 8 "Caterpillar Inc." 9 "Chrysler Corp." 10 "Cummins Engine Co." 11 "Dearborn Group Inc." 12 "Deere & Company, Precision Farming" 13 "Delco Electronics" 14 "Detroit Diesel Corporation" 15 "Dickey-John Corp." 16 "Eaton Corp." 17 "Eaton Corp. Res & Dev" 18 "Eaton Corp, Transmission Division" 19 "Eaton Corp. Trucking Info Services" 20 "Eaton Ltd" 21 "Echilin Inc., Midland Brake Inc." 22 "Ford Motor Co., Electronic Concepts $ Systems" 23 "Ford Motor Co., Heavy Truck" 24 "Ford Motor Co., Vehicle Controls" 25 "Daimler Trucks North America LLC" 26 "General Motors Corp., Service Technology Group" 27 "GMC" 28 "Grote Ind. Inc." 29 "Hino Motors Ltd." 30 "Isuzu Motors Ltd." 31 "J Pollak Corp." 32 "Jacobs Vehicle Systems" 33 "John Deere" 34 "Kelsey Hayes Co." 35 "Kenworth Truck Co." 36 "Lucas Ltd." 37 "Mack Trucks Inc." 38 "Micro Processor Systems Inc." 39 "Microfirm Inc." 40 "Motorola AIEG Inc." 41 "Motorola Inc." 42 "International Truck and Engine Corp. Engine Electronics" 43 "International Truck and Engine Corp. Vehicle Electronics" 44 "Nippondenso Co. Ltd." 45 "PACCAR" 46 "Noregon Systems, Inc" 47 "Phillips Semiconductor" 48 "Pollak Alphabet" 49 "RE America Inc." 50 "Robert Bosch Corp" 51 "Robert Bosch GmbH" 52 "Meritor Automotive, Inc." 53 "Continental Automotive Systems US, Inc." 54 "Meritor Wabco" 55 "Ryder System Inc." 56 "SAIC" 57 "Sauer-Danfoss Co." 58 "SPX Corporation, OTC Division" 59 "VES Inc." 60 "Volvo Trucks North America Inc." 61 "Volvo Truck Corp." 62 "Wabco" 63 "ZF Industries Inc." 64 "unused" 65 "MAN Nutzfahrzeuge AG" 66 "John Deere Construction Equipment Division" 67 "Funk Manufacturing Company" 68 "Scania" 69 "Trimble Navigation" 70 "Flex-Coil Limited" 71 "Vansco Electronics Ltd." 72 "Sisu Corporation" 73 "LeTourneau, Inc." 74 "Eaton Axle-Brake Division" 75 "Deere & Co. Agricultural Division" 76 "unused" 77 "Deere Power Systems Group" 78 "Frank W. Murphy Manufacturing, Inc." 79 "Daimler Benz AG - Engine Division (PBM)" 80 "Twin Disc, Inc." 81 "Fire Research Corp" 82 "Bobcat/Ingersoll-Rand" 83 "Bendix VORAD Technologies" 84 "New Holland UK Limited" 85 "Kohler Co." 86 "C.E. Niehoff & Company" 87 "J.C. Bamford Excavators Ltd (JCB)" 88 "Satloc Precision GPS" 89 "Kverneland Group, Electronics Division" 90 "Knorr-Bremse SfN GmbH" 91 "BSG Bodensee Steuergeraete GmbH" 92 "Ag-Chem Equipment Co., Inc." 93 "Perkins Engines Company Ltd." 94 "CNH Global N.V." 95 "Pacific Insight Electronics Corp." 96 "Mech@tronic IT GmbH" 97 "Ag Leader Technology, Inc." 98 "Mueller-Elektronik GmbH & Co." 99 "International Transmissions Ltd (ITL)" 100 "VDO Technik AG" 101 "Sensoria" 102 "AGCO GmbH & Co." 103 "CLAAS Agrosystems GmbH & Co. KG" 104 "Claas Selbstfahrende Erntemaschinen GmbH" 105 "Kiepe Elektrik GmbH & Co. KG" 106 "BAE Systems Controls, Inc." 107 "Grimme Landmaschinen GmbH & Co. KG" 108 "WTK-Elecktronik GmbH" 109 "TeeJet Technologies Denmark" 110 "EPIQ Sensor-Nite" 111 "Maschinenfabrik Bernard Krone GmbH" 112 "MECALAC" 113 "Stress-Tek, Inc." 114 "EControls, Inc." 115 "NACCO Materials Handling Group, Inc." 116 "BEELINE Technologies" 117 "HUSCO International" 118 "Intron GmbH" 119 "IntegriNautics" 120 "RDS Technology Ltd." 121 "HED (Hydro Electronic Devices, Inc.)" 122 "FG Wilson (Engineering) Limited" 123 "Basler Electric" 124 "Hydac Electronic" 125 "Nevada Automotive Test Center" 126 "Driver Tech" 127 "Holland USA" 128 "Gerhard Duecker GmbH & Co. KG" 129 "OMNEX Control Systems, Inc." 130 "Nido - Universal Machines B.V." 131 "ITT Industries" 132 "Mulag-Fahrzeugwerk" 133 "Bucher Schoerling GmbH" 134 "Iris Technology Ltd." 135 "Airmar Technology Corporation" 136 "Komatsu Ltd." 137 "Maretron" 138 "Georg Fritzmeier GmbH & Co. KG" 139 "Caterpillar Trimble Control Technologies (CTCT), LLC" 140 "Lowrance Electronics, Inc." 141 "Thales Navigation Ltd." 142 "TRW Automotive (Commercial Steering Systems)" 143 "W. Gmeiner GmbH & Co." 144 "Mercury Marine" 145 "MurCal Controls" 146 "Maxima Technologies" 147 "Nautibus Electronic GmbH" 148 "Blue Water Data, Inc." 149 "Holset" 150 "Fleetguard" 151 "Raven Industries Inc. - Flow Controls Division" 152 "elobau GmbH & Co. KG" 153 "Woodward, Industrial Controls Division" 154 "Westerbeke Corporation" 155 "Vetronix Corporation" 156 "ITT Industries - Cannon" 157 "ISSPRO Inc." 158 "Firestone Industrial Products Company" 159 "NTech Industries Inc." 160 "Nido" 161 "Offshore Systems (UK) Limited" 162 "Axiomatic Technologies" 163 "BRP Inc." 164 "DaimlerChrysler Off-Highway" 165 "CPAC Systems AB" 166 "Phoenix International" 167 "JLG Industries Inc." 168 "Xantrex" 169 "Marlin Technologies Inc." 170 "Computronics Corporation Ltd." 171 "Wachendorff Elektronik GmbH & Co. KG" 172 "Yanmar Marine USA" 173 "Ryeso, Inc." 174 "AB Volvo Penta" 175 "Veris Technologies, Inc." 176 "Moritz Aerospace" 177 "Diagnostic System Associates" 178 "Siemens VDO Automotive AG" 179 "TeeJet Technologies Denmark" 180 "Smart Power Systems" 181 "Coretronics, Inc." 182 "Vehicle Systems Engineering B.V." 183 "KDS Controls, Inc." 184 "EIA Electronics" 185 "Beede Electrical Instrument Company" 186 "Altronic, Inc." 187 "Air-Weigh" 188 "EMP Corp." 189 "QUALCOMM" 190 "Hella KGaA Hueck & Co." 191 "XRS Corporation" 192 "Floscan" 193 "Nobletec" 194 "TriMark Corporation" 195 "General Engine Products" 196 "LEMKEN GmbH & Co. KG" 197 "Mechron Power Systems" 198 "Mystic Valley Communications" 199 "Actia Corp." 200 "MGM Brakes" 201 "Disenos y Tecnologia S.A." 202 "Curtis Instruments, Inc." 203 "MILtronik GmbH" 204 "The Morey Corporation" 205 "SmarTire Systems Inc" 206 "port GmbH" 207 "Otto Engineering" 208 "Drew Technologies, Inc." 209 "Bell Equip. Co. SA (PTY) LTD" 210 "Iteris, Inc." 211 "DNA Group" 212 "Sure Power Industries, Inc." 213 "CNH Belgium N.V." 214 "MC elettronica Srl" 215 "Aetna Engineering/Fireboy-Xintex" 216 "Paneltronics Inc." 217 "RM Michaelides Software & Elektronik GmbH" 218 "Gits Manufacturing Company" 219 "Cat OEM Solutions" 220 "Beede Electrical Instrument Company, Inc." 221 "SiE" 222 "Generac Power Systems, Inc." 1850 "Teleflex" 1851 "Raymarine" 1852 "Navionics" 1853 "Japan Radio Co." 1854 "Northstar Technologies" 1855 "Furuno USA" 1856 "Trimble" 1857 "Simrad" 1858 "Litton" 1859 "Kvasar AB" 1860 "MMP" 1861 "Vector North America" 1862 "Sanshin" 1863 "Thomas G. Faria Co." 232 "TSD Integrated Controls" 233 "Yacht Monitoring Solutions Inc." 249 "Schaltbau GmbH" 250 "Kuhn Group" 251 "German Agricultural Society" 252 "Sensor-Technik Wiedemann GmbH" 328 "Qwerty Electronik AB" 329 "Deif A/S" 330 "Kidde Aerospace and Defense" 331 "Horton, Inc." 332 "HWH Corporation" 333 "Hadley Products Corporation" 334 "Takata-Petri AG" 335 "Evo Electric Ltd" 336 "APE s.r.o." 337 "Carraro S.p.A." 338 "GRAF-SYTECO" 339 "Competence Center ISOBUS e.V." 340 "Continental AG" 341 "Boning GmbH & Co" 342 "THOMAS MAGNETE GmbH" 343 "Baumer Group" 344 "Parvus Corporation" 345 "Korean Maritime University" 346 "Control Solutions" 347 "Honeywell" 348 "Amazonen Werke H. Dreyer" 349 "Suonentiet" 350 "Noris Marine Systems GmbH & Co KG" 351 "Thrane & Thrane" 352 "SAME DEUTZ-FAHR" 353 "Hegemon Electronics, Inc." 354 "Junkkari OY" 355 "Mastervolt International B.V." 356 "Fischer Panda Generators, Inc" 357 "Hardi International A/S" 358 "Victron Energy BV" 359 "Ludwig Bergmann GmbH" 360 "HJS Emission Technology GmbH & Co KG" 361 "InMach" 362 "Alois Poettinger Maschinenfabrik GmbH" 363 "BEI Duncan" 364 "OEM Controls Inc." 365 "Digi-Star, LLC" 366 "Viewnyx Corp." 367 "Fliegl Agrartechnik" 368 "HANSENHOF_electronic" 369 "Power Torque Engineering Ltd" 370 "Rolls-Royce Marine AS" 371 "Heinzmann GmbH & Co. KG" 373 "Electronic Design Inc." 374 "Northern Lights, Inc." 381 "B&G" 372 "Delphi" 375 "Williams Controls Inc." 376 "Quake Global" 377 "ifm electronic gmbh" 378 "Glendinning Marine Products" 379 "Yamabiko Corporation" 380 "Suntech International Ltd." 382 "National Agricultural and Food Research Organization" 383 "MCL Industries" 384 "Camano Light" 385 "Johnson Outdoor Marine Electronics" 386 "JLG Automation BVBA" 387 "Orscheln Products, LLC" 388 "Innomatix, LLC" 389 "Benchmark Electronics, Minnesota Division" 390 "Partech Inc." 391 "Electronic Design for Industry, Inc" 392 "Tianyuan Technology Co Ltd." 393 "Harvest Tec, Inc" 394 "Capi 2 Nederland BV" 395 "GENTEC S.R.L." 396 "Beyond Measure" 397 "Sanyo-kiki Co Ltd." 398 "Hilite International" 399 "ISEKI & Co., Ltd." 400 "Livorsi Marine" 401 "Torqeedo GmbH" 402 "Simma Software, Inc." 403 "Trackwell ADS, Inc." 404 "Com Nav Marine Ltd" 405 "Wema System AS" 406 "Vecima Networks Inc." 407 "Comtech Mobile Datacom" 408 "Corvus Energy Ltd." 409 "Transfluid S.r.L." 410 "COBO S.p.A. Divisione 3B6" 411 "Hy-Drive Technologies Ltd." 412 "WebTech Wireless Inc." 413 "Datapross Nijbroek bv" 414 "Cattron Group International" 415 "Valid Manufacturing Ltd." 416 "Kubota Corporation" 417 "KZValve" 418 "Intellistick Inc" 419 "Fusion Electronics Ltd" 420 "Vermeer Corporation, ACS Group" 421 "Vertex Standard Co., Ltd" 422 "True Heading AB" 423 "BSM Wireless, Inc." 424 "Odyne LLC" 425 "Methode Electronics Inc, MDI" 426 "Egersund Marine Electronics AS" 427 "em-trak Marine Electronics Ltd" 428 "Mfg_428" 429 "Rota Engineering Ltd." 455 "ADZ NAGANO GmbH" 456 "General Kinetics" 457 "RUSELPROM-ElectricDrive Ltd" 458 "Control Solutions, Inc." 459 "Alltek Marine Electronics Corp" 460 "San Giorgio S.E.I.N." 461 "HAWE Hydraulik SE" 462 "IHI Shibaura Machinery Corporation" 463 "PROBOTIQ" 464 "Leach International Corporation" 465 "Ashcroft Inc" 466 "Veethree Electronics and Marine LLC" 467 "Lely Industries N.V." 468 "Tyco Fire Protection Products" 469 "RA Consulting GmbH" 470 "SI-TEX Marine Electronics" 471 "Sea Cross Marine AB" 472 "Tenneco Inc." 473 "Boss Industries, Inc." 474 "Persen Technologies Inc." 475 "GME" 476 "Hummingbird Marine Electronics" 477 "OilQuick AB" 478 "OceanSat BV" 479 "Vapor Bus International" 430 "Auteq Telematica S.A." 431 "Tohatsu Corporation" 432 "S&A Systems, Inc." 433 "Rowe Electronics" 434 "Stored Energy Systems" 435 "Zunhammer GmbH" 436 "Kinze Manufacturing" 437 "Digital Yacht Limited" 438 "Comar Systems Ltd" 439 "Hyundai Heavy Industries" 440 "Cummins Power Generation" 441 "PTG Reifendruckregelsysteme GmbH" 442 "Horsch Maschinen GmbH" 443 "SignalQuest, Inc." 444 "ITT Power Solutions" 445 "KAT MECHATRONIC, Electronic Product Division" 446 "CertTech, L.L.C." 447 "Great Plains Mfg." 448 "Stanadyne Corporation, Electronics Systems" 449 "Polaris Industries Inc" 450 "Dycor Technologies Ltd." 451 "Parker Hannifin Corp" 452 "WIKA Alexander Wiegand SE & Co. KG" 453 "Cooper Bussmann" 454 "NGK Spark Plug Co. Ltd" 480 "EnerDel, Inc." 481 "Chetco Digital Instruments" 482 "Tricon Electronics" 483 "Valeo" 484 "Headsight Inc." 485 "MATT automotive" 486 "Westport Innovations Inc." 487 "DSE Test Solutions A/S" 488 "The Charles Machine Works, Inc." 489 "Appareo Systems" 490 "QuikQ" 491 "Penny and Giles Ltd" 492 "Inergy Automotive Systems" 493 "Watcheye" 494 "Synerject" 495 "HOLMER Maschinenbau GmbH" 496 "W. Gessmann GmbH" 497 "SENTRON Sistemas Embarcados" 498 "Innovative Design Solutions, Inc." 499 "LCJ Capteurs" 500 "Oxbo International Corporation" 501 "Agrotronix S.A." 502 "Attwood Corporation" 503 "Naviop S.R.L." 504 "Vesper Marine" 505 "Yetter Farm Equipment" 506 "IHI STAR Machinery Corporation" 507 "Test Center ISOBUS" 508 "Transtech Innovations" 509 "MOTORTECH GmbH" 510 "Marinesoft Co. Ltd" 511 "Sulky" 512 "Inpower LLC" 513 "FarmscanAg" 514 "DISTek Integration, Inc." 515 "GINAF Trucks Nederland B.V." 516 "AVAT Automation GmbH" 517 "Noland Engineering" 518 "Transas USA Inc." 519 "Peeters Landbouwmachines b.v." 520 "Trapeze" ;
VAL_ 2632384038 ErrorCodePoolDeleted 1 "PoolBeingDeleted" 0 "NoErrors" ;
VAL_ 2632384038 Hardware5 1 "VT supports simultaneous activations of softkeys" 0 "VT does not support simultaneous activations of softkeys" ;
VAL_ 2632384038 ErrorCodeChangeActiveMask5 1 "GeneralError" 0 "NoErrors" ;
VAL_ 2632384038 ErrorCodeChangeFillAttributes5 1 "GeneralError" 0 "NoErrors" ;
VAL_ 2632384038 ErrorCodeChangeLineAttribute4 1 "GeneralError" 0 "NoErrors" ;
VAL_ 2632384038 ErrorCodeChangeFont5 1 "InvalidStyle" 0 "NoErrors" ;
VAL_ 2632384038 ErrorCodeChangeEditPoint3 1 "GeneralError" 0 "NoErrors" ;
VAL_ 2632384038 ErrorCodeObjToSize4 1 "GeneralError" 0 "NoErrors" ;
VAL_ 2632384038 ErrorCodeEscapeObj2 1 "GeneralError" 0 "NoErrors" ;
VAL_ 2632384038 ErrorCodeAnyOtherError 1 "GeneralError" 0 "NoErrors" ;
VAL_ 2632384038 ErrorCodeVTEsc2 1 "GeneralError" 0 "NoError" ;
VAL_ 2632384038 ErrorCodeChangeNumValue4 1 "ValueInUse" 0 "NoErrors" ;
VAL_ 2632384038 Hardware4 1 "VT has adjustable volume audio output" 0 "VT has no adjustable volume audio output" ;
VAL_ 2632384038 ErrorCodeChangeActiveMask4 1 "MaskOrChildObjectHasErrors" 0 "NoErrors" ;
VAL_ 2632384038 ErrorCodeChangeFillAttributes4 1 "InvalidPatternObjectID" 0 "NoErrors" ;
VAL_ 2632384038 ErrorCodeChangeFont4 1 "InvalidType" 0 "NoErrors" ;
VAL_ 2632384038 ErrorCodeMaskOrChildObjectError 1 "MaskOrChildObjectHasErrors" 0 "NoErrors" ;
VAL_ 2632384038 ErrorCodeChangeNumValue3 1 "ValueInUse" 0 "NoErrors" ;
VAL_ 2632384038 Hardware3 1 "VT has multiple frequency audio output" 0 "VT has no multiple frequency audio output" ;
VAL_ 2632384038 ErrorCodeChangePoygonPoint3 0 "NoError" 1 "GeneralError" ;
VAL_ 2632384038 ErrorCodeChangeActiveMask3 1 "MissingObjects" 0 "NoErrors" ;
VAL_ 2632384038 ErrorCodeChangeFillAttributes3 1 "InvalidColour" 0 "NoErrors" ;
VAL_ 2632384038 ErrorCodeChangeLineAttribute3 1 "InvalidWidth" 0 "NoErrors" ;
VAL_ 2632384038 ErrorCodeChangeFont3 1 "InvalidSize" 0 "NoErrors" ;
VAL_ 2632384038 ErrorCodeObjToSize3 1 "InvalidHeight" 0 "NoErrors" ;
VAL_ 2632384038 ErrorCodeMissingObjects 1 "MissingObjects" 0 "NoErrors" ;
VAL_ 2632384038 ErrorCodeExecuteExtendedMacro3 0 "NoError" 1 "GeneralError" ;
VAL_ 2632384038 Hardware2 1 "VT reports drag operation" 0 "VT does not report drag operation" ;
VAL_ 2632384038 ErrorCodeSelectColourMap2 0 "NoError" 1 "GeneralError" ;
VAL_ 2632384038 ErrorCodeChangePoygonPoint2 0 "NoError" 1 "InvalidPointIndex" ;
VAL_ 2632384038 ErrorCodeChangeActiveMask2 1 "InvalidMaskObjectID" 0 "NoErrors" ;
VAL_ 2632384038 ErrorCodeChangeFillAttributes2 1 "InvalidType" 0 "NoErrors" ;
VAL_ 2632384038 ErrorCodeChangeLineAttribute2 1 "InvalidObjectColour" 0 "NoErrors" ;
VAL_ 2632384038 ErrorCodeChangeFont2 1 "InvalidColour" 0 "NoErrors" ;
VAL_ 2632384038 ErrorCodeChangeEditPoint2 1 "InvalidLineDirection" 0 "NoErrors" ;
VAL_ 2632384038 ErrorCodeChangeNumValue2 1 "InvalidValue" 0 "NoErrors" ;
VAL_ 2632384038 ErrorCodeObjToSize2 1 "InvalidWidth" 0 "NoErrors" ;
VAL_ 2632384038 ErrorCodeExecuteExtendedMacro2 0 "NoError" 1 "ObjectIdIsNoMacro" ;
VAL_ 2632384038 Hardware1 1 "VT has a touch screen or pointing device" 0 "VT has no touch screen and no pointing device" ;
VAL_ 2632384038 ErrorCodeSelectColourMap1 0 "NoError" 1 "InvalidObjectID" ;
VAL_ 2632384038 SubCommandID 0 "SetGraphicsCursor" 1 "MoveGraphicsCursor" 2 "SetForegroundColour" 3 "SetBackgroundColour" 4 "SetLineAttributesObjectID" 5 "SetFillAttributesObjectID" 6 "SetFontAttributesID" 7 "EraseRectangle" 8 "DrawPoint" 9 "DrawLine" 10 "DrawRectangle" 11 "DrawClosedEllipse" 12 "DrawPolygon" 13 "DrawText" 14 "PanViewport" 15 "ZoomViewport" 16 "PanAndZoomViewport" 17 "ChangeViewportSize" 18 "DrawVTObject" 19 "CopyCanvasToPictureGraphic" 20 "CopyViewportToPictureGraphic" ;
VAL_ 2632384038 ErrorCodeChangePoygonPoint1 0 "NoError" 1 "InvalidObjectId" ;
VAL_ 2632384038 ErrorCodeChangeActiveMask1 1 "InvalidWorkingSetObject" 0 "NoErrors" ;
VAL_ 2632384038 ErrorCodeChangeFillAttributes1 1 "InvalidObjectID" 0 "NoErrors" ;
VAL_ 2632384038 ErrorCodeChangeLineAttribute1 1 "InvalidObjectID" 0 "NoErrors" ;
VAL_ 2632384038 ErrorCodeChangeFont1 1 "InvalidObjectID" 0 "NoErrors" ;
VAL_ 2632384038 ErrorCodeChangeEditPoint1 1 "InvalidObjectID" 0 "NoErrors" ;
VAL_ 2632384038 ErrorCodeChangeNumValue1 1 "InvalidObjectID" 0 "NoErrors" ;
VAL_ 2632384038 ErrorCodeObjToSize1 1 "InvalidObjectID" 0 "NoErrors" ;
VAL_ 2632384038 ObjectSelectStatus 1 "ObjectIsSelected" 0 "ObjectIsDeselectedOrObjectIDIsNullObject" 2 "ObjectIsOpenedForEdit" ;
VAL_ 2632384038 ObjectEnableStatus 1 "ObjectIsEnabled" 0 "ObjectIsDisabled" ;
VAL_ 2632384038 ObjectShowStatus 1 "ObjectIsShown" 0 "ObjectIsHidden" ;
VAL_ 2632384038 ErrorCodeEscapeObj1 1 "NoInputFieldIsOpenForInput" 0 "NoErrors" ;
VAL_ 2632384038 ErrorCodeVTEsc1 1 "NoInputFieldSelected ESC_Ignored" 0 "NoError" ;
VAL_ 2632384038 VTSelectInputObjectStatus 1 "ObjectIsSelected" 0 "ObjectIsDeselected" ;
VAL_ 2632384038 Status_1 0 "Hidden" 1 "Shown" ;
VAL_ 2632384038 ErrorCodeExecuteExtendedMacro1 0 "NoError" 1 "ObjectIdNotExist" ;
VAL_ 2632384038 ErrorCodeLockUnlockMask8 0 "NoError" 1 "GeneralError" ;
VAL_ 2632384038 ErrorCodeLockUnlockMask7 0 "NoError" 1 "UnsolicitedUnlock_OperatorInduce" ;
VAL_ 2632384038 ErrorCodeLockUnlockMask6 0 "NoError" 1 "UnsolicitedUnlock_MaskChanged" ;
VAL_ 2632384038 ErrorCodeLockUnlockMask5 0 "NoError" 1 "UnsolicitedUnlock_TimeoutOccured" ;
VAL_ 2632384038 ErrorCodeLockUnlockMask4 0 "NoError" 1 "AlarmMaskIsActive" ;
VAL_ 2632384038 ErrorCodeExecuteMacro3 0 "NoError" 1 "GeneralError" ;
VAL_ 2632384038 ErrorCodeLockUnlockMask3 0 "NoError" 1 "MaskNotLocked" ;
VAL_ 2632384038 ErrorCodeExecuteMacro2 0 "NoError" 1 "ObjectIdIsNoMacro" ;
VAL_ 2632384038 ErrorCodeLockUnlockMask2 0 "NoError" 1 "MaskAlreadyLocked" ;
VAL_ 2632384038 SupportedGraphicMode 2 "Colour256" 1 "Colour16" 0 "Monocrome" ;
VAL_ 2632384038 MemoryStatus 1 "NotEnoughMemoryAvailable" 0 "EnoughMemoryMayBeAvailable" ;
VAL_ 2632384038 ErrorCodeExecuteMacro1 0 "NoError" 1 "ObjectIdNotExist" ;
VAL_ 2632384038 ErrorCodeLockUnlockMask1 0 "NoError" 1 "MaskNotVisibleOrInvalidObjectId" ;
VAL_ 2632384038 ButtonObjectID 2 "KeyIsStillPressed" 1 "KeyHasBeenPressed" 0 "KeyHasBeenReleased" ;
VAL_ 2632384038 KeyObjectID 2 "KeyIsStillPressed" 1 "KeyHasBeenPressed" 0 "KeyHasBeenReleased" ;
VAL_ 2632384038 ErrorCodeSetObjectLabel6 0 "NoError" 1 "GeneralError" ;
VAL_ 2632384038 ErrorCodeSetObjectLabel5 0 "NoError" 1 "DesignatorReferencesInvalidObjects" ;
VAL_ 2632384038 ErrorCodeDeleteObjectPool2 1 "GeneralError" 0 "NoErrors" ;
VAL_ 2632384038 ErrorCodeAudioVolume2 1 "GeneralError" 0 "NoErrors" ;
VAL_ 2632384038 ErrorCodeControlAudioDevice2 1 "GeneralError" 0 "NoErrors" ;
VAL_ 2632384038 ErrorCodeEndOfObjectPool3 1 "GeneralError" 0 "NoErrors" ;
VAL_ 2632384038 AuxPreferredAssignmentRespError5 0 "NoErrors" 1 "GeneralError" ;
VAL_ 2632384038 ErrorCodeSetObjectLabel4 0 "NoError" 1 "InvalidDesignatorObjectReference" ;
VAL_ 2632384038 AuxPreferredAssignmentRespError4 0 "NoErrors" 1 "DuplicateObjectIdOfAuxFct" ;
VAL_ 2632384038 ErrorCodeSetObjectLabel3 0 "NoError" 1 "InvalidFontType" ;
VAL_ 2632384038 AuxPreferredAssignmentRespError3 0 "NoErrors" 1 "InputObjectID(s)NotValid" ;
VAL_ 2632384038 ErrorCodeSetObjectLabel2 0 "NoError" 1 "InvalidStringVariableObjectId" ;
VAL_ 2632384038 AuxPreferredAssignmentRespError2 0 "NoErrors" 1 "FunctionObjectID(s)NotValid" ;
VAL_ 2632384038 ErrorCodeEndOfObjectPool2 1 "VTRanOutOfMemoryDuringTransfer" 0 "NoErrors" ;
VAL_ 2632384038 VersionNumberISO11783Part6 50 "VersionOfThe50PublishedEdition" 49 "VersionOfThe48PublishedEdition" 48 "VersionOfThe47PublishedEdition" 47 "VersionOfThe46PublishedEdition" 46 "VersionOfThe45PublishedEdition" 45 "VersionOfThe44PublishedEdition" 44 "VersionOfThe43PublishedEdition" 43 "VersionOfThe42PublishedEdition" 42 "VersionOfThe41PublishedEdition" 41 "VersionOfThe40PublishedEdition" 40 "VersionOfThe39PublishedEdition" 39 "VersionOfThe38PublishedEdition" 38 "VersionOfThe37PublishedEdition" 37 "VersionOfThe36PublishedEdition" 36 "VersionOfThe35PublishedEdition" 35 "VersionOfThe34PublishedEdition" 34 "VersionOfThe33PublishedEdition" 33 "VersionOfThe32PublishedEdition" 32 "VersionOfThe31PublishedEdition" 31 "VersionOfThe30PublishedEdition" 30 "VersionOfThe29PublishedEdition" 29 "VersionOfThe28PublishedEdition" 28 "VersionOfThe27PublishedEdition" 27 "VersionOfThe26PublishedEdition" 26 "VersionOfThe25PublishedEdition" 25 "VersionOfThe24PublishedEdition" 24 "VersionOfThe23PublishedEdition" 23 "VersionOfThe22PublishedEdition" 22 "VersionOfThe21PublishedEdition" 21 "VersionOfThe20PublishedEdition" 20 "VersionOfThe19PublishedEdition" 19 "VersionOfThe18PublishedEdition" 18 "VersionOfThe17PublishedEdition" 17 "VersionOfThe16PublishedEdition" 16 "VersionOfThe15PublishedEdition" 15 "VersionOfThe14PublishedEdition" 14 "VersionOfThe13PublishedEdition" 13 "VersionOfThe12PublishedEdition" 12 "VersionOfThe11PublishedEdition" 11 "VersionOfThe10PublishedEdition" 10 "VersionOfThe9PublishedEdition" 9 "VersionOfThe8PublishedEdition" 8 "VersionOfThe7PublishedEdition" 7 "VersionOfThe6PublishedEdition" 6 "VersionOfThe5PublishedEdition" 5 "VersionOfThe4PublishedEdition" 4 "VersionOfThe3PublishedEdition" 3 "VersionOfThe2PublishedEdition" 2 "VersionOfThe1PublishedEdition" 1 "FDIS_Version" 0 "Hannover Agritechnica 2001 limit" ;
VAL_ 2632384038 LockUnlockCommand 0 "UnlockMask" 1 "LockMask" ;
VAL_ 2632384038 ErrorCodeSetObjectLabel1 0 "NoError" 1 "InvalidObjectId" ;
VAL_ 2632384038 ErrorCodeDeleteObjectPool1 1 "DeletionError" 0 "NoErrors" ;
VAL_ 2632384038 ErrorCodeAudioVolume1 1 "AudioDeviceIsBusy" 0 "NoErrors" ;
VAL_ 2632384038 ErrorCodeControlAudioDevice1 1 "AudioDeviceIsBusy" 0 "NoErrors" ;
VAL_ 2632384038 AuxPreferredAssignmentRespError1 0 "NoErrors" 1 "AuxiliaryInputUnit(s)NotValid" ;
VAL_ 2632384038 ErrorCodeEndOfObjectPool1 0 "NoErrors" 1 "ErrorsInTheObjectPool" ;
VAL_ 2632384038 ButtonActivationCode 2 "ButtonIsStillHeld" 1 "ButtonHasBeenLatched" 0 "ButtonHasBeenUnlatched" 3 "ButtonPressAborted" ;
VAL_ 2632384038 KeyActivationCode 2 "KeyIsStillPressed" 1 "KeyHasBeenPressed" 0 "KeyHasBeenReleased" 3 "KeyPressAborted" ;
VAL_ 2632384038 TerminationCause 1 "AudioWasTerminated" ;
VAL_ 2632384038 BootTime 255 "Information not available" ;
VAL_ 2632384038 VTFunctionVTtoECU 253 "VTUnsupportedVTFunction" 34 "AuxiliaryPreferredAssignmentResponse" 180 "ChangeChildPositionResponse" 179 "ChangeStringValueResponse" 240 "VTObjectPoolErrorMessage" 196 "GetWindowMaskDataResponse" 8 "VTChangeStringValue" 7 "VTChangeSoftKeyMask" 6 "VTChangeActiveMask" 5 "VTChangeNumericValue" 4 "VTESC" 3 "VTSelectInputObject" 33 "AuxiliaryInputStatus" 254 "VTStatusMessage" 224 "GetVersionsResponse" 210 "DeleteVersionResponse" 209 "LoadVersionResponse" 208 "StoreVersionResponse" 199 "GetHardwareResponse" 195 "GetTextFontDataResponse" 194 "GetNumberOfSoftKeysResponse" 192 "GetMemoryResponse" 178 "DeleteObjectPoolResponse" 177 "ChangeListItemResponse" 176 "ChangePriorityResponse" 175 "ChangeAttributeResponse" 174 "ChangeSoftKeyMaskResponse" 173 "ChangeActiveMaskResponse" 172 "ChangeFillAttributesResponse" 171 "ChangeLineAttributesResponse" 170 "ChangeFontAttributesResponse" 169 "ChangeEndPointResponse" 168 "ChangeNumericValueResponse" 167 "ChangeBackgroundColourResponse" 166 "ChangeSizeResponse" 165 "ChangeChildLocationResponse" 164 "SetAudioVolumeResponse" 163 "ControlAudioDeviceResponse" 162 "SelectInputObjectResponse" 161 "EnableDisableObjectResponse" 160 "ShowHideObjectResponse" 146 "ESCResponse" 32 "AuxiliaryAssignmentCommand" 18 "EndOfObjectPoolResponse" 2 "PointingEvent" 1 "ButtonActivation" 0 "SoftKeyActivation" 181 "SetObjectLabelResponse" 182 "ChangePolygonPointResponse" 183 "ChangePolygonScaleResponse" 184 "GraphicsContextCommandResponse" 185 "GetAttributeValueResponse" 186 "SelectColourMapResponse" 9 "VTOnUserLayoutHideShow" 10 "VTControlAudioDeviceTermination" 35 "AuxiliaryInputMaintenance" 189 "LockUnlockMaskResponse" 190 "ExecuteMacroResponse" 37 "AuxiliaryInputStatusEnableCommand" 193 "GetSupported WideCharsResponse" 36 "AuxiliaryAssignmentCommandType2" 38 "AuxiliaryInputStatusType2" 187 "IdentifyVTResponse" 197 "GetSupportedObjectsResponse" 188 "ExecuteExtendedMacroResponse" 211 "ExtendedGetVersionsResponse" 212 "ExtendedStoreVersionResponse" 213 "ExtendedLoadVersionResponse" 214 "ExtendedDeleteVersionResponse" 39 " AuxiliaryCapabilitiesResponse" ;
VAL_ 2565340800 VTFunctionECUtoVT 193 "GetSupported WideChars" 37 "AuxiliaryInputStatusEnableCommandResponse" 35 "AuxiliaryInputMaintenance" 190 "ExecuteMacro" 189 "LockUnlockMask" 34 "AuxiliaryPreferredAssignment" 9 "DisplayActivationResponse" 186 "SelectColourMap" 185 "GetAttribute" 184 "GraphicsContextCommand" 183 "ChangePolygonScale" 182 "ChangePolygonPoint" 181 "SetObjectLabel" 0 "SoftKeyActivationResponse" 1 "ButtonActivationResponse" 2 "PointingEventResponse" 18 "EndOfObjectPool" 32 "AuxiliaryAssignmentResponse" 146 "ESC" 160 "ShowHideObject" 161 "EnableDisableObject" 162 "SelectInputObject" 163 "ControlAudioDevice" 164 "SetAudioVolume" 165 "ChangeChildLocation" 166 "ChangeSize" 167 "ChangeBackgroundColour" 168 "ChangeNumericValue" 169 "ChangeEndPoint" 170 "ChangeFontAttributes" 171 "ChangeLineAttributes" 172 "ChangeFillAttributes" 173 "ChangeActiveMask" 174 "ChangeSoftKeyMask" 175 "ChangeAttribute" 176 "ChangePriority" 177 "ChangeListItem" 178 "DeleteObjectPool" 192 "GetMemory" 194 "GetNumberOfSoftKeys" 195 "GetTextFontData" 199 "GetHardware" 208 "StoreVersion" 209 "LoadVersion" 210 "DeleteVersion" 223 "GetVersions" 255 "WorkingSetMaintenance" 179 "ChangeStringValue" 3 "VTSelectInputObjectResponse" 4 "VTESCResponse" 5 "VTChangeNumericValueResponse" 6 "VTChangeActiveMaskResponse" 7 "VTChangeSoftKeyMaskResponse" 196 "GetFillAndLineData" 17 "ObjectPoolTransfer" 180 "ChangeChildPosition" 8 "VTChangeStringValueResponse" ;
VAL_ 2565340800 KeyActivationCode 2 "KeyIsStillPressed" 1 "KeyHasBeenPressed" 0 "KeyHasBeenReleased" 3 "KeyPressAborted" ;
VAL_ 2565340800 KeyObjectParentID 2 "KeyIsStillPressed" 1 "KeyHasBeenPressed" 0 "KeyHasBeenReleased" ;
VAL_ 2565340800 KeyObjectID 2 "KeyIsStillPressed" 1 "KeyHasBeenPressed" 0 "KeyHasBeenReleased" ;
VAL_ 2565340800 SoftKeyCode 0 "AlarmACK" ;
VAL_ 2565340800 ButtonActivationCode 2 "ButtonIsStillHeld" 1 "ButtonHasBeenLatched" 0 "ButtonHasBeenUnlatched" 3 "ButtonPressAborted" ;
VAL_ 2565340800 ButtonObjectID 2 "KeyIsStillPressed" 1 "KeyHasBeenPressed" 0 "KeyHasBeenReleased" ;
VAL_ 2565340800 ButtonObjectParentID 2 "KeyIsStillPressed" 1 "KeyHasBeenPressed" 0 "KeyHasBeenReleased" ;
VAL_ 2565340800 TouchState 0 "Released" 1 "Pressed" 2 "Held" 255 "Pressed" ;
VAL_ 2565340800 VTSelectInputObjectStatus 1 "ObjectIsSelected" 0 "ObjectIsDeselected" ;
VAL_ 2565340800 AssignmentErrorNotAccepted 0 "AssignmentAccepted" 1 "Rejected_InputAlreadyAssigned" ;
VAL_ 2565340800 IsEnabled 0 "Disabled" 1 "Enabled" 255 "InputTypeIsAnalog" ;
VAL_ 2565340800 ShowOrHide 0 "Hide" 1 "Show" ;
VAL_ 2565340800 EnableOrDisable 0 "Disable" 1 "Enable" ;
VAL_ 2565340800 MaskType 1 "Data" 2 "Alarm" ;
VAL_ 2565340800 SubCommandID 0 "SetGraphicsCursor" 1 "MoveGraphicsCursor" 2 "SetForegroundColour" 3 "SetBackgroundColour" 4 "SetLineAttributesObjectID" 5 "SetFillAttributesObjectID" 6 "SetFontAttributesID" 7 "EraseRectangle" 8 "DrawPoint" 9 "DrawLine" 10 "DrawRectangle" 11 "DrawClosedEllipse" 12 "DrawPolygon" 13 "DrawText" 14 "PanViewport" 15 "ZoomViewport" 16 "PanAndZoomViewport" 17 "ChangeViewportSize" 18 "DrawVTObject" 19 "CopyCanvasToPictureGraphic" 20 "CopyViewportToPictureGraphic" ;
VAL_ 2565340800 LockUnlockCommand 0 "UnlockMask" 1 "LockMask" ;
VAL_ 2565537534 RqstedPGN 255 "NotAvailable" ;
VAL_ 2632777470 ConnectionAbortReason 7 "AnyOtherError" 6 "DuplicateSequenceNumber" 5 "BadSequenceNumber" 4 "UnexpectedDataTransferPacket" 3 "Timeout_CloseSession" 2 "NoFreeSystemResources" 1 "AlreadyInConnManagedSession" ;
VAL_ 2632777470 ControlByte 32 "BAM" 255 "Abort" 19 "EoMACK" 17 "CTS" 16 "RTS" ;
VAL_ 2632777470 PGNumber 255 "NotAvailable" ;
VAL_ 2365458686 LimitStatusReporting 1 "Facility available" 0 "Facility not available" ;
VAL_ 2365458686 SpeedInfo_EngineSpeed 0 "EngineSpeedInfoNotAvailable" 1 "EngineSpeedInfoAvailable" ;
VAL_ 2365458686 SpeedInfo_GroundBasedSpeed 0 "GndBasedSpeedInfoNotAvailable" 1 "GndBasedSpeedInfoAvailable" ;
VAL_ 2365458686 SpeedInfo_WheelBasedSpeed 1 "WheelBasedSpeedInfoAvailable" 0 "WheelBasedSpeedInfoNotAvailable" ;
VAL_ 2365458686 PowerMgt_MaintainPower 1 "MainPwrMgtAvailable" 0 "MainPwrMgtNotAvailable" ;
VAL_ 2365458686 PowerMgt_MaxTimeTractorPower 0 "MaxTimeTractorPwrMgtNotAvailable" 1 "MaxTimeTractorPwrMgtAvailable" ;
VAL_ 2365458686 PowerMgt_KeySwitch 0 "KeySwitchPwrMgtNotAvailable" 1 "KeySwitchPwrMgtAvailable" ;
VAL_ 2365458686 TractorClass 0 "TECU_Class_1" 1 "TECU_Class_2" 2 "TECU_Class_3" 3 "NotAvailable" ;
VAL_ 2365458686 LanguageCmdStorageInTractorECU 0 "LangCmdNotAvailableInTractorECU" 1 "LangCmdAvailableInTractorECU" ;
VAL_ 2365458686 Lighting_MinimalSet 0 "MinSetNotAvailable" 1 "MinSetAvailable" ;
VAL_ 2365458686 PTOInfo_RearShaftEngagement 0 "PTOInfo_RearShaftEgtNotAvailable" 1 "PTOInfo_RearShaftEgtAvailable" ;
VAL_ 2365458686 PTOInfo_RearShaftSpeed 0 "PTOInfo_RearShaftSpdNotAvailable" 1 "PTOInfo_RearShaftSpdAvailable" ;
VAL_ 2365458686 HitchInfo_RearInWork 0 "HitchInfo_RearInWorkNotAvailable" 1 "HitchInfo_RearInWorkAvailable" ;
VAL_ 2365458686 HitchInfo_RearPosition 0 "HitchInfo_RearInPosNotAvailable" 1 "HitchInfo_RearInPosAvailable" ;
VAL_ 2365458686 EstimatedOrMeasuredAuxValveState 0 "EstOrMeasAuxValStatNotAvailable" 1 "EstOrMeasAuxValStatAvailable" ;
VAL_ 2365458686 Light_FullImplLightingMessageSet 0 "FullImplLightMsgSetNotAvailable" 1 "FullImplLightMsgSetAvailable" ;
VAL_ 2365458686 AddHitchParameter_RearDraft 0 "HitchInfo_RearDraftNotAvailable" 1 "HitchInfo_RearDraftAvailable" ;
VAL_ 2365458686 SpeedAndDist_WheelBasedDirection 0 "WheelBasedDirectionNotAvailable" 1 "WheelBasedDirectionAvailable" ;
VAL_ 2365458686 SpeedAndDist_WheelBasedDistance 0 "WheelBasedDistanceNotAvailable" 1 "WheelBasedDistanceAvailable" ;
VAL_ 2365458686 SpeedAndDist_GndBasedDirection 0 "GndBasedDirectionNotAvailable" 1 "GndBasedDirectionAvailable" ;
VAL_ 2365458686 SpeedAndDist_GndBasedDistance 0 "GndBasedDistanceNotAvailable" 1 "GndBasedDistanceAvailable" ;
VAL_ 2365458686 TimeDate 0 "TimeAndDateNotAvailable" 1 "TimeAndDateAvailable" ;
VAL_ 2365458686 AuxiliaryValveCmd 0 "AuxiliaryValveCmdsNotAvailable" 1 "AuxiliaryValveCmdsAvailable" ;
VAL_ 2365458686 PTOCmd_RearPTOEngagementCmd 0 "RearPTOEgtCmdNotAvailable" 1 "RearPTOEgtCmdAvailable" ;
VAL_ 2365458686 PTOCmd_RearPTOSpeedCmd 0 "RearPTOSpeedCmdNotAvailable" 1 "RearPTOSpeedCmdAvailable" ;
VAL_ 2365458686 HitchCmd_RearHitchPosition 0 "HitchRearPosNotAvailable" 1 "HitchRearPosAvailable" ;
VAL_ 2365458686 NavigPseudorangeNoiseStatistic 0 "NavigPsdoNoiseStatNotAvailable" 1 "NavigPsdoNoiseStatAvailable" ;
VAL_ 2365458686 NavigSystemPositionData 0 "NavigSysPosDataNotAvailable" 1 "NavigSysPosDataAvailable" ;
VAL_ 2365458686 NavigSystemHighOutputPosition 0 "NavigSysHOutPosDataNotAvailable" 1 "NavigSysHOutPosDataAvailable" ;
VAL_ 2365458686 PTOCmd_FrontPTOEngagementCmd 0 "FrontPTOEgtCmdNotAvailable" 1 "FrontPTOEgtCmdAvailable" ;
VAL_ 2365458686 PTOCmd_FrontPTOSpeedCmd 0 "FrontPTOSpeedCmdNotAvailable" 1 "FrontPTOSpeedCmdAvailable" ;
VAL_ 2365458686 HitchCmd_FrontHitchPosition 0 "FrontHitchPosNotAvailable" 1 "FrontHitchPosAvailable" ;
VAL_ 2365458686 AddHitchParameter__FrontDraft 0 "FrontDraftNotAvailable" 1 "FrontDraftAvailable" ;
VAL_ 2365458686 PTOInfo_FrontShaftEngagement 0 "FrontShaftEgtNotAvailable" 1 "FrontShaftEgtAvailable" ;
VAL_ 2365458686 PTOInfo_FrontShaftSpeed 0 "FrontShaftSpeedNotAvailable" 1 "FrontShaftSpeedAvailable" ;
VAL_ 2365458686 HitchInfo_FrontInWork 0 "FrontInWorkNotAvailable" 1 "FrontInWorkAvailable" ;
VAL_ 2365458686 HitchInfo_FrontPosition 0 "FrontPositionNotAvailable" 1 "FrontPositionAvailable" ;
VAL_ 2365458928 LimitStatusReporting 1 "Facility available" 0 "Facility not available" ;
VAL_ 2365458928 SpeedInfo_EngineSpeed 0 "EngineSpeedInfoNotAvailable" 1 "EngineSpeedInfoAvailable" ;
VAL_ 2365458928 SpeedInfo_GroundBasedSpeed 0 "GndBasedSpeedInfoNotAvailable" 1 "GndBasedSpeedInfoAvailable" ;
VAL_ 2365458928 SpeedInfo_WheelBasedSpeed 0 "WheelBasedSpeedInfoNotAvailable" 1 "WheelBasedSpeedInfoAvailable" ;
VAL_ 2365458928 PowerMgt_MaintainPower 0 "MainPwrMgtNotAvailable" 1 "MainPwrMgtAvailable" ;
VAL_ 2365458928 PowerMgt_MaxTimeTractorPower 0 "MaxTimeTractorPwrMgtNotAvailable" 1 "MaxTimeTractorPwrMgtAvailable" ;
VAL_ 2365458928 PowerMgt_KeySwitch 0 "KeySwitchPwrMgtNotAvailable" 1 "KeySwitchPwrMgtAvailable" ;
VAL_ 2365458928 TractorClass 0 "TECU_Class_1" 1 "TECU_Class_2" 2 "TECU_Class_3" 3 "NotAvailable" ;
VAL_ 2365458928 LanguageCmdStorageInTractorECU 0 "LangCmdNotAvailableInTractorECU" 1 "LangCmdAvailableInTractorECU" ;
VAL_ 2365458928 Lighting_MinimalSet 0 "MinSetNotAvailable" 1 "MinSetAvailable" ;
VAL_ 2365458928 PTOInfo_RearShaftEngagement 0 "PTOInfo_RearShaftEgtNotAvailable" 1 "PTOInfo_RearShaftEgtAvailable" ;
VAL_ 2365458928 PTOInfo_RearShaftSpeed 0 "PTOInfo_RearShaftSpdNotAvailable" 1 "PTOInfo_RearShaftSpdAvailable" ;
VAL_ 2365458928 HitchInfo_RearInWork 0 "HitchInfo_RearInWorkNotAvailable" 1 "HitchInfo_RearInWorkAvailable" ;
VAL_ 2365458928 HitchInfo_RearPosition 0 "HitchInfo_RearInPosNotAvailable" 1 "HitchInfo_RearInPosAvailable" ;
VAL_ 2365458928 EstimatedOrMeasuredAuxValveState 0 "EstOrMeasAuxValStatNotAvailable" 1 "EstOrMeasAuxValStatAvailable" ;
VAL_ 2365458928 Light_FullImplLightingMessageSet 0 "FullImplLightMsgSetNotAvailable" 1 "FullImplLightMsgSetAvailable" ;
VAL_ 2365458928 AddHitchParameter_RearDraft 0 "HitchInfo_RearDraftNotAvailable" 1 "HitchInfo_RearDraftAvailable" ;
VAL_ 2365458928 SpeedAndDist_WheelBasedDirection 0 "WheelBasedDirectionNotAvailable" 1 "WheelBasedDirectionAvailable" ;
VAL_ 2365458928 SpeedAndDist_WheelBasedDistance 0 "WheelBasedDistanceNotAvailable" 1 "WheelBasedDistanceAvailable" ;
VAL_ 2365458928 SpeedAndDist_GndBasedDirection 0 "GndBasedDirectionNotAvailable" 1 "GndBasedDirectionAvailable" ;
VAL_ 2365458928 SpeedAndDist_GndBasedDistance 0 "GndBasedDistanceNotAvailable" 1 "GndBasedDistanceAvailable" ;
VAL_ 2365458928 TimeDate 0 "TimeAndDateNotAvailable" 1 "TimeAndDateAvailable" ;
VAL_ 2365458928 AuxiliaryValveCmd 0 "AuxiliaryValveCmdsNotAvailable" 1 "AuxiliaryValveCmdsAvailable" ;
VAL_ 2365458928 PTOCmd_RearPTOEngagementCmd 0 "RearPTOEgtCmdNotAvailable" 1 "RearPTOEgtCmdAvailable" ;
VAL_ 2365458928 PTOCmd_RearPTOSpeedCmd 0 "RearPTOSpeedCmdNotAvailable" 1 "RearPTOSpeedCmdAvailable" ;
VAL_ 2365458928 HitchCmd_RearHitchPosition 0 "HitchRearPosNotAvailable" 1 "HitchRearPosAvailable" ;
VAL_ 2365458928 NavigPseudorangeNoiseStatistic 0 "NavigPsdoNoiseStatNotAvailable" 1 "NavigPsdoNoiseStatAvailable" ;
VAL_ 2365458928 NavigSystemPositionData 0 "NavigSysPosDataNotAvailable" 1 "NavigSysPosDataAvailable" ;
VAL_ 2365458928 NavigSystemHighOutputPosition 0 "NavigSysHOutPosDataNotAvailable" 1 "NavigSysHOutPosDataAvailable" ;
VAL_ 2365458928 PTOCmd_FrontPTOEngagementCmd 0 "FrontPTOEgtCmdNotAvailable" 1 "FrontPTOEgtCmdAvailable" ;
VAL_ 2365458928 PTOCmd_FrontPTOSpeedCmd 0 "FrontPTOSpeedCmdNotAvailable" 1 "FrontPTOSpeedCmdAvailable" ;
VAL_ 2365458928 HitchCmd_FrontHitchPosition 0 "FrontHitchPosNotAvailable" 1 "FrontHitchPosAvailable" ;
VAL_ 2365458928 AddHitchParameter__FrontDraft 0 "FrontDraftNotAvailable" 1 "FrontDraftAvailable" ;
VAL_ 2365458928 PTOInfo_FrontShaftEngagement 0 "FrontShaftEgtNotAvailable" 1 "FrontShaftEgtAvailable" ;
VAL_ 2365458928 PTOInfo_FrontShaftSpeed 0 "FrontShaftSpeedNotAvailable" 1 "FrontShaftSpeedAvailable" ;
VAL_ 2365458928 HitchInfo_FrontInWork 0 "FrontInWorkNotAvailable" 1 "FrontInWorkAvailable" ;
VAL_ 2365458928 HitchInfo_FrontPosition 0 "FrontPositionNotAvailable" 1 "FrontPositionAvailable" ;
VAL_ 2566787056 TimeFormatCmd 0 "Hour24" 1 "Hour12" 3 "NoAction" ;
VAL_ 2566787056 DecimalSymbolCmd 0 "CommaIsUsed" 1 "PointIsUsed" 3 "NoAction" ;
VAL_ 2566787056 DateFormatCmd 0 "ddmmyyyy" 1 "ddyyyymm" 2 "mmyyyydd" 3 "mmddyyyy" 4 "yyyymmdd" 5 "yyyyddmm" ;
VAL_ 2566787056 MassUnitCmd 0 "Metric" 1 "Imperial" 2 "TonsPounds" 3 "NoAction" ;
VAL_ 2566787056 VolumeUnitCmd 0 "Metric" 1 "Imperial" 2 "US" 3 "NoAction" ;
VAL_ 2566787056 AreaUnitCmd 0 "Metric" 1 "Imperial" 3 "NoAction" ;
VAL_ 2566787056 DistanceUnitCmd 0 "Metric" 1 "Imperial" 3 "NoAction" ;
VAL_ 2566787056 UnitsSystem 0 "Metric" 1 "Imperial" 2 "US" 3 "NoAction" ;
VAL_ 2566787056 ForceUnits 0 "Metric" 1 "Imperial" 2 "Reserved" 3 "NoAction" ;
VAL_ 2566787056 PressureUnits 0 "Metric" 1 "Imperial" 2 "Reserved" 3 "NoAction" ;
VAL_ 2566787056 TemperatureUnits 0 "Metric" 1 "Imperial" 2 "Reserved" 3 "NoAction" ;
VAL_ 2365460720 Valve0LimitStatus 7 "Not available" 6 "Non-recoverable Fault" 5 "Reserver" 4 "Reserved" 3 "Limited Low" 2 "Limited High" 1 "Operator Limited" 0 "Not limited" ;
VAL_ 2365460720 Valve0ValveState 0 "Blocked" 1 "Extend" 2 "Retract" 3 "Floating" 14 "ErrorIndication" 15 "DoNotCare" ;
VAL_ 2365460720 Valve0FailSafeMode 0 "Block" 1 "Float" 2 "ErrorIndication" 3 "NotAvailable" ;
VAL_ 2365460976 Valve1LimitStatus 7 "Not available" 6 "Non-recoverable Fault" 5 "Reserver" 4 "Reserved" 3 "Limited Low" 2 "Limited High" 1 "Operator Limited" 0 "Not limited" ;
VAL_ 2365460976 Valve1ValveState 0 "Blocked" 1 "Extend" 2 "Retract" 3 "Floating" 14 "ErrorIndication" 15 "DoNotCare" ;
VAL_ 2365460976 Valve1FailSafeMode 0 "Block" 1 "Float" 2 "ErrorIndication" 3 "NotAvailable" ;
VAL_ 2365461232 Valve2LimitStatus 7 "Not available" 6 "Non-recoverable Fault" 5 "Reserver" 4 "Reserved" 3 "Limited Low" 2 "Limited High" 1 "Operator Limited" 0 "Not limited" ;
VAL_ 2365461232 Valve2ValveState 0 "Blocked" 1 "Extend" 2 "Retract" 3 "Floating" 14 "ErrorIndication" 15 "DoNotCare" ;
VAL_ 2365461232 Valve2FailSafeMode 0 "Block" 1 "Float" 2 "ErrorIndication" 3 "NotAvailable" ;
VAL_ 2365461488 Valve3LimitStatus 7 "Not available" 6 "Non-recoverable Fault" 5 "Reserver" 4 "Reserved" 3 "Limited Low" 2 "Limited High" 1 "Operator Limited" 0 "Not limited" ;
VAL_ 2365461488 Valve3ValveState 0 "Blocked" 1 "Extend" 2 "Retract" 3 "Floating" 14 "ErrorIndication" 15 "DoNotCare" ;
VAL_ 2365461488 Valve3FailSafeMode 0 "Block" 1 "Float" 2 "ErrorIndication" 3 "NotAvailable" ;
VAL_ 2365464816 Valve0LimitStatus 7 "Not available" 6 "Non-recoverable Fault" 5 "Reserver" 4 "Reserved" 3 "Limited Low" 2 "Limited High" 1 "Operator Limited" 0 "Not limited" ;
VAL_ 2365465072 Valve1LimitStatus 7 "Not available" 6 "Non-recoverable Fault" 5 "Reserver" 4 "Reserved" 3 "Limited Low" 2 "Limited High" 1 "Operator Limited" 0 "Not limited" ;
VAL_ 2365465328 Valve2LimitStatus 7 "Not available" 6 "Non-recoverable Fault" 5 "Reserver" 4 "Reserved" 3 "Limited Low" 2 "Limited High" 1 "Operator Limited" 0 "Not limited" ;
VAL_ 2365465584 Valve3LimitStatus 7 "Not available" 6 "Non-recoverable Fault" 5 "Reserver" 4 "Reserved" 3 "Limited Low" 2 "Limited High" 1 "Operator Limited" 0 "Not limited" ;
VAL_ 2365473264 DaytimeRunningLightCmd 0 "Deactivate" 1 "Activate" 3 "DoNotCare" ;
VAL_ 2365473264 AlternateHeadLightCmd 0 "Deactivate" 1 "Activate" 3 "DoNotCare" ;
VAL_ 2365473264 LowBeamHeadLightCmd 0 "Deactivate" 1 "Activate" 3 "DoNotCare" ;
VAL_ 2365473264 HighBeamHeadLightCmd 0 "Deactivate" 1 "Activate" 3 "DoNotCare" ;
VAL_ 2365473264 FrontFogLightCmd 0 "Deactivate" 1 "Activate" 3 "DoNotCare" ;
VAL_ 2365473264 RotatingBeaconLightCmd 0 "Deactivate" 1 "Acitvate" 3 "DoNotCare" ;
VAL_ 2365473264 RightTurnSignalLightCmd 0 "Deactivate" 1 "Activate" 3 "DoNotCare" ;
VAL_ 2365473264 LeftTurnSignalLightCmd 0 "Deactivate" 1 "Activate" 3 "DoNotCare" ;
VAL_ 2365473264 BackUpLightAndAlarmHornCmd 0 "Deacitvate" 1 "Acitvate" 3 "DoNotCare" ;
VAL_ 2365473264 CentreStopLightCmd 0 "Deactivate" 1 "Acitvate" 3 "DoNotCare" ;
VAL_ 2365473264 RightStopLightCmd 0 "Deactivate" 1 "Acitvate" 3 "DoNotCare" ;
VAL_ 2365473264 LeftStopLightCmd 0 "Deactivate" 1 "Acitvate" 3 "DoNotCare" ;
VAL_ 2365473264 ImplementClearanceLightCmd 0 "Deactivate" 1 "Acitvate" 3 "DoNotCare" ;
VAL_ 2365473264 TractorClearanceLightCmd 0 "Deactivate" 1 "Acitvate" 3 "DoNotCare" ;
VAL_ 2365473264 ImplementMarkerLightCmd 0 "Deactivate" 1 "Acitvate" 3 "DoNotCare" ;
VAL_ 2365473264 TractorMarkerLightCmd 0 "Deactivate" 1 "Acitvate" 3 "DoNotCare" ;
VAL_ 2365473264 RearFogLightCmd 0 "Deactivate" 1 "Acitvate" 3 "DoNotCare" ;
VAL_ 2365473264 TractorUndersideWorkLightCmd 0 "Deactivate" 1 "Acitvate" 3 "DoNotCare" ;
VAL_ 2365473264 TractorRearLowWorkLightCmd 0 "Deactivate" 1 "Acitvate" 3 "DoNotCare" ;
VAL_ 2365473264 TractorRearHighWorkLightCmd 0 "Deactivate" 1 "Acitvate" 3 "DoNotCare" ;
VAL_ 2365473264 TractorSideLowWorkLightCmd 0 "Deactivate" 1 "Acitvate" 3 "DoNotCare" ;
VAL_ 2365473264 TractorSideHighWorkLightCmd 0 "Deactivate" 1 "Acitvate" 3 "DoNotCare" ;
VAL_ 2365473264 TractorFrontLowWorkLightCmd 0 "Deactivate" 1 "Acitvate" 3 "DoNotCare" ;
VAL_ 2365473264 TractorFrontHighWorkLightCmd 0 "Deactivate" 1 "Acitvate" 3 "DoNotCare" ;
VAL_ 2365473264 ImplementOEMOption2LightCmd 0 "Deactivate" 1 "Acitvate" 3 "DoNotCare" ;
VAL_ 2365473264 ImplementOEMOption1LightCmd 0 "Deactivate" 1 "Acitvate" 3 "DoNotCare" ;
VAL_ 2365473264 ImplementRightForwardLightCmd 0 "Deactivate" 1 "Acitvate" 3 "DoNotCare" ;
VAL_ 2365473264 ImplementLeftForwardLightCmd 0 "Deactivate" 1 "Acitvate" 3 "DoNotCare" ;
VAL_ 2365473264 LightingDataRequestCmd 0 "Deactivate" 1 "Acitvate" 3 "DoNotCare" ;
VAL_ 2365473264 ImplementRightFacingWorkLightCmd 0 "Deactivate" 1 "Acitvate" 3 "DoNotCare" ;
VAL_ 2365473264 ImplementLeftFacingWorkLightCmd 0 "Deactivate" 1 "Acitvate" 3 "DoNotCare" ;
VAL_ 2365473264 ImplementRearWorkLightCmd 0 "Deactivate" 1 "Acitvate" 3 "DoNotCare" ;
VAL_ 2365473534 RearPTOEngagementCmd 0 "DisengagePTO" 1 "EngangePTO" 3 "DoNotCare" ;
VAL_ 2365473534 FrontPTOEngagementCmd 0 "DisengagePTO" 1 "EngagePTO" 3 "DoNotCare" ;
VAL_ 2365473534 RearPTOEconomyModeCmd 0 "DisengagePTOEconomyMode" 1 "EngagePTOEconomyMode" 3 "DoNotCare" ;
VAL_ 2365473534 FrontPTOEconomyModeCmd 0 "DisengagePTOEconomyMode" 1 "EngagePTOEconomyMode" 3 "DoNotCare" ;
VAL_ 2365473534 RearPTOModeCmd 0 "Select540rpmMode" 1 "Select1000rpmMode" 3 "DoNotCare" ;
VAL_ 2365473534 FrontPTOModeCmd 0 "Select540rpmMode" 1 "Select1000rpmMode" 3 "DoNotCare" ;
VAL_ 2365473776 RearPTOShaftSpeedLimitStatus 7 "Not available" 6 "Non-recoverable Fault" 5 "Reserver" 4 "Reserved" 3 "Limited Low" 2 "Limited High" 1 "Operator Limited" 0 "Not limited" ;
VAL_ 2365473776 RearPTOModeRqStatus 3 "Not available" 2 "Error" 1 "Control Override" 0 "External Request accepted" ;
VAL_ 2365473776 RearPTOEngagementRqStatus 3 "Not available" 2 "Error" 1 "Control Override" 0 "External Request accepted" ;
VAL_ 2365473776 RearPTOEconomyModeRqStatus 3 "Not available" 2 "Error" 1 "Control Override" 0 "External Request accepted" ;
VAL_ 2365473776 RearPTOEconomyMode 0 "PTOEconomyModeIsDisengaged" 1 "PTOEconomyModeIsEngaged" 2 "ErrorIndication" 3 "NotAvailabel" ;
VAL_ 2365473776 RearPTOMode 0 "PTOModeIs540" 1 "PTOModeIs1000" 2 "ErrorIndication" 3 "NotAvailable" ;
VAL_ 2365473776 RearPTOEngagement 0 "PTODisengaged" 1 "PTOEngaged" 2 "ErrorIndication" 3 "NotAvailable" ;
VAL_ 2365474032 FrontPTOShaftSpeedLimitStatus 7 "Not available" 6 "Non-recoverable Fault" 5 "Reserver" 4 "Reserved" 3 "Limited Low" 2 "Limited High" 1 "Operator Limited" 0 "Not limited" ;
VAL_ 2365474032 FrontPTOModeRqStatus 3 "Not available" 2 "Error" 1 "Control Override" 0 "External Request accepted" ;
VAL_ 2365474032 FrontPTOEconomyModeRqStatus 3 "Not available" 2 "Error" 1 "Control Override" 0 "External Request accepted" ;
VAL_ 2365474032 FrontPTOEngagementRqStatus 3 "Not available" 2 "Error" 1 "Control Override" 0 "External Request accepted" ;
VAL_ 2365474032 FrontPTOEconomyMode 0 "PTOEconomyModeIsDisengaged" 1 "PTOEconomyModeIsEngaged" 2 "ErrorIndication" 3 "NotAvailable" ;
VAL_ 2365474032 FrontPTOMode 0 "PTOModeIs540" 1 "PTOModeIs1000" 2 "ErrorIndication" 3 "NotAvailable" ;
VAL_ 2365474032 FrontPTOEngagement 0 "PTODisengaged" 1 "PTOEngaged" 2 "ErrorIndication" 3 "NotAvailable" ;
VAL_ 2365474288 RearHitchPositionLimitStatus 7 "Not available" 6 "Non-recoverable Fault" 5 "Reserver" 4 "Reserved" 3 "Limited Low" 2 "Limited High" 1 "Operator Limited" 0 "Not limited" ;
VAL_ 2365474288 RearHitchInWorkIndication 0 "HitchPositionIsOutOfWork" 1 "HitchPositionIsInWork" 2 "ErrorIndication" 3 "NotAvailable" ;
VAL_ 2365474544 FrontHitchPositionLimitStatus 7 "Not available" 6 "Non-recoverable Fault" 5 "Reserver" 4 "Reserved" 3 "Limited Low" 2 "Limited High" 1 "Operator Limited" 0 "Not limited" ;
VAL_ 2365474544 FrontHitchInWorkIndication 0 "HitchPositionIsOutOfWork" 1 "HitchPositionIsInWorl" 2 "ErrorIndication" 3 "NotAvailable" ;
VAL_ 2566801406 MaintainActuatorPower 0 "NoFurtherRequirementForPWR" 1 "RequireForTwoMoreSecOfPWR" 3 "DoNotCare" ;
VAL_ 2566801406 MaintainECUPower 0 "NoFurtherRequireForECU_PWR" 1 "RequireForTwoMoreSecOfECU_PWR" 3 "DoNotCare" ;
VAL_ 2566801406 ImplementedWorkState 0 "ImplementIsNotReadyForFieldWork" 1 "ImplementIsReadyForFieldWork" 2 "ErrorIndicator" 3 "NotAvailable" ;
VAL_ 2566801406 ImplementedParkState 0 "ImplementMayNotBeDisconneted" 1 "ImplementMayBeDisconnected" 2 "ErrorIndicator" 3 "NotAvailable" ;
VAL_ 2566801406 ImplementTransportState 0 "ImplementMayNotBeTransported" 1 "ImplementMayBeTransported" 2 "ErrorIndication" 3 "NotAvailable" ;
VAL_ 2365475056 OperatorDirectionReversed 3 "Not available" 2 "Error" 1 "Reversed" 0 "Not reversed" ;
VAL_ 2365475056 WheelBasedDirection 0 "Reverse" 1 "Forward" 2 "ErrorIndicator" 3 "NotAvailable" ;
VAL_ 2365475056 KeySwitchState 0 "KeySwitchOff" 1 "KeySwitchNotOff" 2 "ErrorIndication" 3 "NotAvailable" ;
VAL_ 2365475056 StartStopState 0 "Stop or disable implement work" 1 "Start or enable implement work" 2 "Reserved" 3 "Don't Care" ;
VAL_ 2365475312 GroundBasedDirection 0 "Reverse" 1 "Forward" 2 "ErrorIndication" 3 "NotAvailable" ;
VAL_ 2583168284 TypeOfSystem 0 "GPS" 1 "GLONASS" 2 "GPS and GLONASS" 3 "GPS and SBAS(WAAS)" 4 "GPS and SBAS and GLONASS" ;
VAL_ 2583168284 GNSSMethod 0 "no GPS" 1 "GNSS fix" 2 "DGNSS fix" 3 "Precise GNSS" 4 "RTK fixed integer" 5 "RTK float" 6 "Estimated (DR) mode" 7 "Manual input" 8 "Simulate mode" 14 "Error" ;
VAL_ 2583168284 GNSSIntegrity 0 "No integrity checking" 1 "Safe" 2 "Caution" 3 "Unsafe" ;
VAL_ 2583168284 RefrenceStationType1 0 "GPS" 1 "GLONASS" 14 "Error" ;
VAL_ 2563309310 ConnectionAbortReason 7 "AnyOtherError" 6 "DuplicateSequenceNumber" 5 "BadSequenceNumber" 4 "UnexpectedDataTransferPacket" 3 "Timeout_CloseSession" 2 "NoFreeSystemResources" 1 "AlreadyInConnManagedSession" ;
VAL_ 2563309310 ControlByte 23 "EEoMA" 22 "EDPO" 21 "ECTS" 20 "ERTS" 255 "EAbort" ;
VAL_ 2563309310 PGNumber 255 "NotAvailable" ;
VAL_ 2364540144 EngStarterMode 0 "startNotRqed" 1 "starterActiveGearNotEngaged" 2 "starterActiveGearEngaged" 3 "strtFnshdStrtrNtActvAftrHvngBnA" 4 "strtrInhbtdDToEngAlreadyRunning" 5 "strtrInhbtdDTEngNtReadyForStart" 6 "strtrInhbtdDTDrvlnEnggdOthrTrns" 7 "strtrInhbtdDToActiveImmobilizer" 8 "strtrInhbtdDueToStarterOvertemp" 9 "1011Reserved" 12 "starterInhibitedReasonUnknown" 14 "error" 15 "notAvailable" ;
